VERSION ""

NS_ :

BS_:

BU_: PowertrainControlModule AtmosphericSensor SafetyRestraintSystem2 Aftertreatment_2_GasOutlet Aftertreatment_2_GasIntake DieselParticulateFilterControl Turbocharger SafetyRestraintSystem1 CabDisplay2 Aftertreatment_1_GasOutlet Aftertreatment_1_GasIntake OnBoardDataLogger OffBoardDiagnosticTool2 OffBoardDiagnosticTool1 FileServer ParkingBrakeController SeatController2 FanDriveController SteeringColumnUnit CommunicationUnitRadio CommunicationUnitSatellite CommunicationUnitCellular PropulsionBatteryCharger ChassisController2 ChassisController1 EngineValveControl AuxiliaryHeater2 AuxiliaryHeater1 ClutchUnit RampControl InformationSystem1 SuspensionSystemController2 OilSensor VehicleDynamicStability ExhaustEmissionController TransmissionDisplay2 TransmissionDisplay1 ClimateControl2 WaterPumpController RearAxleSteeringController LightingOperatorControl SeatController1 IgnitionController2 IgnitionController1 TirePressureController CabController2 CabController1 PneumaticSystemController SuspensionSystemController1 HydraulicPumpController EnduranceBrakingSystem RetarderExhaustEngine2 OnBoardDiagnosticUnit HeadwayController RetarderExhaustEngine1 CabDisplay1 ManagementComputer VirtualTerminal OffVehicleGateway PowerTakeOffFront HitchControl AuxiliaryValveControl BodyController TractorTrailerBridge1 StarterSystem ElectricalSystem VehicleSecurity VehicleNavigation AerodynamicControl ElectricalChargingSystem ClimateControl1 TripRecorder InstrumentCluster SuspensionDriveAxle2 SuspensionDriveAxle1 SuspensionSteerAxle SteeringController FuelSystem CruiseControl RetarderDriveline RetarderEngine BrakesDriveAxle2 BrakesDriveAxle1 BrakesSystemController BrakesSteerAxle AxleDrive2 AxleDrive1 AxleSteering PowerTakeOff ShiftConsoleSecondary ShiftConsolePrimary Transmission2 Transmission1 Engine2 Engine1

BO_ 2566786302 WSMEM: 8 Vector__XXX
 SG_ ReservedBit : 48|1@1+ (1,0) [0|0] "" Vector__XXX
 SG_ VehicleSystem5 m5 : 49|7@1+ (1,0) [0|127] "" Vector__XXX
 SG_ VehicleSystem4 m4 : 49|7@1+ (1,0) [0|127] "" Vector__XXX
 SG_ VehicleSystem3 m3 : 49|7@1+ (1,0) [0|127] "" Vector__XXX
 SG_ VehicleSystem2 m2 : 49|7@1+ (1,0) [0|127] "" Vector__XXX
 SG_ VehicleSystem1 m1 : 49|7@1+ (1,0) [0|127] "" Vector__XXX
 SG_ ArbitraryAddressCapable : 63|1@1+ (1,0) [0|1] "" Vector__XXX
 SG_ IndustryGroup M : 60|3@1+ (1,0) [0|7] "" Vector__XXX
 SG_ VehicleSystemInstance : 56|4@1+ (1,0) [0|15] "" Vector__XXX
 SG_ VehicleSystem m0 : 49|7@1+ (1,0) [0|127] "" Vector__XXX
 SG_ ECUInstance : 32|3@1+ (1,0) [0|7] "" Vector__XXX
 SG_ FunctionInstance : 35|5@1+ (1,0) [0|31] "" Vector__XXX
 SG_ Function : 40|8@1+ (1,0) [0|255] "" Vector__XXX
 SG_ ManufacturerCode : 21|11@1+ (1,0) [0|2047] "" Vector__XXX
 SG_ IdentityNumber : 0|21@1+ (1,0) [0|2097152] "" Vector__XXX

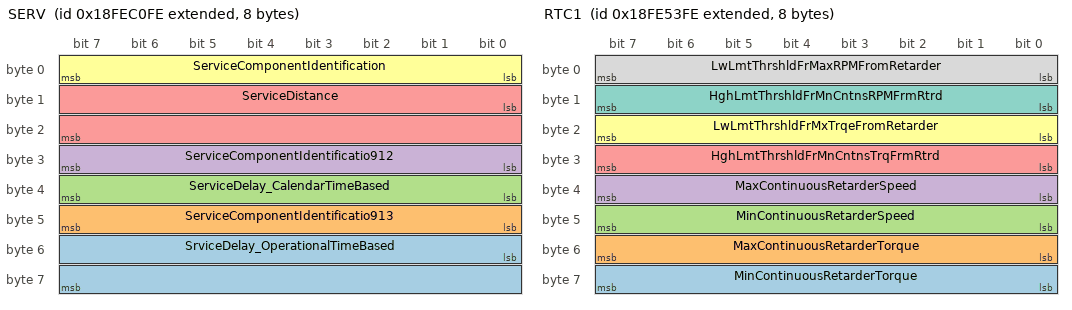
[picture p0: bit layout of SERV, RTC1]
BO_ 2566832382 SERV: 8 Vector__XXX
 SG_ SrviceDelay_OperationalTimeBased : 48|16@1+ (1,-32127) [-32127|32128] "h" Vector__XXX
 SG_ ServiceComponentIdentificatio913 : 40|8@1+ (1,0) [0|250] "ID" Vector__XXX
 SG_ ServiceDelay_CalendarTimeBased : 32|8@1+ (1,-125) [-125|125] "weeks" Vector__XXX
 SG_ ServiceComponentIdentificatio912 : 24|8@1+ (1,0) [0|250] "ID" Vector__XXX
 SG_ ServiceDistance : 8|16@1+ (5,-160635) [-160635|160640] "km" Vector__XXX
 SG_ ServiceComponentIdentification : 0|8@1+ (1,0) [0|250] "" Vector__XXX

BO_ 2633928446 S2: 8 Vector__XXX
 SG_ TimeSinceLastService : 8|16@1+ (1,-32127) [-32127|32128] "h" Vector__XXX
 SG_ ServiceComponentIdentification : 0|8@1+ (1,0) [0|250] "" Vector__XXX

BO_ 2566804478 RTC1: 8 Vector__XXX
 SG_ MinContinuousRetarderTorque : 56|8@1+ (1,-125) [-125|125] "%" Vector__XXX
 SG_ MaxContinuousRetarderTorque : 48|8@1+ (1,-125) [-125|125] "%" Vector__XXX
 SG_ MinContinuousRetarderSpeed : 40|8@1+ (32,0) [0|8000] "rpm" Vector__XXX
 SG_ MaxContinuousRetarderSpeed : 32|8@1+ (32,0) [0|8000] "rpm" Vector__XXX
 SG_ HghLmtThrshldFrMnCntnsTrqFrmRtrd : 24|8@1+ (1,-125) [-125|125] "%" Vector__XXX
 SG_ LwLmtThrshldFrMxTrqeFromRetarder : 16|8@1+ (1,-125) [-125|125] "%" Vector__XXX
 SG_ HghLmtThrshldFrMnCntnsRPMFrmRtrd : 8|8@1+ (32,0) [0|8000] "rpm" Vector__XXX
 SG_ LwLmtThrshldFrMaxRPMFromRetarder : 0|8@1+ (32,0) [0|8000] "rpm" Vector__XXX

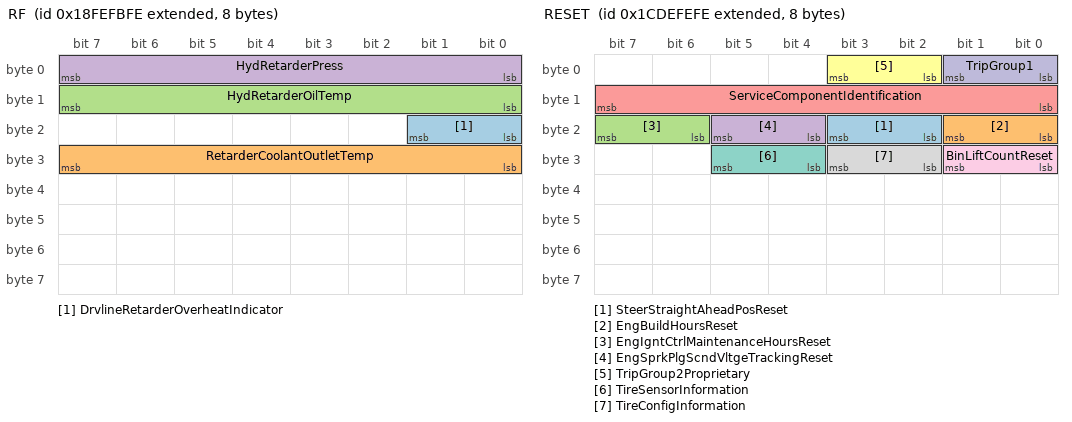
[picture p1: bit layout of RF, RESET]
BO_ 2566847486 RF: 8 Vector__XXX
 SG_ DrvlineRetarderOverheatIndicator : 16|2@1+ (1,0) [0|3] "" Vector__XXX
 SG_ RetarderCoolantOutletTemp : 24|8@1+ (1,-40) [-40|210] "캜" Vector__XXX
 SG_ HydRetarderOilTemp : 8|8@1+ (1,-40) [-40|210] "캜" Vector__XXX
 SG_ HydRetarderPress : 0|8@1+ (16,0) [0|4000] "kPa" Vector__XXX

BO_ 2631859966 RESET: 8 Vector__XXX
 SG_ SteerStraightAheadPosReset : 18|2@1+ (1,0) [0|3] "" Vector__XXX
 SG_ EngBuildHoursReset : 16|2@1+ (1,0) [0|3] "" Vector__XXX
 SG_ EngIgntCtrlMaintenanceHoursReset : 22|2@1+ (1,0) [0|3] "" Vector__XXX
 SG_ EngSprkPlgScndVltgeTrackingReset : 20|2@1+ (1,0) [0|3] "" Vector__XXX
 SG_ ServiceComponentIdentification : 8|8@1+ (1,0) [0|250] "" Vector__XXX
 SG_ TripGroup2Proprietary : 2|2@1+ (1,0) [0|3] "" Vector__XXX
 SG_ TireSensorInformation : 28|2@1+ (1,0) [0|3] "" Vector__XXX
 SG_ TireConfigInformation : 26|2@1+ (1,0) [0|3] "" Vector__XXX
 SG_ BinLiftCountReset : 24|2@1+ (1,0) [0|3] "" Vector__XXX
 SG_ TripGroup1 : 0|2@1+ (1,0) [0|3] "" Vector__XXX

BO_ 2566840830 RC: 19 Vector__XXX
 SG_ PercentTorqueAtPeakTorquePoint5 : 144|8@1+ (1,-125) [-125|0] "%" Vector__XXX
 SG_ ReferenceRetarderTorque : 128|16@1+ (1,0) [0|64255] "Nm" Vector__XXX
 SG_ RetarderSpeedAtPeakTorquePoint5 : 112|16@1+ (0.125,0) [0|8031.875] "rpm" Vector__XXX
 SG_ PercentTorqueAtPoint4 : 104|8@1+ (1,-125) [-125|0] "%" Vector__XXX
 SG_ RetarderSpeedAtPoint4 : 88|16@1+ (0.125,0) [0|8031.875] "rpm" Vector__XXX
 SG_ PercentTorqueAtPoint3 : 80|8@1+ (1,-125) [-125|0] "%" Vector__XXX
 SG_ RetarderSpeedAtPoint3 : 64|16@1+ (0.125,0) [0|8031.875] "rpm" Vector__XXX
 SG_ PercentTorqueAtMaxSpeedPoint2 : 56|8@1+ (1,-125) [-125|0] "%" Vector__XXX
 SG_ MaxRetarderSpeedPoint2 : 40|16@1+ (0.125,0) [0|8031.875] "rpm" Vector__XXX
 SG_ PercentTorqueAtIdlePoint1 : 32|8@1+ (1,-125) [-125|0] "%" Vector__XXX
 SG_ RetarderSpeedAtIdlePoint1 : 16|16@1+ (0.125,0) [0|8031.875] "rpm" Vector__XXX
 SG_ RetarderCtrlMethod : 8|8@1+ (1,0) [0|250] "steps" Vector__XXX
 SG_ RetarderLocation : 4|4@1+ (1,0) [0|15] "" Vector__XXX
 SG_ RetarderType : 0|4@1+ (1,0) [0|15] "" Vector__XXX

BO_ 2633930238 RBI: 8 Vector__XXX
 SG_ EngOperationTimeSinceRebuild : 0|32@1+ (1,0) [0|4211081215] "s" Vector__XXX

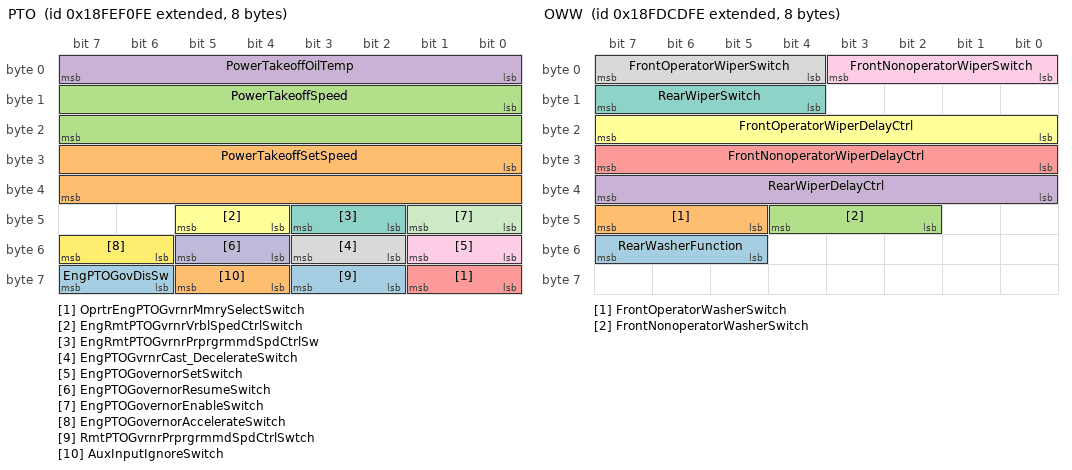
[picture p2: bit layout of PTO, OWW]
BO_ 2566844670 PTO: 8 Vector__XXX
 SG_ EngPTOGovDisSw : 62|2@1+ (1,0) [0|3] "" Vector__XXX
 SG_ PowerTakeoffSetSpeed : 24|16@1+ (0.125,0) [0|8031.875] "rpm" Vector__XXX
 SG_ PowerTakeoffSpeed : 8|16@1+ (0.125,0) [0|8031.875] "rpm" Vector__XXX
 SG_ PowerTakeoffOilTemp : 0|8@1+ (1,-40) [-40|210] "캜" Vector__XXX
 SG_ OprtrEngPTOGvrnrMmrySelectSwitch : 56|2@1+ (1,0) [0|3] "" Vector__XXX
 SG_ EngRmtPTOGvrnrVrblSpedCtrlSwitch : 44|2@1+ (1,0) [0|3] "" Vector__XXX
 SG_ EngRmtPTOGvrnrPrprgrmmdSpdCtrlSw : 42|2@1+ (1,0) [0|3] "" Vector__XXX
 SG_ EngPTOGvrnrCast_DecelerateSwitch : 50|2@1+ (1,0) [0|3] "" Vector__XXX
 SG_ EngPTOGovernorSetSwitch : 48|2@1+ (1,0) [0|3] "" Vector__XXX
 SG_ EngPTOGovernorResumeSwitch : 52|2@1+ (1,0) [0|3] "" Vector__XXX
 SG_ EngPTOGovernorEnableSwitch : 40|2@1+ (1,0) [0|3] "" Vector__XXX
 SG_ EngPTOGovernorAccelerateSwitch : 54|2@1+ (1,0) [0|3] "" Vector__XXX
 SG_ RmtPTOGvrnrPrprgrmmdSpdCtrlSwtch : 58|2@1+ (1,0) [0|3] "" Vector__XXX
 SG_ AuxInputIgnoreSwitch : 60|2@1+ (1,0) [0|3] "" Vector__XXX

BO_ 2566770174 OWW: 8 Vector__XXX
 SG_ RearWasherFunction : 53|3@1+ (1,0) [0|7] "" Vector__XXX
 SG_ FrontOperatorWasherSwitch : 45|3@1+ (1,0) [0|7] "" Vector__XXX
 SG_ FrontNonoperatorWasherSwitch : 42|3@1+ (1,0) [0|7] "" Vector__XXX
 SG_ RearWiperDelayCtrl : 32|8@1+ (0.4,0) [0|100] "%" Vector__XXX
 SG_ FrontNonoperatorWiperDelayCtrl : 24|8@1+ (0.4,0) [0|100] "%" Vector__XXX
 SG_ FrontOperatorWiperDelayCtrl : 16|8@1+ (0.4,0) [0|100] "%" Vector__XXX
 SG_ RearWiperSwitch : 12|4@1+ (1,0) [0|15] "" Vector__XXX
 SG_ FrontOperatorWiperSwitch : 4|4@1+ (1,0) [0|15] "" Vector__XXX
 SG_ FrontNonoperatorWiperSwitch : 0|4@1+ (1,0) [0|15] "" Vector__XXX

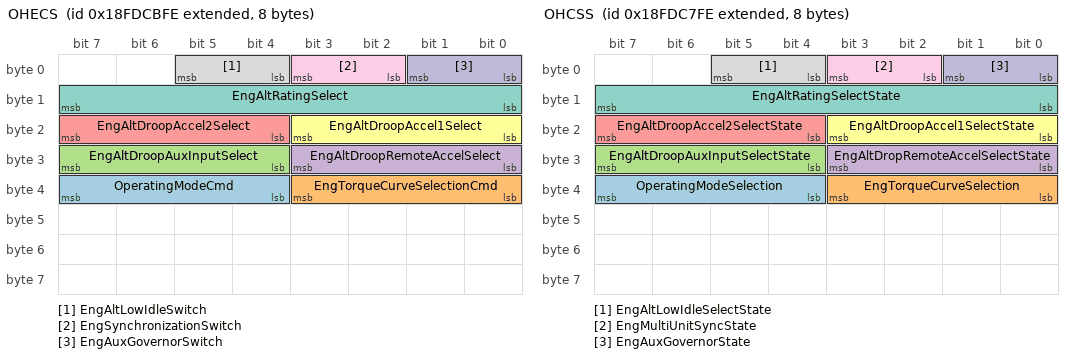
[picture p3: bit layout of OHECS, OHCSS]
BO_ 2566769662 OHECS: 8 Vector__XXX
 SG_ OperatingModeCmd : 36|4@1+ (1,0) [0|15] "" Vector__XXX
 SG_ EngTorqueCurveSelectionCmd : 32|4@1+ (1,0) [0|15] "" Vector__XXX
 SG_ EngAltDroopAuxInputSelect : 28|4@1+ (1,0) [0|15] "" Vector__XXX
 SG_ EngAltDroopRemoteAccelSelect : 24|4@1+ (1,0) [0|15] "" Vector__XXX
 SG_ EngAltDroopAccel2Select : 20|4@1+ (1,0) [0|15] "" Vector__XXX
 SG_ EngAltDroopAccel1Select : 16|4@1+ (1,0) [0|15] "" Vector__XXX
 SG_ EngAltRatingSelect : 8|8@1+ (1,0) [0|255] "" Vector__XXX
 SG_ EngAltLowIdleSwitch : 4|2@1+ (1,0) [0|3] "" Vector__XXX
 SG_ EngSynchronizationSwitch : 2|2@1+ (1,0) [0|3] "" Vector__XXX
 SG_ EngAuxGovernorSwitch : 0|2@1+ (1,0) [0|3] "" Vector__XXX

BO_ 2566768638 OHCSS: 8 Vector__XXX
 SG_ OperatingModeSelection : 36|4@1+ (1,0) [0|15] "" Vector__XXX
 SG_ EngTorqueCurveSelection : 32|4@1+ (1,0) [0|15] "" Vector__XXX
 SG_ EngAltDroopAuxInputSelectState : 28|4@1+ (1,0) [0|15] "" Vector__XXX
 SG_ EngAltDropRemoteAccelSelectState : 24|4@1+ (1,0) [0|15] "" Vector__XXX
 SG_ EngAltDroopAccel2SelectState : 20|4@1+ (1,0) [0|15] "" Vector__XXX
 SG_ EngAltDroopAccel1SelectState : 16|4@1+ (1,0) [0|15] "" Vector__XXX
 SG_ EngAltRatingSelectState : 8|8@1+ (1,0) [0|255] "" Vector__XXX
 SG_ EngAltLowIdleSelectState : 4|2@1+ (1,0) [0|3] "" Vector__XXX
 SG_ EngMultiUnitSyncState : 2|2@1+ (1,0) [0|3] "" Vector__XXX
 SG_ EngAuxGovernorState : 0|2@1+ (1,0) [0|3] "" Vector__XXX

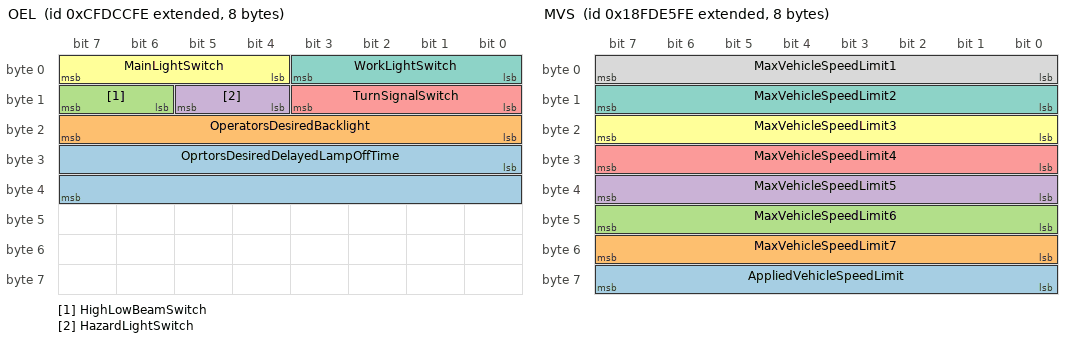
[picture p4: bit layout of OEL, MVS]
BO_ 2365443326 OEL: 8 Vector__XXX
 SG_ OprtorsDesiredDelayedLampOffTime : 24|16@1+ (1,0) [0|64255] "s" Vector__XXX
 SG_ OperatorsDesiredBacklight : 16|8@1+ (0.4,0) [0|100] "%" Vector__XXX
 SG_ HighLowBeamSwitch : 14|2@1+ (1,0) [0|3] "" Vector__XXX
 SG_ HazardLightSwitch : 12|2@1+ (1,0) [0|3] "" Vector__XXX
 SG_ TurnSignalSwitch : 8|4@1+ (1,0) [0|15] "" Vector__XXX
 SG_ MainLightSwitch : 4|4@1+ (1,0) [0|15] "" Vector__XXX
 SG_ WorkLightSwitch : 0|4@1+ (1,0) [0|15] "" Vector__XXX

BO_ 2566776318 MVS: 8 Vector__XXX
 SG_ AppliedVehicleSpeedLimit : 56|8@1+ (1,0) [0|250] "km/h" Vector__XXX
 SG_ MaxVehicleSpeedLimit7 : 48|8@1+ (1,0) [0|250] "km/h" Vector__XXX
 SG_ MaxVehicleSpeedLimit6 : 40|8@1+ (1,0) [0|250] "km/h" Vector__XXX
 SG_ MaxVehicleSpeedLimit5 : 32|8@1+ (1,0) [0|250] "km/h" Vector__XXX
 SG_ MaxVehicleSpeedLimit4 : 24|8@1+ (1,0) [0|250] "km/h" Vector__XXX
 SG_ MaxVehicleSpeedLimit3 : 16|8@1+ (1,0) [0|250] "km/h" Vector__XXX
 SG_ MaxVehicleSpeedLimit2 : 8|8@1+ (1,0) [0|250] "km/h" Vector__XXX
 SG_ MaxVehicleSpeedLimit1 : 0|8@1+ (1,0) [0|250] "km/h" Vector__XXX

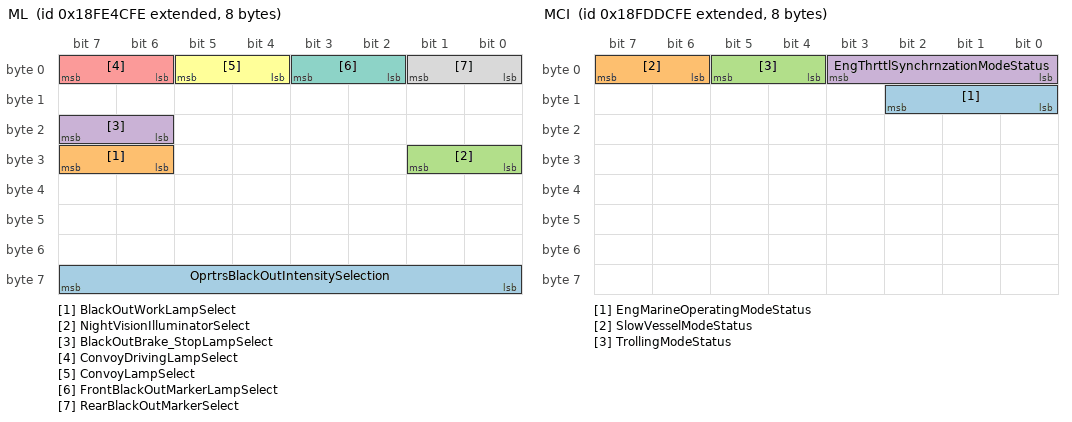
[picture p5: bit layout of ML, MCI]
BO_ 2566802686 ML: 8 Vector__XXX
 SG_ OprtrsBlackOutIntensitySelection : 56|8@1+ (0.4,0) [0|100] "%" Vector__XXX
 SG_ BlackOutWorkLampSelect : 30|2@1+ (1,0) [0|3] "" Vector__XXX
 SG_ NightVisionIlluminatorSelect : 24|2@1+ (1,0) [0|3] "" Vector__XXX
 SG_ BlackOutBrake_StopLampSelect : 22|2@1+ (1,0) [0|3] "" Vector__XXX
 SG_ ConvoyDrivingLampSelect : 6|2@1+ (1,0) [0|3] "" Vector__XXX
 SG_ ConvoyLampSelect : 4|2@1+ (1,0) [0|3] "" Vector__XXX
 SG_ FrontBlackOutMarkerLampSelect : 2|2@1+ (1,0) [0|3] "" Vector__XXX
 SG_ RearBlackOutMarkerSelect : 0|2@1+ (1,0) [0|3] "" Vector__XXX

BO_ 2566774014 MCI: 8 Vector__XXX
 SG_ EngMarineOperatingModeStatus : 8|3@1+ (1,0) [0|7] "" Vector__XXX
 SG_ SlowVesselModeStatus : 6|2@1+ (1,0) [0|3] "" Vector__XXX
 SG_ TrollingModeStatus : 4|2@1+ (1,0) [0|3] "" Vector__XXX
 SG_ EngThrttlSynchrnzationModeStatus : 0|4@1+ (1,0) [0|15] "" Vector__XXX

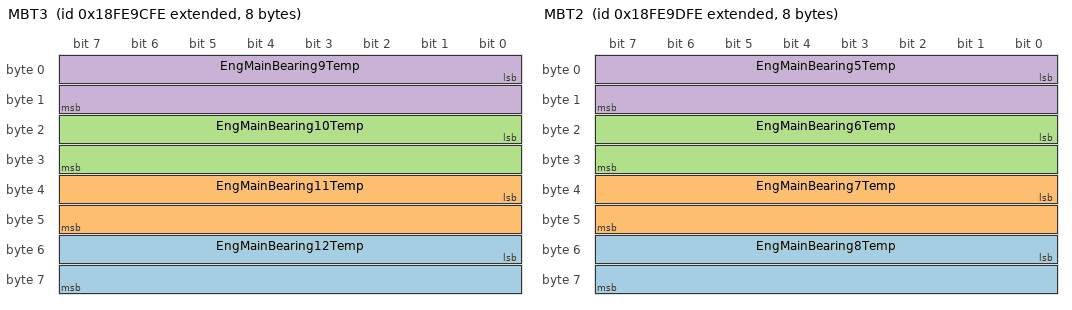
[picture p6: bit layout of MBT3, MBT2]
BO_ 2566823166 MBT3: 8 Vector__XXX
 SG_ EngMainBearing12Temp : 48|16@1+ (0.03125,-273) [-273|1734.96875] "캜" Vector__XXX
 SG_ EngMainBearing11Temp : 32|16@1+ (0.03125,-273) [-273|1734.96875] "캜" Vector__XXX
 SG_ EngMainBearing10Temp : 16|16@1+ (0.03125,-273) [-273|1734.96875] "캜" Vector__XXX
 SG_ EngMainBearing9Temp : 0|16@1+ (0.03125,-273) [-273|1734.96875] "캜" Vector__XXX

BO_ 2566823422 MBT2: 8 Vector__XXX
 SG_ EngMainBearing8Temp : 48|16@1+ (0.03125,-273) [-273|1734.96875] "캜" Vector__XXX
 SG_ EngMainBearing7Temp : 32|16@1+ (0.03125,-273) [-273|1734.96875] "캜" Vector__XXX
 SG_ EngMainBearing6Temp : 16|16@1+ (0.03125,-273) [-273|1734.96875] "캜" Vector__XXX
 SG_ EngMainBearing5Temp : 0|16@1+ (0.03125,-273) [-273|1734.96875] "캜" Vector__XXX

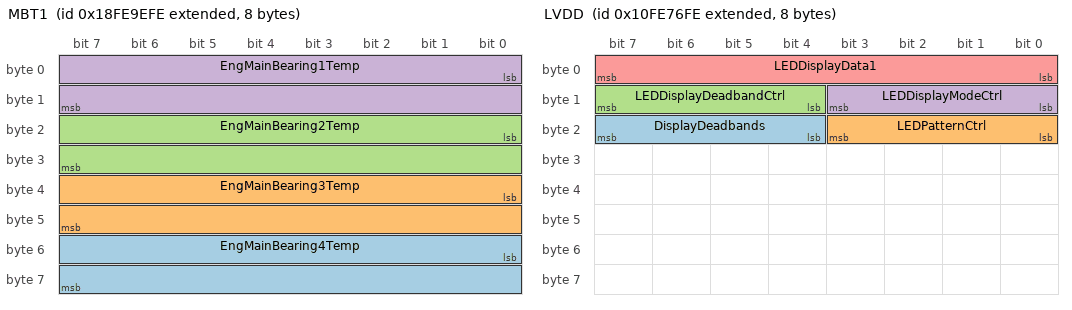
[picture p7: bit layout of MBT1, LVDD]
BO_ 2566823678 MBT1: 8 Vector__XXX
 SG_ EngMainBearing4Temp : 48|16@1+ (0.03125,-273) [-273|1734.96875] "캜" Vector__XXX
 SG_ EngMainBearing3Temp : 32|16@1+ (0.03125,-273) [-273|1734.96875] "캜" Vector__XXX
 SG_ EngMainBearing2Temp : 16|16@1+ (0.03125,-273) [-273|1734.96875] "캜" Vector__XXX
 SG_ EngMainBearing1Temp : 0|16@1+ (0.03125,-273) [-273|1734.96875] "캜" Vector__XXX

BO_ 2432595710 LVDD: 8 Vector__XXX
 SG_ DisplayDeadbands : 20|4@1+ (1,0) [0|15] "" Vector__XXX
 SG_ LEDPatternCtrl : 16|4@1+ (1,0) [0|15] "" Vector__XXX
 SG_ LEDDisplayDeadbandCtrl : 12|4@1+ (1,0) [0|15] "" Vector__XXX
 SG_ LEDDisplayModeCtrl : 8|4@1+ (1,0) [0|15] "" Vector__XXX
 SG_ LEDDisplayData1 : 0|8@1+ (1,0) [0|255] "" Vector__XXX

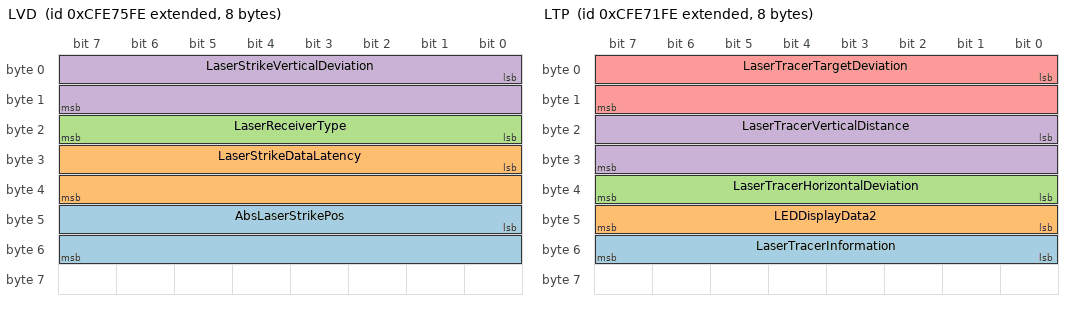
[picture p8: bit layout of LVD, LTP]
BO_ 2365486590 LVD: 8 Vector__XXX
 SG_ AbsLaserStrikePos : 40|16@1+ (0.1,0) [0|6425.5] "mm" Vector__XXX
 SG_ LaserStrikeDataLatency : 24|16@1+ (5.12E-005,0) [0|3.289856] "s" Vector__XXX
 SG_ LaserReceiverType : 16|8@1+ (1,0) [0|250] "" Vector__XXX
 SG_ LaserStrikeVerticalDeviation : 0|16@1+ (0.1,-3200) [-3200|3225.5] "mm" Vector__XXX

BO_ 2365485566 LTP: 8 Vector__XXX
 SG_ LaserTracerInformation : 48|8@1+ (1,0) [0|255] "" Vector__XXX
 SG_ LEDDisplayData2 : 40|8@1+ (1,0) [0|255] "" Vector__XXX
 SG_ LaserTracerHorizontalDeviation : 32|8@1+ (1,0) [0|200] "%" Vector__XXX
 SG_ LaserTracerVerticalDistance : 16|16@1+ (0.1,0) [0|6400] "mm" Vector__XXX
 SG_ LaserTracerTargetDeviation : 0|16@1+ (0.1,-3200) [-3200|3225.5] "mm" Vector__XXX

BO_ 2633939454 LTFI: 22 Vector__XXX
 SG_ TripDriveFuelEconomy : 160|16@1+ (0.001953125,0) [0|125.498046875] "km/L" Vector__XXX
 SG_ TripCruiseFuelUsed : 128|32@1+ (0.5,0) [0|2105540607.5] "l" Vector__XXX
 SG_ TripVehicleIdleFuelUsed : 96|32@1+ (0.5,0) [0|2105540607.5] "l" Vector__XXX
 SG_ TripPTOGovernorNonmovingFuelUsed : 64|32@1+ (0.5,0) [0|2105540607.5] "l" Vector__XXX
 SG_ TripPTOGovernorMovingFuelUsed : 32|32@1+ (0.5,0) [0|2105540607.5] "l" Vector__XXX
 SG_ TripDriveFuelUsed : 0|32@1+ (0.5,0) [0|2105540607.5] "l" Vector__XXX

BO_ 2365486334 LSP: 8 Vector__XXX
 SG_ BldeHeightSetPointHighResolution : 16|32@1+ (1E-007,-209.7152) [-209.7152|209.7152] "m" Vector__XXX
 SG_ ModifyLevelingSystemSetPoint : 0|16@1+ (0.1,-3200) [-3200|3225.5] "mm" Vector__XXX

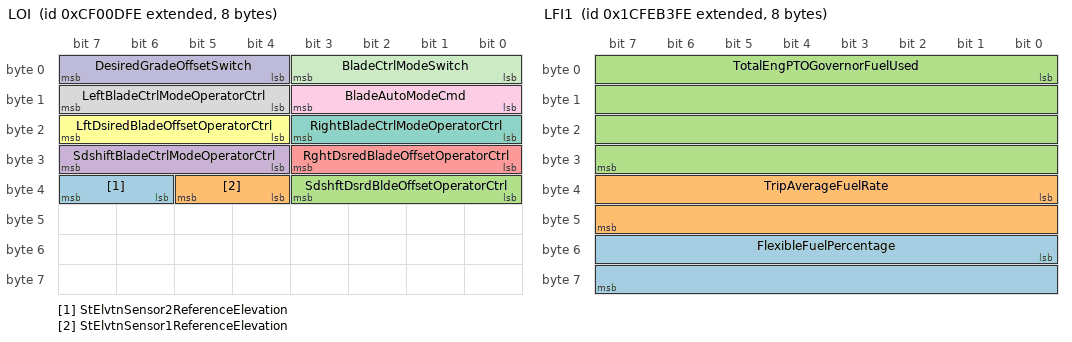
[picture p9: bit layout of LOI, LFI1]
BO_ 2364542462 LOI: 8 Vector__XXX
 SG_ StElvtnSensor2ReferenceElevation : 38|2@1+ (1,0) [0|3] "" Vector__XXX
 SG_ StElvtnSensor1ReferenceElevation : 36|2@1+ (1,0) [0|3] "" Vector__XXX
 SG_ SdshftDsrdBldeOffsetOperatorCtrl : 32|4@1+ (1,0) [0|15] "" Vector__XXX
 SG_ SdshiftBladeCtrlModeOperatorCtrl : 28|4@1+ (1,0) [0|15] "" Vector__XXX
 SG_ RghtDsredBladeOffsetOperatorCtrl : 24|4@1+ (1,0) [0|15] "" Vector__XXX
 SG_ LftDsiredBladeOffsetOperatorCtrl : 20|4@1+ (1,0) [0|15] "" Vector__XXX
 SG_ RightBladeCtrlModeOperatorCtrl : 16|4@1+ (1,0) [0|15] "" Vector__XXX
 SG_ LeftBladeCtrlModeOperatorCtrl : 12|4@1+ (1,0) [0|15] "" Vector__XXX
 SG_ BladeAutoModeCmd : 8|4@1+ (1,0) [0|15] "" Vector__XXX
 SG_ DesiredGradeOffsetSwitch : 4|4@1+ (1,0) [0|15] "" Vector__XXX
 SG_ BladeCtrlModeSwitch : 0|4@1+ (1,0) [0|15] "" Vector__XXX

BO_ 2365486078 LMP: 8 Vector__XXX
 SG_ MastPos : 0|16@1+ (0.1,-3200) [-3200|3225.5] "mm" Vector__XXX

BO_ 2633937918 LFI1: 8 Vector__XXX
 SG_ FlexibleFuelPercentage : 48|16@1+ (0.0025,0) [0|100] "%" Vector__XXX
 SG_ TripAverageFuelRate : 32|16@1+ (0.05,0) [0|3212.75] "l/h" Vector__XXX
 SG_ TotalEngPTOGovernorFuelUsed : 0|32@1+ (0.5,0) [0|2105540607.5] "l" Vector__XXX

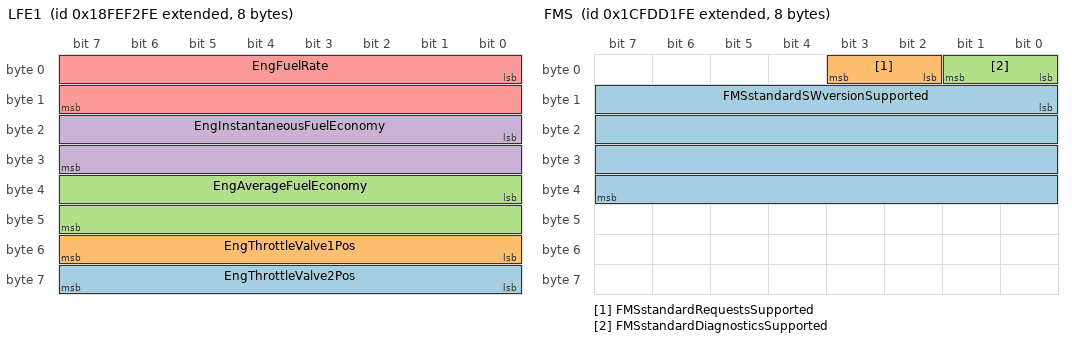
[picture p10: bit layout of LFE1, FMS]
BO_ 2566845182 LFE1: 8 Vector__XXX
 SG_ EngThrottleValve2Pos : 56|8@1+ (0.4,0) [0|100] "%" Vector__XXX
 SG_ EngThrottleValve1Pos : 48|8@1+ (0.4,0) [0|100] "%" Vector__XXX
 SG_ EngAverageFuelEconomy : 32|16@1+ (0.001953125,0) [0|125.498046875] "km/L" Vector__XXX
 SG_ EngInstantaneousFuelEconomy : 16|16@1+ (0.001953125,0) [0|125.498046875] "km/L" Vector__XXX
 SG_ EngFuelRate : 0|16@1+ (0.05,0) [0|3212.75] "l/h" Vector__XXX

BO_ 2566842878 LFC1: 8 Vector__XXX
 SG_ EngTotalFuelUsed : 32|32@1+ (0.5,0) [0|2105540607.5] "l" Vector__XXX
 SG_ EngTripFuel : 0|32@1+ (0.5,0) [0|2105540607.5] "l" Vector__XXX

BO_ 2633883646 FWD: 8 Vector__XXX
 SG_ FrontWheelDriveActuatorStatus : 0|2@1+ (1,0) [0|3] "" Vector__XXX

BO_ 2633880062 FMS: 8 Vector__XXX
 SG_ FMSstandardSWversionSupported : 8|32@1+ (1,0) [0|255] "" Vector__XXX
 SG_ FMSstandardRequestsSupported : 2|2@1+ (1,0) [0|3] "" Vector__XXX
 SG_ FMSstandardDiagnosticsSupported : 0|2@1+ (1,0) [0|3] "" Vector__XXX

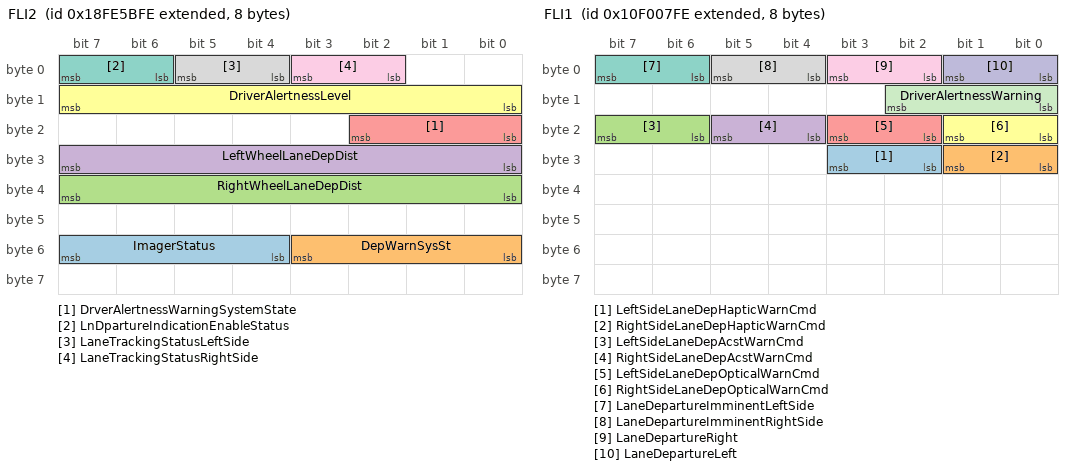
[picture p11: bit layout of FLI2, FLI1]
BO_ 2566806526 FLI2: 8 Vector__XXX
 SG_ ImagerStatus : 52|4@1+ (1,0) [0|15] "" Vector__XXX
 SG_ DepWarnSysSt : 48|4@1+ (1,0) [0|15] "" Vector__XXX
 SG_ RightWheelLaneDepDist : 32|8@1+ (1,-125) [-125|125] "cm" Vector__XXX
 SG_ LeftWheelLaneDepDist : 24|8@1+ (1,-125) [-125|125] "cm" Vector__XXX
 SG_ DrverAlertnessWarningSystemState : 16|3@1+ (1,0) [0|7] "" Vector__XXX
 SG_ DriverAlertnessLevel : 8|8@1+ (0.4,0) [0|100] "%" Vector__XXX
 SG_ LnDpartureIndicationEnableStatus : 6|2@1+ (1,0) [0|3] "" Vector__XXX
 SG_ LaneTrackingStatusLeftSide : 4|2@1+ (1,0) [0|3] "" Vector__XXX
 SG_ LaneTrackingStatusRightSide : 2|2@1+ (1,0) [0|3] "" Vector__XXX

BO_ 2431649790 FLI1: 8 Vector__XXX
 SG_ LeftSideLaneDepHapticWarnCmd : 26|2@1+ (1,0) [0|3] "" Vector__XXX
 SG_ RightSideLaneDepHapticWarnCmd : 24|2@1+ (1,0) [0|3] "" Vector__XXX
 SG_ LeftSideLaneDepAcstWarnCmd : 22|2@1+ (1,0) [0|3] "" Vector__XXX
 SG_ RightSideLaneDepAcstWarnCmd : 20|2@1+ (1,0) [0|3] "" Vector__XXX
 SG_ LeftSideLaneDepOpticalWarnCmd : 18|2@1+ (1,0) [0|3] "" Vector__XXX
 SG_ RightSideLaneDepOpticalWarnCmd : 16|2@1+ (1,0) [0|3] "" Vector__XXX
 SG_ LaneDepartureImminentLeftSide : 6|2@1+ (1,0) [0|3] "" Vector__XXX
 SG_ LaneDepartureImminentRightSide : 4|2@1+ (1,0) [0|3] "" Vector__XXX
 SG_ LaneDepartureRight : 2|2@1+ (1,0) [0|3] "" Vector__XXX
 SG_ LaneDepartureLeft : 0|2@1+ (1,0) [0|3] "" Vector__XXX
 SG_ DriverAlertnessWarning : 8|3@1+ (1,0) [0|7] "" Vector__XXX

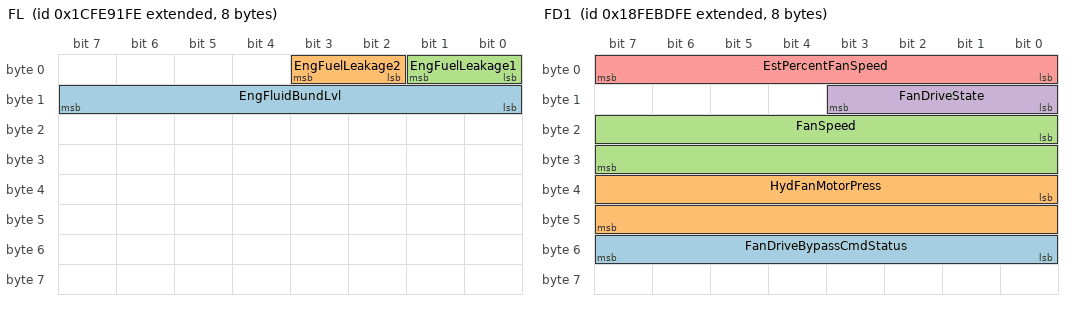
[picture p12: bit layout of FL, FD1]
BO_ 2633929214 FL: 8 Vector__XXX
 SG_ EngFluidBundLvl : 8|8@1+ (0.4,0) [0|100] "%" Vector__XXX
 SG_ EngFuelLeakage2 : 2|2@1+ (1,0) [0|3] "" Vector__XXX
 SG_ EngFuelLeakage1 : 0|2@1+ (1,0) [0|3] "" Vector__XXX

BO_ 2566831614 FD1: 8 Vector__XXX
 SG_ FanDriveBypassCmdStatus : 48|8@1+ (0.4,0) [0|100] "%" Vector__XXX
 SG_ HydFanMotorPress : 32|16@1+ (0.5,0) [0|32127.5] "kPa" Vector__XXX
 SG_ FanSpeed : 16|16@1+ (0.125,0) [0|8031.875] "rpm" Vector__XXX
 SG_ FanDriveState : 8|4@1+ (1,0) [0|15] "" Vector__XXX
 SG_ EstPercentFanSpeed : 0|8@1+ (0.4,0) [0|100] "%" Vector__XXX

BO_ 2566820094 ETH: 8 Vector__XXX
 SG_ EngTorqueLimit6AxleInput : 248|16@1+ (2,0) [0|128510] "Nm" Vector__XXX
 SG_ EngTorqueLimit5Switch : 232|16@1+ (1,0) [0|64255] "Nm" Vector__XXX
 SG_ EngTorqueLimit4Trans : 216|16@1+ (1,0) [0|64255] "Nm" Vector__XXX
 SG_ EngTorqueLimit3Trans : 200|16@1+ (1,0) [0|64255] "Nm" Vector__XXX
 SG_ TransGearRatio3 : 184|16@1+ (0.01,0) [0|642.55] "" Vector__XXX
 SG_ EngTorqueLimit2Trans : 168|16@1+ (1,0) [0|64255] "Nm" Vector__XXX
 SG_ TransGearRatio2 : 152|16@1+ (0.01,0) [0|642.55] "" Vector__XXX
 SG_ EngTorqueLimit1Trans : 136|16@1+ (1,0) [0|64255] "Nm" Vector__XXX
 SG_ TransGearRatio1 : 120|16@1+ (0.01,0) [0|642.55] "" Vector__XXX
 SG_ EngTorqueLimitFeature : 114|3@1+ (1,0) [0|7] "" Vector__XXX
 SG_ TorqueLimitingFeatureStatus : 112|2@1+ (1,0) [0|3] "" Vector__XXX
 SG_ CalibRecordDurationTime : 80|32@1+ (0.05,0) [0|210554060.75] "h" Vector__XXX
 SG_ CalibRecordStartYear : 72|8@1+ (1,1985) [1985|2235] "years" Vector__XXX
 SG_ CalibRecordStartDay : 64|8@1+ (0.25,0) [0.25|31.75] "days" Vector__XXX
 SG_ CalibRecordStartMonth : 56|8@1+ (1,0) [1|12] "months" Vector__XXX
 SG_ EngPeakTorque2 : 40|16@1+ (1,0) [0|64255] "Nm" Vector__XXX
 SG_ EngPeakTorque1 : 24|16@1+ (1,0) [0|64255] "Nm" Vector__XXX
 SG_ EngPower : 8|16@1+ (0.5,0) [0|32127.5] "kW" Vector__XXX
 SG_ NumberOfEngTorqueHistoryRecords : 0|8@1+ (1,0) [0|250] "records" Vector__XXX

BO_ 2364542206 ETC8: 8 Vector__XXX
 SG_ TransClutch_ConverterInputSpeed : 16|16@1+ (0.125,0) [0|8031.875] "rpm" Vector__XXX
 SG_ TransTorqueConverterRatio : 0|16@1+ (0.001,0) [0|64.255] "" Vector__XXX

BO_ 2566802174 ETC7: 8 Vector__XXX
 SG_ ManualModeInd : 54|2@1+ (1,0) [0|3] "" Vector__XXX
 SG_ TransAutoNeutralSt : 51|3@1+ (1,0) [0|7] "" Vector__XXX
 SG_ TransWarningIndicator : 42|2@1+ (1,0) [0|3] "" Vector__XXX
 SG_ TrnsRverseGearShiftInhibitStatus : 40|2@1+ (1,0) [0|3] "" Vector__XXX
 SG_ TransMode8Indicator : 38|2@1+ (1,0) [0|3] "" Vector__XXX
 SG_ TransMode7Indicator : 36|2@1+ (1,0) [0|3] "" Vector__XXX
 SG_ TransMode6Indicator : 34|2@1+ (1,0) [0|3] "" Vector__XXX
 SG_ TransMode5Indicator : 32|2@1+ (1,0) [0|3] "" Vector__XXX
 SG_ TransRequestedGearFeedback : 24|8@1+ (1,-125) [-125|125] "" Vector__XXX
 SG_ TransMode1Indicator : 22|2@1+ (1,0) [0|3] "" Vector__XXX
 SG_ TransMode2Indicator : 20|2@1+ (1,0) [0|3] "" Vector__XXX
 SG_ TransMode3Indicator : 18|2@1+ (1,0) [0|3] "" Vector__XXX
 SG_ TransMode4Indicator : 16|2@1+ (1,0) [0|3] "" Vector__XXX
 SG_ TransShiftInhibitIndicator : 14|2@1+ (1,0) [0|3] "" Vector__XXX
 SG_ TransEngCrankEnable : 12|2@1+ (1,0) [0|3] "" Vector__XXX
 SG_ ActiveShiftConsoleIndicator : 10|2@1+ (1,0) [0|3] "" Vector__XXX
 SG_ TransReadyForBrakeRelease : 8|2@1+ (1,0) [0|3] "" Vector__XXX
 SG_ TrnsRqstedRangeDisplayFlashState : 6|2@1+ (1,0) [0|3] "" Vector__XXX
 SG_ TrnsRqstedRangeDisplayBlankState : 4|2@1+ (1,0) [0|3] "" Vector__XXX
 SG_ TransServiceIndicator : 2|2@1+ (1,0) [0|3] "" Vector__XXX
 SG_ TransAirSupplyPressIndicator : 48|3@1+ (1,0) [0|7] "" Vector__XXX
 SG_ TransMode10Indicator : 46|2@1+ (1,0) [0|3] "" Vector__XXX
 SG_ TransMode9Indicator : 44|2@1+ (1,0) [0|3] "" Vector__XXX
 SG_ TrnsCrrentRangeDisplayBlankState : 0|2@1+ (1,0) [0|3] "" Vector__XXX

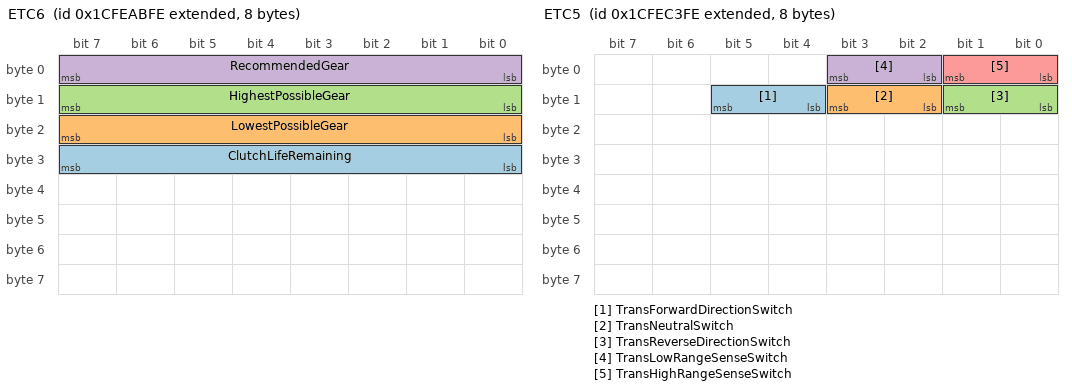
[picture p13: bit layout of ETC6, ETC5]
BO_ 2633935870 ETC6: 8 Vector__XXX
 SG_ ClutchLifeRemaining : 24|8@1+ (0.4,0) [0|100] "%" Vector__XXX
 SG_ LowestPossibleGear : 16|8@1+ (1,-125) [-125|125] "" Vector__XXX
 SG_ HighestPossibleGear : 8|8@1+ (1,-125) [-125|125] "" Vector__XXX
 SG_ RecommendedGear : 0|8@1+ (1,-125) [-125|125] "" Vector__XXX

BO_ 2633942014 ETC5: 8 Vector__XXX
 SG_ TransForwardDirectionSwitch : 12|2@1+ (1,0) [0|3] "" Vector__XXX
 SG_ TransNeutralSwitch : 10|2@1+ (1,0) [0|3] "" Vector__XXX
 SG_ TransReverseDirectionSwitch : 8|2@1+ (1,0) [0|3] "" Vector__XXX
 SG_ TransLowRangeSenseSwitch : 2|2@1+ (1,0) [0|3] "" Vector__XXX
 SG_ TransHighRangeSenseSwitch : 0|2@1+ (1,0) [0|3] "" Vector__XXX

BO_ 2633942526 ETC4: 8 Vector__XXX
 SG_ TransSynchronizerBrakeValue : 8|8@1+ (0.4,0) [0|100] "%" Vector__XXX
 SG_ TransSynchronizerClutchValue : 0|8@1+ (0.4,0) [0|100] "%" Vector__XXX

BO_ 2633943038 ETC3: 8 Vector__XXX
 SG_ TransInertiaBrakeActuator : 46|2@1+ (1,0) [0|3] "" Vector__XXX
 SG_ TransDefuelActuator : 44|2@1+ (1,0) [0|3] "" Vector__XXX
 SG_ TransLockupClutchActuator : 42|2@1+ (1,0) [0|3] "" Vector__XXX
 SG_ TransClutchActuator : 40|2@1+ (1,0) [0|3] "" Vector__XXX
 SG_ TransSplitterIndirectActuator : 38|2@1+ (1,0) [0|3] "" Vector__XXX
 SG_ TransSplitterDirectActuator : 36|2@1+ (1,0) [0|3] "" Vector__XXX
 SG_ TransRangeLowActuator : 34|2@1+ (1,0) [0|3] "" Vector__XXX
 SG_ TransRangeHighActuator : 32|2@1+ (1,0) [0|3] "" Vector__XXX
 SG_ TransShiftFingerGearActuator2 : 30|2@1+ (1,0) [0|3] "" Vector__XXX
 SG_ TransShiftFingerRailActuator2 : 28|2@1+ (1,0) [0|3] "" Vector__XXX
 SG_ TransShiftFingerGearActuator1 : 26|2@1+ (1,0) [0|3] "" Vector__XXX
 SG_ TransShiftFingerRailActuator1 : 24|2@1+ (1,0) [0|3] "" Vector__XXX
 SG_ TrnsShftFngerCenterRailIndicator : 20|2@1+ (1,0) [0|3] "" Vector__XXX
 SG_ TrnsShftFngerEngagementIndicator : 18|2@1+ (1,0) [0|3] "" Vector__XXX
 SG_ TransShiftFingerNeutralIndicator : 16|2@1+ (1,0) [0|3] "" Vector__XXX
 SG_ TransShiftFingerRailPos : 8|8@1+ (0.4,0) [0|100] "%" Vector__XXX
 SG_ TransShiftFingerGearPos : 0|8@1+ (0.4,0) [0|100] "%" Vector__XXX

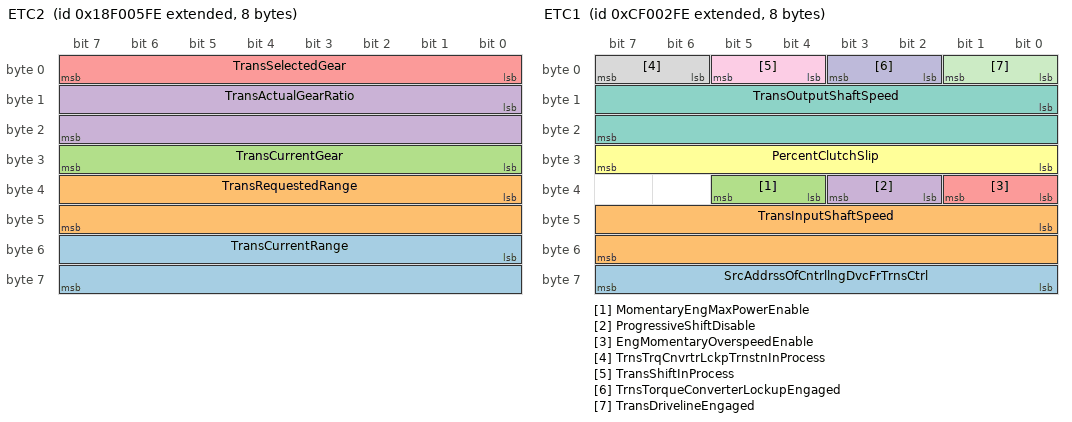
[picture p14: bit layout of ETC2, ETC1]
BO_ 2565867006 ETC2: 8 Vector__XXX
 SG_ TransCurrentRange : 48|16@1+ (1,0) [0|255] "" Vector__XXX
 SG_ TransRequestedRange : 32|16@1+ (1,0) [0|255] "" Vector__XXX
 SG_ TransCurrentGear : 24|8@1+ (1,-125) [-125|125] "" Vector__XXX
 SG_ TransActualGearRatio : 8|16@1+ (0.001,0) [0|64.255] "" Vector__XXX
 SG_ TransSelectedGear : 0|8@1+ (1,-125) [-125|125] "" Vector__XXX

BO_ 2364539646 ETC1: 8 Vector__XXX
 SG_ SrcAddrssOfCntrllngDvcFrTrnsCtrl : 56|8@1+ (1,0) [0|253] "" Vector__XXX
 SG_ TransInputShaftSpeed : 40|16@1+ (0.125,0) [0|8031.875] "rpm" Vector__XXX
 SG_ MomentaryEngMaxPowerEnable : 36|2@1+ (1,0) [0|3] "" Vector__XXX
 SG_ ProgressiveShiftDisable : 34|2@1+ (1,0) [0|3] "" Vector__XXX
 SG_ EngMomentaryOverspeedEnable : 32|2@1+ (1,0) [0|3] "" Vector__XXX
 SG_ PercentClutchSlip : 24|8@1+ (0.4,0) [0|100] "%" Vector__XXX
 SG_ TransOutputShaftSpeed : 8|16@1+ (0.125,0) [0|8031.875] "rpm" Vector__XXX
 SG_ TrnsTrqCnvrtrLckpTrnstnInProcess : 6|2@1+ (1,0) [0|3] "" Vector__XXX
 SG_ TransShiftInProcess : 4|2@1+ (1,0) [0|3] "" Vector__XXX
 SG_ TrnsTorqueConverterLockupEngaged : 2|2@1+ (1,0) [0|3] "" Vector__XXX
 SG_ TransDrivelineEngaged : 0|2@1+ (1,0) [0|3] "" Vector__XXX

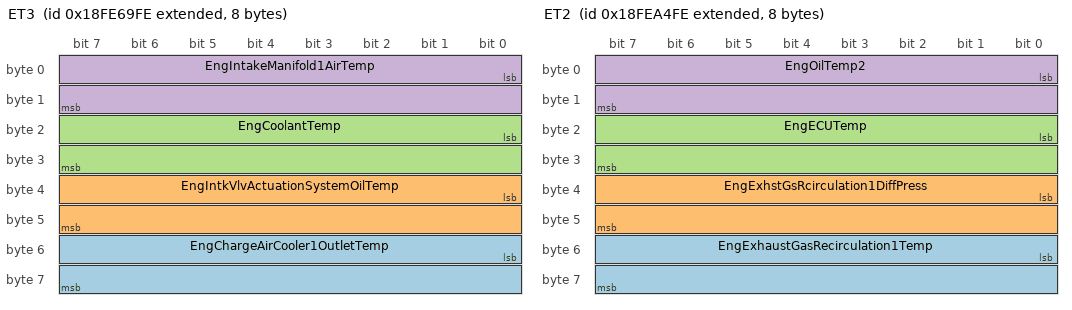
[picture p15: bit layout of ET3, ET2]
BO_ 2566810110 ET3: 8 Vector__XXX
 SG_ EngChargeAirCooler1OutletTemp : 48|16@1+ (0.03125,-273) [-273|1734.96875] "캜" Vector__XXX
 SG_ EngIntkVlvActuationSystemOilTemp : 32|16@1+ (0.03125,-273) [-273|1734.96875] "캜" Vector__XXX
 SG_ EngCoolantTemp : 16|16@1+ (0.03125,-273) [-273|1734.96875] "캜" Vector__XXX
 SG_ EngIntakeManifold1AirTemp : 0|16@1+ (0.03125,-273) [-273|1734.96875] "캜" Vector__XXX

BO_ 2566825214 ET2: 8 Vector__XXX
 SG_ EngExhaustGasRecirculation1Temp : 48|16@1+ (0.03125,-273) [-273|1734.96875] "캜" Vector__XXX
 SG_ EngExhstGsRcirculation1DiffPress : 32|16@1+ (0.0078125,-250) [-250|251.99] "kPa" Vector__XXX
 SG_ EngECUTemp : 16|16@1+ (0.03125,-273) [-273|1734.96875] "캜" Vector__XXX
 SG_ EngOilTemp2 : 0|16@1+ (0.03125,-273) [-273|1734.96875] "캜" Vector__XXX

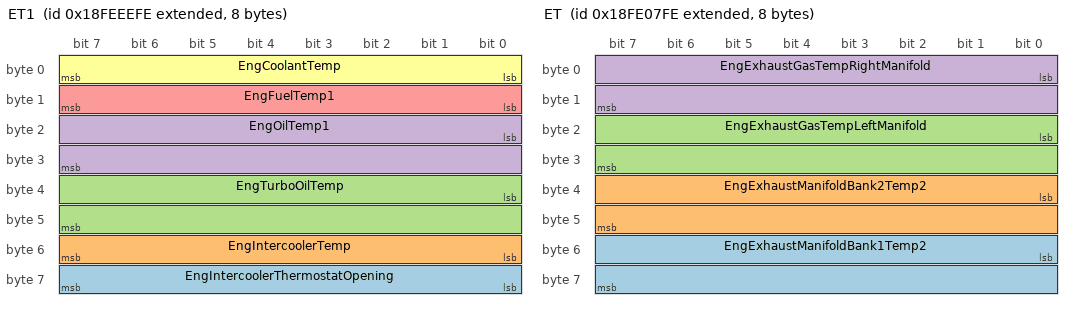
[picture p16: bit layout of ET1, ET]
BO_ 2566844158 ET1: 8 Vector__XXX
 SG_ EngIntercoolerThermostatOpening : 56|8@1+ (0.4,0) [0|100] "%" Vector__XXX
 SG_ EngIntercoolerTemp : 48|8@1+ (1,-40) [-40|210] "캜" Vector__XXX
 SG_ EngTurboOilTemp : 32|16@1+ (0.03125,-273) [-273|1734.96875] "캜" Vector__XXX
 SG_ EngOilTemp1 : 16|16@1+ (0.03125,-273) [-273|1734.96875] "캜" Vector__XXX
 SG_ EngFuelTemp1 : 8|8@1+ (1,-40) [-40|210] "캜" Vector__XXX
 SG_ EngCoolantTemp : 0|8@1+ (1,-40) [-40|210] "캜" Vector__XXX

BO_ 2566785022 ET: 8 Vector__XXX
 SG_ EngExhaustManifoldBank1Temp2 : 48|16@1+ (0.03125,-273) [-273|1734.96875] "캜" Vector__XXX
 SG_ EngExhaustManifoldBank2Temp2 : 32|16@1+ (0.03125,-273) [-273|1734.96875] "캜" Vector__XXX
 SG_ EngExhaustGasTempLeftManifold : 16|16@1+ (0.03125,-273) [-273|1734.96875] "캜" Vector__XXX
 SG_ EngExhaustGasTempRightManifold : 0|16@1+ (0.03125,-273) [-273|1734.96875] "캜" Vector__XXX

CM_ BO_ 2566786302 "Working Set Member
This message is sent by the Master of a Working Set to identify an individual member of a specific Working Set (Master뭩 Source Address identifies the particular Working Set).";
CM_ SG_ 2566786302 IndustryGroup "0 = Global; 
   1  = On-Highway; 
   2  = Agricultural and Forestry; 
   3  = Construction; 
   4  = Marine;
   5  = Industrial - Process
          Control - Stationary (Gen-Sets)
   6  = Reserve for SAE
   7  = Reserve for SAE";
CM_ SG_ 2566786302 ManufacturerCode "Assigned by NMEA 2000 Committee";
CM_ BO_ 2566832382 "Service Information
Transmitted with the service component identification that has the shortest distance or nearest time until the next service inspection.
NOTE - There are two acceptable formats for the Service PGN.  Format 1 has only 8 bytes of ...";
CM_ SG_ 2566832382 SrviceDelay_OperationalTimeBased "The time in vehicle operational time until the next vehicle service inspection is required.  A negative value is transmitted if the service inspection has been passed.  The component that requires service is identified by the service component ...";
CM_ SG_ 2566832382 ServiceComponentIdentificatio913 "Identification of component needing service.  See Table SPN911_A.";
CM_ SG_ 2566832382 ServiceDelay_CalendarTimeBased "The time in weeks until the next vehicle service inspection is required.  A negative value is transmitted if the service inspection has been passed.  The component that requires service is identified by the service component identification (see SPN ...";
CM_ SG_ 2566832382 ServiceComponentIdentificatio912 "Identification of component needing service.  See Table SPN911_A.";
CM_ SG_ 2566832382 ServiceDistance "The distance which can be traveled by the vehicle before the next service inspection is required.  A negative distance is transmitted if the service inspection has been passed.  The component that requires service is identified by the service ...";
CM_ SG_ 2566832382 ServiceComponentIdentification "Identification of component needing service.  See Table SPN911_A.";
CM_ BO_ 2633928446 "Service 2
NOTE - There are two acceptable formats for the Service PGN.  Format 1 has only 8 bytes of data and reports the component most in need of service for each of the three categories.  Format 2, however, uses the transport protocol as ...";
CM_ SG_ 2633928446 TimeSinceLastService "The vehicle operation time since the last service was performed.  The type of service information is identified by the service component identification number.";
CM_ SG_ 2633928446 ServiceComponentIdentification "Identification of component needing service.  See Table SPN911_A.";
CM_ BO_ 2566804478 "Retarder Continuous Torque & Speed Limit";
CM_ SG_ 2566804478 MinContinuousRetarderTorque "Applied limit for minimum continuous retarder torque";
CM_ SG_ 2566804478 MaxContinuousRetarderTorque "Applied limit for maximum continuous retarder torque.";
CM_ SG_ 2566804478 MinContinuousRetarderSpeed "Applied limit for minimum continuous retarder RPM";
CM_ SG_ 2566804478 MaxContinuousRetarderSpeed "Applied limit for maximum continuous retarder RPM";
CM_ SG_ 2566804478 HghLmtThrshldFrMnCntnsTrqFrmRtrd "Maximum allowable value for minimum continuous retarder torque.";
CM_ SG_ 2566804478 LwLmtThrshldFrMxTrqeFromRetarder "Minimum allowable value for maximum continuous retarder torque.";
CM_ SG_ 2566804478 HghLmtThrshldFrMnCntnsRPMFrmRtrd "Maximum allowable value for minimum continuous retarder speed";
CM_ SG_ 2566804478 LwLmtThrshldFrMaxRPMFromRetarder "Minimum allowable value for maximum continuous retarder speed";
CM_ BO_ 2566847486 "Retarder fluids";
CM_ SG_ 2566847486 DrvlineRetarderOverheatIndicator "Signal from the driveline retarder indicating that its fluid temperature is above normal acceptable limits, and as a result, retarder operation may be altered or restricted.  The indicator is typically a lamp.  Distinctions in meaning between the ...";
CM_ SG_ 2566847486 RetarderCoolantOutletTemp "Temperature of liquid found in retarder cooling system.";
CM_ SG_ 2566847486 HydRetarderOilTemp "Temperature of oil found in a hydraulic retarder.";
CM_ SG_ 2566847486 HydRetarderPress "Gage pressure of oil in hydraulic retarder system.";
CM_ BO_ 2631859966 "Reset
NOTE뾗his message requires an Acknowledgement response (See J1939-21, PGN 59392) from the receiving node.  The use of individual proprietary protocols can still be used instead of the \"trip reset\" PGN to maintain security.";
CM_ SG_ 2631859966 SteerStraightAheadPosReset "Used to reset the straight ahead position for a steering sensor in the steering column or a steering controller's straight ahead position on any steerable axle.
00 Take no action - Do not Reset
01 Reset
10 Reserved, take no action
11 Not ...";
CM_ SG_ 2631859966 EngBuildHoursReset "Command signal used to reset the engine rebuild hours.

00 Do not reset
01 Reset
10 Reserved
11 Take no action";
CM_ SG_ 2631859966 EngIgntCtrlMaintenanceHoursReset "Used to reset the maintenance hour counter for an engine ignition control module.  The hours remaining until required maintenance is performed are reported in PGN 64688.

00 Do not reset
01 Reset
10 Reserved
11 Take no action";
CM_ SG_ 2631859966 EngSprkPlgScndVltgeTrackingReset "Command signal used to reset the ignition controller average, maximum, and minimum level tracking of the spark plug secondary voltages and to reset the learned misfire rate.  Average secondary voltage tracking is reported in PGNs 64882 - 64887 ...";
CM_ SG_ 2631859966 ServiceComponentIdentification "Identification of component needing service.  See Table SPN911_A.";
CM_ SG_ 2631859966 TripGroup2Proprietary "Command signal used to reset proprietary parameters associated with a trip but not defined within this document.

00 Take no action
01 Reset
10 Reserved
11 Not applicable";
CM_ SG_ 2631859966 TireSensorInformation "Command signal used to initiate change in the tire sensor identification information.

00 Take no action
01 Reset
10 Reserved
11 Not applicable";
CM_ SG_ 2631859966 TireConfigInformation "Command signal used to initiate change in the tire configuration of the vehicle system. On receipt of this reset, necessary changes will be made in the tire configuration command information.
00 - Take No Action
01 - Reset
10 - Reserved
11 - Not ...";
CM_ SG_ 2631859966 BinLiftCountReset "Used to reset the bin lift count as reported in PGN 64594.

00 Do not reset
01 Reset
10 Reserved
11 Take no action";
CM_ SG_ 2631859966 TripGroup1 "Command signal used to reset the PGNs and parameters as defined in Table SPN988_A.

00 Take no action
01 Reset
10 Reserved
11 Not applicable";
CM_ BO_ 2566840830 "Retarder Configuration
This map describes the stationary behavior of the retarder.
Note:  Grandfathered definition for systems that implemented this message prior to July, 2010: On change of torque/speed points of more than 10% since last ...";
CM_ SG_ 2566840830 PercentTorqueAtPeakTorquePoint5 "The torque limit that indicates the available retarder torque which can be provided by the retarder at point 5 of the retarder torque map.  Please reference PGN 65249.  The data is transmitted in indicated torque as a percent of the reference ...";
CM_ SG_ 2566840830 ReferenceRetarderTorque "This parameter is the 100% reference value for all defined indicated retarder torque parameters.  It is only defined once and doesn't change if a different retarder torque map becomes valid.";
CM_ SG_ 2566840830 RetarderSpeedAtPeakTorquePoint5 "Please reference PGN 65249";
CM_ SG_ 2566840830 PercentTorqueAtPoint4 "The torque limit that indicates the available retarder torque which can be provided by the retarder at points 3 and 4 of the retarder torque map.  Please reference PGN 65249.  The data is transmitted in indicated torque as a percent of the reference ...";
CM_ SG_ 2566840830 RetarderSpeedAtPoint4 "Retarder speed of point 4 of the engine retarder torque map.  Please reference PGN 65249.";
CM_ SG_ 2566840830 PercentTorqueAtPoint3 "The torque limit that indicates the available retarder torque which can be provided by the retarder at points 3 and 4 of the retarder torque map.  Please reference PGN 65249.  The data is transmitted in indicated torque as a percent of the reference ...";
CM_ SG_ 2566840830 RetarderSpeedAtPoint3 "Retarder speed of point 3 of the engine retarder torque map.  Please reference PGN 65249.";
CM_ SG_ 2566840830 PercentTorqueAtMaxSpeedPoint2 "The torque limit that indicates the available retarder torque which can be provided by the retarder at its maximum speed.  Please reference PGN 65249.  The data is transmitted in indicated torque as a percent of the reference retarder torque.";
CM_ SG_ 2566840830 MaxRetarderSpeedPoint2 "Maximum speed of retarder (Please reference PGN 65249).";
CM_ SG_ 2566840830 PercentTorqueAtIdlePoint1 "The torque limit that indicates the available retarder torque which can be provided by the retarder at idle speed.  The data is transmitted in indicated torque as a percent of the reference retarder torque.";
CM_ SG_ 2566840830 RetarderSpeedAtIdlePoint1 "Please reference PGN 65249";
CM_ SG_ 2566840830 RetarderCtrlMethod "This parameter identifies the number of steps used by the retarder.";
CM_ SG_ 2566840830 RetarderLocation "This parameter defines whether the 뱓orque/speed curve� defined by the retarder configuration message (PGN 65249) is dependent on engine rpm, output shaft rpm, or other parameter.  The data type of this parameter is measured.
0000  (Primary) ...";
CM_ SG_ 2566840830 RetarderType "A vehicle retarder is a supplementary device to the wheel brakes for the driver to better control the vehicle.  The wheel brakes used in the vehicle are not designed for continuous retarding operation.  In a prolonged period of braking, the brakes ...";
CM_ BO_ 2633930238 "Rebuild Information";
CM_ SG_ 2633930238 EngOperationTimeSinceRebuild "The time in engine operation since the last engine rebuild.";
CM_ BO_ 2566844670 "Power Takeoff Information";
CM_ SG_ 2566844670 EngPTOGovDisSw "Customer or body builder installed switch to prevent operation of engine in PTO mode.

00 - Off (PTO mode allowed)
01 - On (PTO mode is not allowed)
10 - Error
11 - Not Available";
CM_ SG_ 2566844670 PowerTakeoffSetSpeed "Rotational velocity selected by operator for device used to transmit engine power to auxiliary equipment.";
CM_ SG_ 2566844670 PowerTakeoffSpeed "Rotational velocity of device used to transmit engine power to auxiliary equipment.";
CM_ SG_ 2566844670 PowerTakeoffOilTemp "Temperature of lubricant in device used to transmit engine power to auxiliary equipment.";
CM_ SG_ 2566844670 OprtrEngPTOGvrnrMmrySelectSwitch "Measured state of the operator뭩 engine PTO governor memory select switch. This switch selects which of the two available memory locations is to be used to store the dynamically assigned value. This speed will be set using the PTO governor set ...";
CM_ SG_ 2566844670 EngRmtPTOGvrnrVrblSpedCtrlSwitch "Switch signal which indicates that the remote PTO governor toggle switch is in the enabled (ON) position.  If the toggle switch is enabled and other conditions are satisfied then the remote PTO governor feature is activated and the PTO governor will ...";
CM_ SG_ 2566844670 EngRmtPTOGvrnrPrprgrmmdSpdCtrlSw "Switch signal which indicates that the remote PTO governor  toggle switch is in the enabled (ON) position.  If the toggle switch is enabled and other conditions are satisfied then the remote PTO governor feature is activated and the PTO governor ...";
CM_ SG_ 2566844670 EngPTOGvrnrCast_DecelerateSwitch "Switch signal of the PTO control activator which indicates that the activator is in the position to \"coast/decelerate\" the PTO governor set speed.

00 - Off
01 - On
10 - Error
11 - Not available";
CM_ SG_ 2566844670 EngPTOGovernorSetSwitch "Switch signal of the PTO control activator which indicates that the activator is in the position to \"set\" the engine PTO governor set speed.

00 - Off
01 - On
10 - Error
11 - Not available";
CM_ SG_ 2566844670 EngPTOGovernorResumeSwitch "Switch signal of the PTO control activator which indicates that the activator is in the position to \"resume\" a previously established PTO governor set speed.

00 - Off
01 - On
10 - Error
11 - Not available";
CM_ SG_ 2566844670 EngPTOGovernorEnableSwitch "Switch signal which indicates that the PTO governor toggle switch is in the enabled (ON) position and therefore it is possible to manage the PTO control function.

00 - Off
01 - On
10 - Error
11 - Not available";
CM_ SG_ 2566844670 EngPTOGovernorAccelerateSwitch "Switch signal of the PTO control activator which indicates that the activator is in the position to \"accelerate\" the PTO governor set speed.

00 - Off
01 - On
10 - Error
11 - Not available";
CM_ SG_ 2566844670 RmtPTOGvrnrPrprgrmmdSpdCtrlSwtch "Switch signal which indicates that the remote PTO governor toggle switch #2 is in the enabled (ON) position. If the toggle switch is enabled and other conditions are satisfied then the remote PTO governor control feature is activated and the PTO ...";
CM_ SG_ 2566844670 AuxInputIgnoreSwitch "Switch signal which overrides other switch input's ability to disable an engine's operating condition.
00 - Off
01 - On
10 - Error
11 - Not Available
This switch input can be used to prevent the PTO from disengaging if another switch input's ...";
CM_ BO_ 2566770174 "Operator Wiper and Washer Controls Message
Message for items related to the operators controls for the window wipers and washers on the front and rear cab windows";
CM_ SG_ 2566770174 RearWasherFunction "State of operation selected by operator switch for the rear washer.   The parameter, 'Front Operator Washer Switch� should be used for the control information if this parameter is 'Not Available' and the associated washer still needs to be ...";
CM_ SG_ 2566770174 FrontOperatorWasherSwitch "State of operation selected by operator switch for the washer in front of the operator position. This parameter, 'Front Operator Washer Switch� should be used for the control information if either of the other washer switch parameters  is 'Not ...";
CM_ SG_ 2566770174 FrontNonoperatorWasherSwitch "State of operation selected by operator switch for the front washer not in front of the operator position.  The parameter, 'Front Operator Washer Switch� should be used for the control information if this parameter  is 'Not Available' and the ...";
CM_ SG_ 2566770174 RearWiperDelayCtrl "Time between cycles of the rear wiper (i.e. from end of cycle 'n' to start of cycle 'n+1') as selected by the operator control (switch, etc.) in percentage of position with maximum position corresponding to maximum delay selectable.  The parameter, ...";
CM_ SG_ 2566770174 FrontNonoperatorWiperDelayCtrl "Time between cycles of the front non-operator side wiper (i.e. from end of cycle 'n' to start of cycle 'n+1') as selected by the operator control (switch, etc.) in percentage of position with maximum position corresponding to maximum delay ...";
CM_ SG_ 2566770174 FrontOperatorWiperDelayCtrl "Time between cycles of the front operator side wiper (i.e. from end of cycle 'n' to start of cycle 'n+1') as selected by the operator control (switch, etc.) in percentage of position with maximum position corresponding to maximum delay selectable ...";
CM_ SG_ 2566770174 RearWiperSwitch "State of operation selected by operator switch for the rear wiper.  The parameter, 'Front Operator Washer Switch' should be used for the control information if this parameter is 'Not Available' and the associated washer still needs to be controlled.
 ...";
CM_ SG_ 2566770174 FrontOperatorWiperSwitch "State of operation selected by operator switch for the Wiper in front of the operator position. This parameter, 'Front Operator Wiper Switch' should be used for the control information if either of the other wiper switch parameters is 'Not ...";
CM_ SG_ 2566770174 FrontNonoperatorWiperSwitch "State of operation selected by operator switch for the front wiper not in front of the operator position.  The parameter, 'Front Operator Washer Switch' should be used for the control information if this parameter is 'Not Available' and the ...";
CM_ BO_ 2566769662 "Off-Highway Engine Control Selection
Allows for the selection of off-highway engine control modes, as they apply to different modes of engine operation which may be used to aid particular working environments. By offering characteristics suitable ...";
CM_ SG_ 2566769662 OperatingModeCmd "Command signal identifying the desired preconfigured engine operating mode. In some off-highway applications it may be desirable to have multiple preconfigured operating modes available for selection by the operator. Examples would be an economy ...";
CM_ SG_ 2566769662 EngTorqueCurveSelectionCmd "This parameter will allow selection of a torque curve that is higher than the base curve.
0 - Indicates that this parameter is not presently requesting a different torque curve be used
1 - Indicates that Torque Curve 1 is selected
2 - Indicates ...";
CM_ SG_ 2566769662 EngAltDroopAuxInputSelect "In some off-highway applications it may be desirable to have multiple droop settings available across the range of engine operation.  For example, in an agricultural tractor application, this functionality allows a higher engine speed during low ...";
CM_ SG_ 2566769662 EngAltDroopRemoteAccelSelect "In some off-highway applications it may be desirable to have multiple droop settings available across the range of engine operation.  For example, in an agricultural tractor application, this functionality allows a higher engine speed during low ...";
CM_ SG_ 2566769662 EngAltDroopAccel2Select "In some off-highway applications it may be desirable to have multiple droop settings available across the range of engine operation.  For example, in an agricultural tractor application, this functionality allows a higher engine speed during low ...";
CM_ SG_ 2566769662 EngAltDroopAccel1Select "In some off-highway applications it may be desirable to have multiple droop settings available across the range of engine operation.  For example, in an agricultural tractor application, this functionality allows a higher engine speed during low ...";
CM_ SG_ 2566769662 EngAltRatingSelect "In some off-highway applications it may be desirable to have multiple engine ratings available for selection by the operator. There is the default engine rating, which provides the maximum available power across the range of operation. There are ...";
CM_ SG_ 2566769662 EngAltLowIdleSwitch "Operator switch which selects between two low idle speeds, default and alternate.
The normal programmed low idle is the default low idle, and when the Alternate Low Idle switch is activated, a alternate preprogrammed low idle speed is selected. The ...";
CM_ SG_ 2566769662 EngSynchronizationSwitch "This is the On/Off operation of the Multiple Unit Synchronization functionality. When it is enabled (i.e. On) the master engine will synchronize one or more slave engines to operate at the same speed. This switch position indicates whether this ...";
CM_ SG_ 2566769662 EngAuxGovernorSwitch "This is the On/Off operation of the Auxiliary Governor feature switch. This feature is used to allow engine speed to be controlled by an auxiliary input such as pressure or tailshaft speed. This switch position indicates whether this feature is ...";
CM_ BO_ 2566768638 "Off-Highway Engine Control Selection States
Reports the states of off-highway engine control modes, as they apply to different modes of engine operation which may be used to aid particular working environments. These states provide the controls ...";
CM_ SG_ 2566768638 OperatingModeSelection "Identifies the current engine operating mode. In some off-highway applications it may be desirable to have multiple preconfigured operating modes available for selection by the operator. Examples would be an economy mode, a plowing mode or a PTO ...";
CM_ SG_ 2566768638 EngTorqueCurveSelection "This parameter will report the selected torque curve, as indicated by SPN 6796.
0 - Indicates that the engine is using a torque that is not presently selected by SPN 6796
1 - Indicates that Torque Curve 1 is selected
2 - Indicates that Torque ...";
CM_ SG_ 2566768638 EngAltDroopAuxInputSelectState "In some off-highway applications it may be desirable to have multiple droop settings available across the range of engine operation.  For example, in an agricultural tractor application, this functionality allows a higher engine speed during low ...";
CM_ SG_ 2566768638 EngAltDropRemoteAccelSelectState "In some off-highway applications it may be desirable to have multiple droop settings available across the range of engine operation.  For example, in an agricultural tractor application, this functionality allows a higher engine speed during low ...";
CM_ SG_ 2566768638 EngAltDroopAccel2SelectState "In some off-highway applications it may be desirable to have multiple droop settings available across the range of engine operation.  For example, in an agricultural tractor application, this functionality allows a higher engine speed during low ...";
CM_ SG_ 2566768638 EngAltDroopAccel1SelectState "In some off-highway applications it may be desirable to have multiple droop settings available across the range of engine operation.  For example, in an agricultural tractor application, this functionality allows a higher engine speed during low ...";
CM_ SG_ 2566768638 EngAltRatingSelectState "This parameter reflects the control state that has been achieved based on the input from the SPN 2882.  In some off-highway applications it may be desirable to have multiple engine ratings available for selection by the operator.  There is the ...";
CM_ SG_ 2566768638 EngAltLowIdleSelectState "In many applications, it is desirable that an alternate low idle speed setting be made available via switch input. The normal programmed low idle is the default low idle, and when the Alternate Low Idle feature is activated, an alternate ...";
CM_ SG_ 2566768638 EngMultiUnitSyncState "This feature is widely used in Industry to operate multiple engines from a single command source. A master engine will 뱒ynchronize� one or more slave engines to operate at the same speed. This feature is requested by an operator switch, this ...";
CM_ SG_ 2566768638 EngAuxGovernorState "This is the Engine Auxiliary Governor feature. This feature is used to allow engine speed to be controlled by an auxiliary input such as pressure or tailshaft speed. This feature is requested by an operator switch, this parameter indicates the state ...";
CM_ BO_ 2365443326 "Operators External Light Controls Message
The message containing the information about the position of the operator's external light control switch(s).  Including switches for the Headlights, turn signals, hazard light, clearance lights, marker ...";
CM_ SG_ 2365443326 OprtorsDesiredDelayedLampOffTime "A 16 bit parameter to be associated with Delayed Off position (1000 binary) of the Main Light Switch.  This parameter indicates the time the operator wishes to have elapse following the Main Light switch being placed in Delayed Off position before ...";
CM_ SG_ 2365443326 OperatorsDesiredBacklight "A 8 bit parameter to indicate the level of back lighting the operator has selected for displays.  This is to be differentiated from the Illumination Brightness Percent (SPN:1487 PGN:53248 Cab Illumination Message) which is sent to the displays to ...";
CM_ SG_ 2365443326 HighLowBeamSwitch "A 2 bit parameter to indicate the selected position of the operator's high/low beam select switch.

00  Low Beam Selected
01  High Beam Selected
10  Error
11  Not available (do not change)";
CM_ SG_ 2365443326 HazardLightSwitch "A 2 bit parameter to indicate the selected position of the operator's hazard light switch.

00   Hazard Lamps to be Off
01   Hazard Lamps to be Flashing
10   Error
11   Not available (do not change)";
CM_ SG_ 2365443326 TurnSignalSwitch "A 4 bit parameter to indicate the selected position of the operator's turn signal switch.
0000   No Turn being signaled
0001   Left Turn to be Flashing
0010   Right turn to be Flashing
0011 - 1101   Reserved
1110   Error (to include both left ...";
CM_ SG_ 2365443326 MainLightSwitch "A 4 bit parameter to indicate the selected position of the operator's main light switch.
0000  Off - The position by which the operator selects that none of the lamps are to be on.
0001  Park On - The position by which the operator selects that ...";
CM_ SG_ 2365443326 WorkLightSwitch "A 4 bit parameter to indicate the selected position of the operator's work light switch. In Ag applications the work lights are often refereed to as field lights.  In on-highway applications the work lights are often referred to as clearance lights ...";
CM_ BO_ 2566776318 "Maximum Vehicle Speed Limit Status
Reports the possible maximum vehicle speed limits, one through seven, and the applied maximum vehicle speed limit.";
CM_ SG_ 2566776318 AppliedVehicleSpeedLimit "The vehicle speed limit in effect.

251 (0xFB) is used to indicate that a maximum vehicle speed limit is not selected.

See SPN 7420 for alternate resolution.";
CM_ SG_ 2566776318 MaxVehicleSpeedLimit7 "The highest of the seven lowest vehicle speed limits";
CM_ SG_ 2566776318 MaxVehicleSpeedLimit6 "The highest of the six lowest vehicle speed limits";
CM_ SG_ 2566776318 MaxVehicleSpeedLimit5 "The highest of the five lowest vehicle speed limits";
CM_ SG_ 2566776318 MaxVehicleSpeedLimit4 "The highest of the four lowest vehicle speed limits";
CM_ SG_ 2566776318 MaxVehicleSpeedLimit3 "The highest of the three lowest vehicle speed limits";
CM_ SG_ 2566776318 MaxVehicleSpeedLimit2 "The highest of the two lowest vehicle speed limits";
CM_ SG_ 2566776318 MaxVehicleSpeedLimit1 "The lowest Maximum Vehicle Speed Limit. This value is the similar to SPN 74. However, SPN 74 was not specifically defined to convey  the applied vehicle speed limit or what was possible to be applied. This new SPN is the lowest vehicle speed limit ...";
CM_ BO_ 2566802686 "Military Lighting Command
The message contains parameters that control military specific lights.";
CM_ SG_ 2566802686 OprtrsBlackOutIntensitySelection "Operators Selection of lamp intensity in black out mode.  This parameter provides the operators selected illumination intensity as a percentage of available full scale.  This parameter would be typically used as a dash or instrument cluster ...";
CM_ SG_ 2566802686 BlackOutWorkLampSelect "Black Out Work Lamp Selection

00 Off
01 On
10 Reserved
11 Not Supported";
CM_ SG_ 2566802686 NightVisionIlluminatorSelect "Night Vision Illuminator Selection

00 Off
01 On
10 Reserved
11 Not Supported";
CM_ SG_ 2566802686 BlackOutBrake_StopLampSelect "Black Out Brake/Stop Lamp Selection

00 Off
01 On
10 Reserved
11 Not Supported";
CM_ SG_ 2566802686 ConvoyDrivingLampSelect "Black Out Convoy Driving Lamp Selection

00 Off
01 On
10 Reserved
11 Not Supported";
CM_ SG_ 2566802686 ConvoyLampSelect "Black Out Convoy Lamp Selection

00 Off
01 On
10 Reserved
11 Not Supported";
CM_ SG_ 2566802686 FrontBlackOutMarkerLampSelect "Front Black Out Marker Lamp Selection

00 Off
01 On
10 Reserved
11 Not Supported";
CM_ SG_ 2566802686 RearBlackOutMarkerSelect "Rear Black Out Marker Selection

00 Off
01 On
10 Reserved
11 Not Supported";
CM_ BO_ 2566774014 "Marine Control Information
This messages contains marine vessel control information for the engine";
CM_ SG_ 2566774014 EngMarineOperatingModeStatus "The operating mode of the engine for marine functions.
000 - Maintenance Mode
001 - Electrical Power Generation (EPG) mode
010 - Propulsion Constant Speed Mode
011 - Propulsion Variable Speed Mode
100 to 101 - Reserved
110 - Error
111 - Not ...";
CM_ SG_ 2566774014 SlowVesselModeStatus "The status of the Slow Vessel Mode.  Slow Vessel Mode puts the engine in a lower-than-normal low idle speed during docking or other slow vessel operations.
00 Slow vessel mode is OFF.
01 Slow vessel mode is ACTIVE.
10 Reserved
11 Take no action
 ...";
CM_ SG_ 2566774014 TrollingModeStatus "The status of the Trolling Mode.  Trolling mode limits the top speed.  Full range travel of the throttle level spans from low idle engine speed to maximum trolling speed.
See Trolling Mode (Extended Range) - SPN 9657 for alternate range and ...";
CM_ SG_ 2566774014 EngThrttlSynchrnzationModeStatus "The status of the Throttle Synchronization Mode. Throttle Synchronization Mode is used to indicate which throttle, if any, is currently being used for the synchronized throttle.
0000 Not Synchronized
0001 Synchronized Center
0010 Synchronized ...";
CM_ BO_ 2566823166 "Main Bearing Temperature 3";
CM_ SG_ 2566823166 EngMainBearing12Temp "Temperature of the main bearing which supports the crankshaft of the engine.";
CM_ SG_ 2566823166 EngMainBearing11Temp "Temperature of the main bearing which supports the crankshaft of the engine.";
CM_ SG_ 2566823166 EngMainBearing10Temp "Temperature of the main bearing which supports the crankshaft of the engine.";
CM_ SG_ 2566823166 EngMainBearing9Temp "Temperature of the main bearing which supports the crankshaft of the engine.";
CM_ BO_ 2566823422 "Main Bearing Temperature 2";
CM_ SG_ 2566823422 EngMainBearing8Temp "Temperature of the main bearing which supports the crankshaft of the engine.";
CM_ SG_ 2566823422 EngMainBearing7Temp "Temperature of the main bearing which supports the crankshaft of the engine.";
CM_ SG_ 2566823422 EngMainBearing6Temp "Temperature of the main bearing which supports the crankshaft of the engine.";
CM_ SG_ 2566823422 EngMainBearing5Temp "Temperature of the main bearing which supports the crankshaft of the engine.";
CM_ BO_ 2566823678 "Main Bearing Temperature 1";
CM_ SG_ 2566823678 EngMainBearing4Temp "Temperature of the main bearing which supports the crankshaft of the engine.";
CM_ SG_ 2566823678 EngMainBearing3Temp "Temperature of the main bearing which supports the crankshaft of the engine.";
CM_ SG_ 2566823678 EngMainBearing2Temp "Temperature of the main bearing which supports the crankshaft of the engine.";
CM_ SG_ 2566823678 EngMainBearing1Temp "Temperature of the main bearing which supports the crankshaft of the engine.";
CM_ BO_ 2432595710 "Laser Leveling System Vertical Position Display Data";
CM_ SG_ 2432595710 DisplayDeadbands "Sets Display Deadbands mode.

0000 - Narrow = +/- 4.5mm
0001 - Standard = +/- 12mm
0010 - Wide = +/- 24mm
0011 - 1110 Reserved
1111 Not Available";
CM_ SG_ 2432595710 LEDPatternCtrl "Sets LED Pattern control mode on laser leveling systems.

0000 - 5 Channel
0001 - Offset
0010 - 7 Channel
0011 - 1110 Reserved
1111 Not Available";
CM_ SG_ 2432595710 LEDDisplayDeadbandCtrl "This parameter informs the system what the selected Display deadband will be.
0000    +/- 4.5 mm  (0.015 feet, 0.18 inches)
0001    +/- 12 mm   (0.040 feet, 0.45 inches)
0010    +/- 24 mm   (0.080 feet, 0.96 inches)
0011    +/- 5  mm    (0.017 ...";
CM_ SG_ 2432595710 LEDDisplayModeCtrl "This parameter informs the system what the selected Display mode will be.
0000 - Center On-Grade Display Mode 1 ( 5 CHANNEL )
0001 - Offset On-Grade Display Mode
0010 - Center On-Grade Display Mode 2 ( 7 CHANNEL )
0011 - 1110 Reserved
1111 - ...";
CM_ SG_ 2432595710 LEDDisplayData1 "Informs display devices how to display the current vertical position.
Values which are less than 128 decimal are bit-mapped values and any combination of these values is considered a valid value.  For example communicating the \"High Fine LED on\" ...";
CM_ BO_ 2365486590 "Laser Leveling System Vertical Deviation";
CM_ SG_ 2365486590 AbsLaserStrikePos "Laser Strike location on the survey type  laser receiver.";
CM_ SG_ 2365486590 LaserStrikeDataLatency "Time from laser strike to CAN message transmission.  This parameter will be reported by survey receiver type devices only. Byte 3 (SPN 2576) of  PGN 65141 identifies the type of Laser Receiver.";
CM_ SG_ 2365486590 LaserReceiverType "Identifies which type of Laser Receiver transmitted the message.

0 = Reserved 
1 = Linear Laser Receiver
2 = 1 Meter Survey Receiver
3 = 2 Meter Survey Receiver
4 = 2.5 Meter Survey Receiver
5-250 = Reserved";
CM_ SG_ 2365486590 LaserStrikeVerticalDeviation "The calculated distance from the laser strike position to the current land leveling system reference point.";
CM_ BO_ 2365485566 "Laser Tracer Position";
CM_ SG_ 2365485566 LaserTracerInformation "Provides the status of the laser tracer to the operator.
00000001 Laser power is on
00000010 Laser is ready
00000100 Valid target (1 = yes)
00001000 Previous pass (1 = yes)
00010000 Stringline (1 = yes)
00100000 Curb (1 = yes)
All other ...";
CM_ SG_ 2365485566 LEDDisplayData2 "Informs display devices how to display the current position of the laser tracer.
Values which are less than 128 decimal are bit-mapped values and any combination of these values is considered a valid value.  For example communicating the \"Up LED ...";
CM_ SG_ 2365485566 LaserTracerHorizontalDeviation "The calculated percent deviation between the target distance and the center of the laser tracer.";
CM_ SG_ 2365485566 LaserTracerVerticalDistance "The elevation of the laser tracer sensor in a laser leveling system.";
CM_ SG_ 2365485566 LaserTracerTargetDeviation "The calculated distance for the laser target to the current laser tracer reference point.

Parameter specific parameter: 0xFE03 indicates that the sensor can not sense the laser";
CM_ BO_ 2633939454 "Trip Fuel Information (Liquid)";
CM_ SG_ 2633939454 TripDriveFuelEconomy "Trip drive fuel economy is equal to the distance traveled by vehicle in the drive state (engine speed greater than zero, vehicle speed greater than or equal to 2 km/h, and neither the PTO or remote PTO governors are controlling engine power output) ...";
CM_ SG_ 2633939454 TripCruiseFuelUsed "Total fuel consumed while the engine is in the cruise hold state since the last trip reset.  If both cruise control and VSL (vehicle speed limiter) are commanding the same amount of fuel, the cruise control is deemed the active torque mode and fuel ...";
CM_ SG_ 2633939454 TripVehicleIdleFuelUsed "Total fuel consumed while neither the PTO or remote PTO governor is in the hold state, the engine speed is greater than zero, and vehicle speed is less than 2 km/h, since the last trip reset.
In marine applications, this parameter is defined as the ...";
CM_ SG_ 2633939454 TripPTOGovernorNonmovingFuelUsed "Total fuel consumed while either the PTO or remote PTO governors are in the hold state, the engine speed is greater than zero, and vehicle speed is less than 2 km/h, since the last trip reset.
NOTE뾗his parameter is intended for liquid fueled ...";
CM_ SG_ 2633939454 TripPTOGovernorMovingFuelUsed "Total fuel consumed while either the PTO or remote PTO governors are in the hold state, the engine speed is greater than zero, and vehicle speed is greater than or equal to 2 km/h, since the last trip reset.
NOTE뾗his parameter is intended for ...";
CM_ SG_ 2633939454 TripDriveFuelUsed "Total fuel consumed while the engine speed is greater than zero, vehicle speed is greater than or equal to 2 km/h, and neither the PTO or the remote PTO is controlling the engine power output, since the last trip reset.
NOTE뾗his parameter is ...";
CM_ BO_ 2365486334 "Modify Leveling System Control Set Point";
CM_ SG_ 2365486334 BldeHeightSetPointHighResolution "High resolution for the laser guided blade set point.  The high resolution required for more accurate control and 'accurate' unit conversions.

Negative values are below grade, positive values are above grade, zero is on grade.";
CM_ SG_ 2365486334 ModifyLevelingSystemSetPoint "Used to control and coordinate the set point for the leveling system.
Operating Range: -3200 to +3200 mm, negative values are below current position, positive values are above current position, zero is no change.
Parameter specific parameter:
 ...";
CM_ BO_ 2364542462 "Land Leveling System Operational Information
Group of operational parameters associated with the Land Leveling System, such as switch states.    This is provided to the device controlling the blade, and is usually directed at the primary land ...";
CM_ SG_ 2364542462 StElvtnSensor2ReferenceElevation "Command from a display or other external device (i.e. remote switch) to the land leveling system controller instructing the controller to set the reference elvation based on data received from the corresponding land leveling sensor.
00 = Do not Set ...";
CM_ SG_ 2364542462 StElvtnSensor1ReferenceElevation "Command from a display or other external device (i.e. remote switch) to the land leveling system controller instructing the controller to set the reference elvation based on data received from the corresponding land leveling sensor.
00 = Do not Set ...";
CM_ SG_ 2364542462 SdshftDsrdBldeOffsetOperatorCtrl "This parameter indicates the side-shift blade control mode operator control state the user has set for the land leveling system.  When an implement moves in a side-shift direction, it moves from side to side, usually along its longitudinal axis.
 ...";
CM_ SG_ 2364542462 SdshiftBladeCtrlModeOperatorCtrl "This parameter indicates the side-shift offset operator control state the user has set for the land leveling system. When an implement moves in a side-shift direction, it moves from side to side, usually along its longitudinal axis. The desired ...";
CM_ SG_ 2364542462 RghtDsredBladeOffsetOperatorCtrl "This parameter indicates the right blade offset operator control state the user has set for the land leveling system.  The right desired blade offset value is the offset measured from a given reference point to the bottom right edge of the blade ...";
CM_ SG_ 2364542462 LftDsiredBladeOffsetOperatorCtrl "This parameter indicates the left blade offset operator control state the user has set for the land leveling system.  The left desired blade offset value is the offset measured from a given reference point to the bottom left edge of the blade. This ...";
CM_ SG_ 2364542462 RightBladeCtrlModeOperatorCtrl "This parameter indicates the right blade control mode operator control state the user has set for the land leveling system.  The operator control value directly relates to the current operator control state correlating to the left edge of the blade ...";
CM_ SG_ 2364542462 LeftBladeCtrlModeOperatorCtrl "This parameter indicates the left blade control mode operator control state the user has set for the land leveling system.  The operator control value directly relates to the current operator control state correlating to the left edge of the blade ...";
CM_ SG_ 2364542462 BladeAutoModeCmd "Allows other controllers to command to the primary control system what they think is the appropriate auto control mode to be engaged in, based on the information they have available to them.  When in automatic mode, the blade automatically adjusts ...";
CM_ SG_ 2364542462 DesiredGradeOffsetSwitch "Indicates the grade offset switch state the user has set for the land leveling system.  The desired grade offset value is the vertical offset measured from a given elevation reference point to the bottom edge of the blade.  This parameter is ...";
CM_ SG_ 2364542462 BladeCtrlModeSwitch "Indicates the blade control mode switch state the user has set for the land leveling system.  The switch value directly correlates to the current switch state, regardless of the switch being used.  This parameter is intended for use in systems using ...";
CM_ BO_ 2365486078 "Laser Receiver Mast Position";
CM_ SG_ 2365486078 MastPos "Used to monitor the position of the sensor attached to the land leveling mast.";
CM_ BO_ 2633937918 "Fuel Information 1 (Liquid)";
CM_ SG_ 2633937918 FlexibleFuelPercentage "Measured signal that indicates the percentage of alcohol in the fuel currently being used.  0% means no alcohol in fuel, 100% means alcohol as fuel and nothing else.
EXAMPLE: If a Bi-fuel vehicle has less than 10% ethanol in the gasoline/petrol, ...";
CM_ SG_ 2633937918 TripAverageFuelRate "Average fuel rate, equal to trip fuel divided by trip time while the engine speed is above zero, since the last trip reset.  This includes idle, engine PTO governor (both moving and non-moving) and drive operation but excludes ignition-on time while ...";
CM_ SG_ 2633937918 TotalEngPTOGovernorFuelUsed "Total fuel used while the PTO or remote PTO governors are in the hold state and engine speed is above zero, over the life of the engine.

NOTE뾗his parameter is intended for liquid fueled engines.  See SPN 1030 for alternate resolution.";
CM_ BO_ 2566845182 "Fuel Economy (Liquid)";
CM_ SG_ 2566845182 EngThrottleValve2Pos "The sensed position feedback of the valve, coming from a second electrical actuator for a second throttle plate, used to regulate the supply of a fluid, usually air or fuel//air mixture.  0% represents no supply and 100% is full supply. SPN 51 is ...";
CM_ SG_ 2566845182 EngThrottleValve1Pos "The position of the valve used to regulate the supply of a fluid, usually air or fuel/air mixture, to an engine.  0% represents no supply and 100% is full supply.";
CM_ SG_ 2566845182 EngAverageFuelEconomy "Average of instantaneous fuel economy for that segment of vehicle operation of interest.";
CM_ SG_ 2566845182 EngInstantaneousFuelEconomy "Current fuel economy at current vehicle velocity.

0xFB00 = Infinite (for example, during engine motoring)";
CM_ SG_ 2566845182 EngFuelRate "Amount of fuel consumed by engine per unit of time.

NOTE - See SPN 1600 for alternate resolution.";
CM_ BO_ 2566842878 "Fuel Consumption (Liquid) 1
Engine fuel consumption accumulators.  See PGN 64777 for alternate resolution.";
CM_ SG_ 2566842878 EngTotalFuelUsed "Accumulated amount of fuel used during vehicle operation.  See SPN 5054 for alternate resolution.";
CM_ SG_ 2566842878 EngTripFuel "Fuel consumed during all or part of a journey.  See SPN 5053 for alternate resolution.";
CM_ BO_ 2633883646 "Front Wheel Drive Status
Front wheel drive ECU information";
CM_ SG_ 2633883646 FrontWheelDriveActuatorStatus "Feedback on the front wheel drive actuator.

00 Front Wheel Drive Actuator not engaged
01 Front Wheel Drive Actuator engaged
10 Error
11 Not Available";
CM_ BO_ 2633880062 "FMS-standard Interface Identity/Capabilities
Information which specifies the capabilities of the Fleet Management System (FMS) - standard interface device. This PGN typically is sourced from the network interconnect FMS - standard interface device.";
CM_ SG_ 2633880062 FMSstandardSWversionSupported "Information that identifies which issue level of the FMS-standard document the software included in the FMS gateway supports. Four bytes, representing xx.yy type revision level identification.
Information to be ASCII equivalent of the numeric ...";
CM_ SG_ 2633880062 FMSstandardRequestsSupported "Status signal which indicates if the FMS Vehicle Interface (FMS Gateway) will respond to requests from the FMS device for the PGNs listed in the FMS Interface Specification.
This mode is to support FMS  gateway devices that only operate in a ...";
CM_ SG_ 2633880062 FMSstandardDiagnosticsSupported "Status signal which indicates if the FMS Vehicle Interface (FMS Gateway) supports the handling of diagnostic messages from the vehicle network onto the FMS network.
The FMS gateway does NOT support the re-broadcast of diagnostics messages present ...";
CM_ BO_ 2566806526 "Forward Lane Image 2";
CM_ SG_ 2566806526 ImagerStatus "Indicates the status of the Forward Looking Imager.
0000b -  Imager fully operational
0001b -  Imager warming up / initializing
0010b -  Imager partially blocked / partially blind
0011b -  Imager fully blocked / fully blind
0100b -  Imager ...";
CM_ SG_ 2566806526 DepWarnSysSt "Indicates the status of Lane Departure Warning system.
0000 - System is not ready (initialization not finished)
0001 - System is temporarily not available (not all activation conditions fulfulled)
0010 - System is deactivated by driver
0011 - ...";
CM_ SG_ 2566806526 RightWheelLaneDepDist "The measured distance of departure of the right wheel on the right side of the lane, as measured from the right edge of the right tire to the left edge of the current lane's right marker.
A distance of 0 indicates the right edge of the right tire ...";
CM_ SG_ 2566806526 LeftWheelLaneDepDist "The measured distance of departure of the left wheel on the left side of the lane, as measured from the left edge of the left tire to the right edge of the current lane's left marker.
A distance of 0 indicates the left edge of the left tire is ...";
CM_ SG_ 2566806526 DrverAlertnessWarningSystemState "Indicates the various system state in the driver alertness warning system. This signal can be used independent of the technology and ECU used to estimate the driver alertness condition.
000 = System installed but disabled
001 = Initializing
010 = ...";
CM_ SG_ 2566806526 DriverAlertnessLevel "Indicates the alertness level of the driver measured by the driver alertness warning system. 100 % means driver is fully attentive. This signal can be used independent of the technology and ECU used to estimate the driver alertness condition.";
CM_ SG_ 2566806526 LnDpartureIndicationEnableStatus "Indicates whether lane departure indication is active.

00 Lane Departure indication disabled
01 Lane Departure Indication enabled 
10 Reserved
11 Not Used";
CM_ SG_ 2566806526 LaneTrackingStatusLeftSide "Indicates whether the left side is tracking lane.

00 Not Tracking Left side
01 Tracking Left side
10 Reserved
11 Don't care/Take no action";
CM_ SG_ 2566806526 LaneTrackingStatusRightSide "Indicates whether right side is tracking lane.

00 Not Tracking Right side
01 Tracking Right side
10 Reserved
11 Don't Care/take no action";
CM_ BO_ 2431649790 "Forward Lane Image 1";
CM_ SG_ 2431649790 LeftSideLaneDepHapticWarnCmd "Indicates that the forward lane imaging system is commanding an haptic warning for the lane departure on the left side of the vehicle.
Used for driving haptic alert devices with minimal internal logic (ie. Those that do not support SPNs 1700 and ...";
CM_ SG_ 2431649790 RightSideLaneDepHapticWarnCmd "Indicates that the forward lane imaging system is commanding an haptic warning for the lane departure on the right side of the vehicle.
Used for driving haptic alert devices with minimal internal logic (ie. Those that do not support SPNs 1700 and ...";
CM_ SG_ 2431649790 LeftSideLaneDepAcstWarnCmd "Indicates that the forward lane imaging system is commanding an acoustical warning for the lane departure on the left side of the vehicle.
Used for driving acoustical alert devices with minimal internal logic (ie. Those that do not support SPNs ...";
CM_ SG_ 2431649790 RightSideLaneDepAcstWarnCmd "Indicates that the forward lane imaging system is commanding an acoustical warning for the lane departure on the right side of the vehicle.
Used for driving acoustical alert devices with minimal internal logic (ie. Those that do not support SPNs ...";
CM_ SG_ 2431649790 LeftSideLaneDepOpticalWarnCmd "Indicates that the forward lane imaging system is commanding an optical warning for the lane departure on the left side of the vehicle.
Used for driving optical alert devices with minimal internal logic (ie. Those that do not support SPNs 1700 and ...";
CM_ SG_ 2431649790 RightSideLaneDepOpticalWarnCmd "Indicates that the forward lane imaging system is commanding an optical warning for the lane departure on the right side of the vehicle.
Used for driving optical alert devices with minimal internal logic (ie. Those that do not support SPNs 1700 and ...";
CM_ SG_ 2431649790 LaneDepartureImminentLeftSide "Indicates departure imminent on left side of lane.

00 Not imminent
01 Imminent
10 Reserved
11 Not used";
CM_ SG_ 2431649790 LaneDepartureImminentRightSide "Indicates departure imminent on right side of lane.

00 Not imminent
01 Imminent
10 Reserved
11 Not Used";
CM_ SG_ 2431649790 LaneDepartureRight "Indicates that the middle of vehicle departs the lane on the right side. The parameter indicates that the vehicle is changing the lane to the right.
00   Middle of the vehicle does not depart the lane to the right side
01   Middle of the vehicle ...";
CM_ SG_ 2431649790 LaneDepartureLeft "Indicates that the middle of vehicle departs the lane on the left side. The parameter indicates that the vehicle is changing the lane to the left.
00   Middle of the vehicle does not depart the lane to the left side
01   Middle of the vehicle ...";
CM_ SG_ 2431649790 DriverAlertnessWarning "Indicates when a distracted driving condition is detected. This signal can be used independent of the technology and ECU used to estimate the distracted driver condition.
000 = No distracted driving condition detected
001 = Level 1 - Mild ...";
CM_ BO_ 2633929214 "Fuel Leakage";
CM_ SG_ 2633929214 EngFluidBundLvl "Ratio of the volume of engine fluid within the bund containment frame to the maximum capacity of the bund containment frame. The bund containment frame is used to contain engine fluid leaks including, but not limited to, engine fuel tank leaks.";
CM_ SG_ 2633929214 EngFuelLeakage2 "Status signal which indicates fuel leakage in the fuel rail of the engine. Location can be either before or after the fuel pump.  

00 - no leakage detected
01 - leakage detected
10 - Error
11 - Not available";
CM_ SG_ 2633929214 EngFuelLeakage1 "Status signal which indicates fuel leakage in the fuel rail of the engine. Location can be either before or after the fuel pump.  

00 - no leakage detected
01 - leakage detected
10 - Error
11 - Not available";
CM_ BO_ 2566831614 "Fan Drive #1
This parameter group transfers status and measured information for an engine coolant fan.  This PGN is used for the primary fan if there are more than one fan in the syste.  PGN 64817 may be used for a second fan.";
CM_ SG_ 2566831614 FanDriveBypassCmdStatus "Status of the Fan Drive Bypass Command as being commanded by the ECU.  The fan drive bypass diverts pump pressure away from the hydraulic motor to maintain the fan drive pressure.  0% is defined as no bypass (i.e. diverting no fan drive pressure) ...";
CM_ SG_ 2566831614 HydFanMotorPress "The hydraulic pressure used to drive the fan system, sensed before the hydraulic fan motor.";
CM_ SG_ 2566831614 FanSpeed "The speed of the fan associated with engine coolant system.";
CM_ SG_ 2566831614 FanDriveState "This parameter is used to indicate the current state or mode of operation by the fan drive.
0000 Fan off
0001 Engine system-General
0010 Excessive engine air temperature
0011 Excessive engine oil temperature
0100 Excessive engine coolant ...";
CM_ SG_ 2566831614 EstPercentFanSpeed "Estimated fan speed as a ratio of the fan drive (current speed) to the fully engaged fan drive (maximum fan speed).  A two state fan (off/on) will use 0% and 100% respectively.  A three state fan (off/intermediate/on) will use 0%, 50% and 100% ...";
CM_ BO_ 2566820094 "Engine Torque History
NOTE - The torque history PGN is variable in length and may contain up to 125 torque history records.  Each torque history record MUST BE 38 bytes in length.  Any unused bytes must be 0xFF.
The last six bytes of each record ...";
CM_ SG_ 2566820094 EngTorqueLimit6AxleInput "Limit applied to the engine output torque based on the maximum allowable axle input torque.  Axle input torque is calculated as the current engine torque output multiplied by the transmission gear ratio.";
CM_ SG_ 2566820094 EngTorqueLimit5Switch "Limit applied to the engine output torque based on activation of an ECU switch input.";
CM_ SG_ 2566820094 EngTorqueLimit4Trans "Limit applied to the engine output torque during vehicle operation in transmission gear ratios numerically less than or equal to transmission gear ratio 3 (see SPN 1259).";
CM_ SG_ 2566820094 EngTorqueLimit3Trans "Limit applied to the engine output torque during vehicle operation in transmission gear ratios numerically less than or equal to transmission gear ratio 2 (see SPN 1257) and numerically greater than transmission gear ratio 3 (see.SPN 1259).  For ...";
CM_ SG_ 2566820094 TransGearRatio3 "Gear ratio value stored in the ECU that is used to define a range of transmission gears for which a limit is applied to the engine output torque.  Transmission gear ratio 3 should be the numerically highest transmission gear ratio breakpoint less ...";
CM_ SG_ 2566820094 EngTorqueLimit2Trans "Limit applied to the engine output torque during vehicle operation in transmission gear ratios numerically less than or equal to transmission gear ratio 1 (see SPN 1255) and numerically greater than transmission gear ratio 2 (see.SPN 1257).  For ...";
CM_ SG_ 2566820094 TransGearRatio2 "Gear ratio value stored in the ECU that is used to define a range of transmission gears for which a limit is applied to the engine output torque.  Transmission gear ratio 2 should be the numerically highest transmission gear ratio breakpoint less ...";
CM_ SG_ 2566820094 EngTorqueLimit1Trans "Limit applied to the engine output torque during vehicle operation in transmission gear ratios numerically greater than transmission gear ratio 1 (see SPN 1255).";
CM_ SG_ 2566820094 TransGearRatio1 "Gear ratio value stored in the ECU that is used to define a range of transmission gears for which a limit is applied to the engine output torque.  Transmission gear ratio 1 should be the numerically highest transmission gear ratio breakpoint that ...";
CM_ SG_ 2566820094 EngTorqueLimitFeature "Torque limit rating described in the current record.
000 Reserved
001 Highest torque rating
010 First torque rating
011 Previous torque rating (rating prior to the current rating)
100 Current torque rating
101-110 Reserved
111 Not available
 ...";
CM_ SG_ 2566820094 TorqueLimitingFeatureStatus "Status of an ECU feature which limits the torque output of the engine. 

00 - Disabled
01 - Enabled
10 - Error
11 - Not available";
CM_ SG_ 2566820094 CalibRecordDurationTime "Duration in hours for which the engine operated in the conditions captured in the current record.";
CM_ SG_ 2566820094 CalibRecordStartYear "Calendar year timestamp when an ECU record was established.

NOTE - A value of 0 for the year identifies the year 1985; a value of 1 identifies 1986; etc.";
CM_ SG_ 2566820094 CalibRecordStartDay "Calendar day timestamp when an ECU record was established.

NOTE - A value of 0 for the date is null.  The values 1, 2, 3, and 4 are used to identify the first day of the month; 5, 6, 7, and 8 identify the second day of the month; etc.";
CM_ SG_ 2566820094 CalibRecordStartMonth "Calendar month timestamp when an ECU record was established.

NOTE - A value of 0 for the month is null.  The value 1 identifies January; 2 identifies February; etc.";
CM_ SG_ 2566820094 EngPeakTorque2 "Maximum torque output of the current ECU calibration when the engine operates on torque curve 2.  For calibrations that support two torque curves, this parameter shall be assigned the value of the higher curve.  For calibrations that support only ...";
CM_ SG_ 2566820094 EngPeakTorque1 "Maximum torque output of the current ECU calibration when the engine operates on torque curve 1.  For calibrations that support two torque curves, this parameter shall be assigned the value of the lower curve.  For calibrations that support only one ...";
CM_ SG_ 2566820094 EngPower "Advertised engine power capability.  Advertised power is what a customer will find on a sales sheet for an engine with a certain calibration.";
CM_ SG_ 2566820094 NumberOfEngTorqueHistoryRecords "Number of torque history records contained in the engine torque history PGN.  A value of 0 is broadcast if no torque history records are stored in the ECU.";
CM_ BO_ 2364542206 "Electronic Transmission Controller #8
Electronic Transmission Controller #8";
CM_ SG_ 2364542206 TransClutch_ConverterInputSpeed "Rotational velocity of the input to a transmission's master clutch or torque converter. In most cases the rotational velocity will be the same as engine flywheel speed unless there is an intermediate device, such as a power divider, between the ...";
CM_ SG_ 2364542206 TransTorqueConverterRatio "Ratio of the transmissions torque converter output torque to torque converter input torque at current speed.
The ratio of 1.000 ( 03 E8 hex ) indicates torque converter lockup.
If the ratio is less than 1 and the ratio can not be properly ...";
CM_ BO_ 2566802174 "Electronic Transmission Controller 7
Transmission status information from the transmission controller to network.";
CM_ SG_ 2566802174 ManualModeInd "This parameter indicates if the operator has selected a Manual Mode of the transmission. When a Manual Mode is active, the operator has directly and intentionally restricted the available transmission ranges for the given vehicle direction. A Manual ...";
CM_ SG_ 2566802174 TransAutoNeutralSt "Indicates the transmission response to a Neutral request from SPN 7695 [Transmission Auto-Neutral (Manual Return) Request] or other vehicle input configured for Auto-Neutral (Manual Return) functionality. The applicability of the states and state ...";
CM_ SG_ 2566802174 TransWarningIndicator "Signal from transmission indicating that some aspect of its operation is not functioning correctly, and as a result, transmission operation may be altered or restricted.  The indicator is typically a lamp.  Distinctions in meaning between the ...";
CM_ SG_ 2566802174 TrnsRverseGearShiftInhibitStatus "Reflects the status of transmission reverse inhibit activity in response to requests via SPN 4242 - Transmission Reverse Gear Shift Inhibit Request.  Typically broadcast by the transmission controller.
00 = Reverse gear shifts are currently allowed
 ...";
CM_ SG_ 2566802174 TransMode8Indicator "This state signal is the transmission뭩 indication that it is operating under transmission mode 8 (SPN 4249) as commanded via the TC1 message (PGN 256).  The definition of the transmission mode is left to the discretion of the transmission ...";
CM_ SG_ 2566802174 TransMode7Indicator "This state signal is the transmission뭩 indication that it is operating under transmission mode 7 (SPN 4248) as commanded via the TC1 message (PGN 256).  The definition of the transmission mode is left to the discretion of the transmission ...";
CM_ SG_ 2566802174 TransMode6Indicator "This state signal is the transmission뭩 indication that it is operating under transmission mode 6 (SPN 4247) as commanded via the TC1 message (PGN 256).  The definition of the transmission mode is left to the discretion of the transmission ...";
CM_ SG_ 2566802174 TransMode5Indicator "This state signal is the transmission뭩 indication that it is operating under transmission mode 5 (SPN 4246) as commanded via the TC1 message (PGN 256).  The definition of the transmission mode is left to the discretion of the transmission ...";
CM_ SG_ 2566802174 TransRequestedGearFeedback "Feedback of the SPN 525 Transmission Requested Gear input as received from the shift selector, ABS or engine via PGN 256, Transmission Control 1 (TC1) or other transmission selector input.  Scaling, values and parameter specific indicators are ...";
CM_ SG_ 2566802174 TransMode1Indicator "This state signal is the transmission뭩 indication that it is operating under transmission mode 1 (SPN 1852) as commanded via the TC1 message (PGN 256).  The definition of the transmission mode is left to the discretion of the transmission ...";
CM_ SG_ 2566802174 TransMode2Indicator "This state signal is the transmission뭩 indication that it is operating under transmission mode 2 (SPN 1853) as commanded via the TC1 message (PGN 256).  The definition of the transmission mode is left to the discretion of the transmission ...";
CM_ SG_ 2566802174 TransMode3Indicator "This state signal is the transmission뭩 indication that it is operating under transmission mode 3 (SPN 1854) as commanded via the TC1 message (PGN 256).  The definition of the transmission mode is left to the discretion of the transmission ...";
CM_ SG_ 2566802174 TransMode4Indicator "This state signal is the transmission뭩 indication that it is operating under transmission mode 4 (SPN 1855) as commanded via the TC1 message (PGN 256).  The definition of the transmission mode is left to the discretion of the transmission ...";
CM_ SG_ 2566802174 TransShiftInhibitIndicator "State signal indicating a transmission request for the Shift Inhibit Indicator to be active or inactive. The shift inhibit indicator can be of lamp or text form, located on (but not limited to) the shift console, instrument cluster, or cab display ...";
CM_ SG_ 2566802174 TransEngCrankEnable "State signal from the transmission indicating if the transmission뭩 status is such that engine cranking is allowed (i.e.  at a minimum, transmission is in neutral and the driveline is disengaged).  As sender of this information, the transmission is ...";
CM_ SG_ 2566802174 ActiveShiftConsoleIndicator "Signal from transmission control unit indicating which shift console (primary or secondary) it currently considers as the active shift selector input.
00        Primary shift console is active
01        Secondary shift console is active
10 ...";
CM_ SG_ 2566802174 TransReadyForBrakeRelease "This parameter indicates that enough torque / motive force is available at the transmission output shaft to release all the brakes without a risk of unintentional movement in the opposite direction.
00 - Transmission Not Ready for Brake Release
01 ...";
CM_ SG_ 2566802174 TrnsRqstedRangeDisplayFlashState "State signal indicating a transmission request for the display of the Transmission Requested Range parameter (SPN 162) to flash or not to flash. The 멦ransmission Requested Range Display Flash State� indicator can be utilized by (but not limited to) ...";
CM_ SG_ 2566802174 TrnsRqstedRangeDisplayBlankState "State signal indicating a transmission request for the display of the Transmission Requested Range parameter (SPN162) to be blanked or not blanked.  The 멦ransmission Requested Range Display Blank State� indicator can be utilized by (but not limited ...";
CM_ SG_ 2566802174 TransServiceIndicator "Signal from transmission indicating that some aspect of the gearbox requires servicing, such as the oil, filter, clutch(es) or other component.
00  Transmission Service Indicator is off
01  Transmission Service Indicator is on continuously
10 ...";
CM_ SG_ 2566802174 TransAirSupplyPressIndicator "Indicates whether transmission air supply is sufficient
000   Normal Pressure Range - The transmission supply air pressure is within the normal operational range.
001   Low pressure - The transmission supply air pressure is within a range that may ...";
CM_ SG_ 2566802174 TransMode10Indicator "Indicates that the transmission is operating under transmission mode 10 (SPN 6570) as commanded via the TC2 message (PGN 3328). The definition of the transmission mode is left to the discretion of the transmission manufacturer.
00 Transmission Mode ...";
CM_ SG_ 2566802174 TransMode9Indicator "Indicates that the transmission is operating under transmission mode 9 (SPN 6569) as commanded via the TC2 message (PGN 3328). The definition of the transmission mode is left to the discretion of the transmission manufacturer.
00 Transmission Mode ...";
CM_ SG_ 2566802174 TrnsCrrentRangeDisplayBlankState "State signal indicating a transmission request for the display of the Transmission Current Range parameter (SPN 163) to be blanked or not blanked.  The 'Transmission Current Range Display Blank State' indicator can be utilized by (but not limited ...";
CM_ BO_ 2633935870 "Electronic Transmission Controller 6";
CM_ SG_ 2633935870 ClutchLifeRemaining "Signal which indicates the actual clutch life remaining in percent. One hundred percent means the clutch is brand new and zero percent means the clutch is at the end of its life.";
CM_ SG_ 2633935870 LowestPossibleGear "The transmission calculates this gear continuously.  Together with the highest possible gear (see SPN 1115), it enables a management computer to know the exact range of available gears.";
CM_ SG_ 2633935870 HighestPossibleGear "The transmission calculates this gear continuously.  Together with the lowest possible gear (see  SPN 1114), it enables a management computer to know the exact range of available gears.";
CM_ SG_ 2633935870 RecommendedGear "The transmission calculates this gear continuously.  In dangerous situations this gear may be selected to gain back vehicle control.";
CM_ BO_ 2633942014 "Electronic Transmission Controller 5";
CM_ SG_ 2633942014 TransForwardDirectionSwitch "Identifies the status of the switch that indicates forward direction.

00 - Off
01 - On
10 - Error
11 - Not available";
CM_ SG_ 2633942014 TransNeutralSwitch "Identifies the status of the switch that indicates neutral.

00 - Off
01 - On
10 - Error
11 - Not available";
CM_ SG_ 2633942014 TransReverseDirectionSwitch "Identifies the status of the switch that indicates reverse direction.

00 - Off
01 - On
10 - Error
11 - Not available";
CM_ SG_ 2633942014 TransLowRangeSenseSwitch "Identifies the status of the switch that represents low range.

00 - Off
01 - On
10 - Error
11 - Not available";
CM_ SG_ 2633942014 TransHighRangeSenseSwitch "Identifies the status of the switch that represents high range.

00 - Off
01 - On
10 - Error
11 - Not available";
CM_ BO_ 2633942526 "Electronic Transmission Controller 4";
CM_ SG_ 2633942526 TransSynchronizerBrakeValue "The current modulated value for the air supply to the synchronizer brake.";
CM_ SG_ 2633942526 TransSynchronizerClutchValue "The current modulated value for the air supply to the synchronizer clutch.";
CM_ BO_ 2633943038 "Electronic Transmission Controller 3";
CM_ SG_ 2633943038 TransInertiaBrakeActuator "Identifies the status of the actuator that controls the inertia brake.

00 - Off
01 - On
10 - Error
11 - Not available";
CM_ SG_ 2633943038 TransDefuelActuator "Identifies the status of the actuator that controls the engine defuel mechanism.

00 - Off
01 - On
10 - Error
11 - Not available";
CM_ SG_ 2633943038 TransLockupClutchActuator "Identifies the status of the actuator that controls the torque converter lockup clutch.

00 - Off
01 - On
10 - Error
11 - Not available";
CM_ SG_ 2633943038 TransClutchActuator "Identifies the status of the actuator that controls the clutch.

00 - Off
01 - On
10 - Error
11 - Not available";
CM_ SG_ 2633943038 TransSplitterIndirectActuator "Identifies the status of the splitter indirect actuator in the auxiliary unit.

00 - Off
01 - On
10 - Error
11 - Not available";
CM_ SG_ 2633943038 TransSplitterDirectActuator "Identifies the status of the splitter direct actuator in the auxiliary unit.

00 - Off
01 - On
10 - Error
11 - Not available";
CM_ SG_ 2633943038 TransRangeLowActuator "Identifies the status of the range low actuator in the auxiliary unit.

00 - Off
01 - On
10 - Error
11 - Not available";
CM_ SG_ 2633943038 TransRangeHighActuator "Identifies the status of the range high actuator in the auxiliary unit.

00 -Off
01 -On
10 - Error
11 - Not available";
CM_ SG_ 2633943038 TransShiftFingerGearActuator2 "Identifies the status of the actuator that moves the shift finger identified as gear actuator #2.

00 - Off
01 - On
10 - Error
11 - Not available";
CM_ SG_ 2633943038 TransShiftFingerRailActuator2 "Identifies the status of the actuator that moves the shift finger identified as rail actuator #2.

00 - Off
01 - On
10 - Error
11 - Not available";
CM_ SG_ 2633943038 TransShiftFingerGearActuator1 "Identifies the status of the actuator that moves the shift finger identified as gear actuator #1.

00 - Off
01 - On
10 - Error
11 - Not available";
CM_ SG_ 2633943038 TransShiftFingerRailActuator1 "Identifies the status of the actuator that moves the shift finger identified as rail actuator #1.

00 - Off
01 - On
10 - Error
11 - Not available";
CM_ SG_ 2633943038 TrnsShftFngerCenterRailIndicator "Identifies the status of the shift finger in the center rail position.

00 - Off
01 - On
10 - Error
11 - Not available";
CM_ SG_ 2633943038 TrnsShftFngerEngagementIndicator "Identifies the status of the shift finger in the engagement position.

00 - Off
01 - On
10 - Error
11 - Not available";
CM_ SG_ 2633943038 TransShiftFingerNeutralIndicator "Indicates the status of the shift finger in the neutral position.

00 - Off
01 - On
10 - Error
11 - Not available";
CM_ SG_ 2633943038 TransShiftFingerRailPos "The current position of the shift finger in the rail direction.";
CM_ SG_ 2633943038 TransShiftFingerGearPos "The current position of the shift finger in the gear direction.";
CM_ BO_ 2565867006 "Electronic Transmission Controller 2";
CM_ SG_ 2565867006 TransCurrentRange "Range currently being commanded by the transmission control system. Characters may include P, Rx, Rx-1...R2, R1, R, Nx, Nx-1...N2, N1, N, D, D1, D2..., Dx, L, L1, L2..., Lx-1, 1, 2, 3,... If only one displayed character is required, the second ...";
CM_ SG_ 2565867006 TransRequestedRange "Range selected by the operator.  Characters may include P, Rx, Rx-1...R2, R1, R, Nx, Nx-1...N2, N1, N, D, D1, D2..., Dx, L, L1, L2..., Lx-1, 1, 2, 3,...  If only one displayed character is required, the second character shall be used and the first ...";
CM_ SG_ 2565867006 TransCurrentGear "The gear currently engaged in the transmission or the last gear engaged while the transmission is in the process of shifting to the new or selected gear.  Transitions toward a destination gear will not be indicated.  Once the selected gear has been ...";
CM_ SG_ 2565867006 TransActualGearRatio "Actual ratio of input shaft speed to output shaft speed.";
CM_ SG_ 2565867006 TransSelectedGear "The gear that the transmission will attempt to achieve during the current shift if a shift is in progress, or the next shift if one is pending (i.e., waiting for torque reduction to initiate the shift).";
CM_ BO_ 2364539646 "Electronic Transmission Controller 1
Electronic Transmission Controller #1
Note:
Single input shaft transmissions should use SPN 161 (Transmission Input Shaft Speed).
Multiple input shaft transmissions should use SPN 5960 and 5961 (DCT Input ...";
CM_ SG_ 2364539646 SrcAddrssOfCntrllngDvcFrTrnsCtrl "The source address of the SAE J1939 device currently controlling the transmission. Its value may be the source address of the ECU transmitting the message (which means that no external SAE J1939 message is providing the active command) or the source ...";
CM_ SG_ 2364539646 TransInputShaftSpeed "Rotational velocity of the primary shaft transferring power into the first transmission.  When a torque converter is present, it is the output of the torque converter.
Note:
Single input shaft transmissions should use SPN 161 (Transmission Input ...";
CM_ SG_ 2364539646 MomentaryEngMaxPowerEnable "Momentarily Requesting highest torque map from the engine control

00 not requesting maximum power available
01 momentarily requesting maximum power available
10 fault
11 not available";
CM_ SG_ 2364539646 ProgressiveShiftDisable "Command signal used to indicate that progressive shifting by the engine should be disallowed.

00 Progressive shift is not disabled
01 Progressive shift is disabled
10 Reserved
11 Take no action";
CM_ SG_ 2364539646 EngMomentaryOverspeedEnable "Command signal used to indicate that the engine speed may be boosted up to the maximum engine overspeed value to accommodate transmission downshifts.  The maximum time for overspeed is limited by the time defined in the engine configuration message ...";
CM_ SG_ 2364539646 PercentClutchSlip "Parameter which represents the ratio of input shaft speed to current engine speed (in percent).

Percent Clutch Slip = ((Engine rpm - Input shaft rpm)/(Engine rpm)) x 100";
CM_ SG_ 2364539646 TransOutputShaftSpeed "Calculated speed of the transmission 1 output shaft.";
CM_ SG_ 2364539646 TrnsTrqCnvrtrLckpTrnstnInProcess "State signal indicating whether or not the transmission torque converter lock up clutch is transitioning between being applied and being released.  The broadcast value should be set to 01 as soon as an apply or release of the lockup clutch is ...";
CM_ SG_ 2364539646 TransShiftInProcess "Indicates that the transmission is in process of shifting from the current gear to the selected gear. This state is generally ACTIVE during the entire time that the transmission controls the vehicle during a shift. This includes any transmission ...";
CM_ SG_ 2364539646 TrnsTorqueConverterLockupEngaged "State signal which indicates whether the torque converter lockup is engaged.

00 Torque converter lockup disengaged
01 Torque converter lockup engaged
10 Error
11 Not available";
CM_ SG_ 2364539646 TransDrivelineEngaged "Driveline engaged indicates the transmission controlled portion of the driveline is engaged sufficiently to allow a transfer of torque through the transmission.  Driveline engaged is ACTIVE whenever the transmission is in gear and the clutch (if ...";
CM_ BO_ 2566810110 "Engine Temperature 3
This parameter group is used to transmit high resolution engine temperatures for control purposes.";
CM_ SG_ 2566810110 EngChargeAirCooler1OutletTemp "Temperature of combustion air after it exits from the Charge Air Cooler 1 but before any mixing of recirculated exhaust gas.";
CM_ SG_ 2566810110 EngIntkVlvActuationSystemOilTemp "The temperature of the oil in the hydraulic system that powers the intake valve actuation system.";
CM_ SG_ 2566810110 EngCoolantTemp "Temperature of liquid found in engine cooling system. The higher resolution is required for control purposes.";
CM_ SG_ 2566810110 EngIntakeManifold1AirTemp "Temperature of pre-combustion air found in intake manifold of engine air supply system. The higher resolution is required for control purposes.";
CM_ BO_ 2566825214 "Engine Temperature 2";
CM_ SG_ 2566825214 EngExhaustGasRecirculation1Temp "Temperature of Recirculated Exhaust Gas.  This should not be used for Exhaust Gas Recirculation Mixer Intake Temperature.  See SPN 5020.";
CM_ SG_ 2566825214 EngExhstGsRcirculation1DiffPress "Differential pressure across the Exhaust Gas Recirculation (EGR) system";
CM_ SG_ 2566825214 EngECUTemp "Temperature of the engine electronic control unit.";
CM_ SG_ 2566825214 EngOilTemp2 "Temperature of the engine lubricant.

Note:  If there is only one engine oil temperature measurement, SPN 175 should be used. 

See also SPNs 175 and 5925 for additional engine oil temperature measurements.";
CM_ BO_ 2566844158 "Engine Temperature 1";
CM_ SG_ 2566844158 EngIntercoolerThermostatOpening "The current position of the thermostat used to regulate the temperature of the engine charge air cooler.  A value of 0% represents the thermostat being completely closed and 100% represents the thermostat being completely open.";
CM_ SG_ 2566844158 EngIntercoolerTemp "Temperature of liquid found in the intercooler located after the turbocharger.";
CM_ SG_ 2566844158 EngTurboOilTemp "Temperature of the turbocharger lubricant.";
CM_ SG_ 2566844158 EngOilTemp1 "Temperature of the engine lubricant.
Note:  If there is only one engine oil temperature measurement, this SPN should be used.  This is the SPN that is typically displayed on an on-highway truck instrument cluster.
See also SPNs 1135 and 5925 for ...";
CM_ SG_ 2566844158 EngFuelTemp1 "Temperature of fuel (or gas) of the first fuel type. See SPN 3468 for a second temperature measurement of the first fuel type.";
CM_ SG_ 2566844158 EngCoolantTemp "Temperature of liquid found in engine cooling system.";
CM_ BO_ 2566785022 "Exhaust Temperature";
CM_ SG_ 2566785022 EngExhaustManifoldBank1Temp2 "Temperature of combustion byproducts measured by a second sensor in engine bank 1 (left bank) exhaust manifold. This should be used for the sensor toward the rear of the engine on the bank 1 manifold.";
CM_ SG_ 2566785022 EngExhaustManifoldBank2Temp2 "Temperature of combustion byproducts measured by a second sensor in engine bank 2 (right bank) exhaust manifold. This should be used for the sensor toward the rear of the engine on the bank 2 manifold.";
CM_ SG_ 2566785022 EngExhaustGasTempLeftManifold "Temperature of combustion byproducts measured in engine bank 1 (left bank) exhaust manifold.  Single manifold engines should use exhaust temperature (SPN 173).";
CM_ SG_ 2566785022 EngExhaustGasTempRightManifold "Temperature of combustion byproducts measured in engine bank 2 (right bank) exhaust manifold.  Single manifold engines should use exhaust temperature (SPN 173).";
BA_DEF_ SG_  "SigType" ENUM  "Default","Range","RangeSigned","ASCII","Discrete","Control","ReferencePGN","DTC","StringDelimiter","StringLength","StringLengthControl","MessageCounter","MessageChecksum";
BA_DEF_ SG_  "GenSigStartValue" INT 0 2147483647;
BA_DEF_ SG_  "GenSigSendType" ENUM  "Cyclic","OnWrite","OnWriteWithRepetition","OnChange","OnChangeWithRepetition","IfActive","IfActiveWithRepetition","NoSigSendType";
BA_DEF_ SG_  "GenSigILSupport" ENUM  "No","Yes";
BA_DEF_ SG_  "GenSigEVName" STRING ;
BA_DEF_ SG_  "SPN" INT 0 524287;
BA_DEF_ BO_  "TpJ1939VarDlc" ENUM  "No","Yes";
BA_DEF_ BO_  "GenMsgStartDelayTime" INT 0 100000;
BA_DEF_ BO_  "GenMsgILSupport" ENUM  "No","Yes";
BA_DEF_ BO_  "GenMsgDelayTime" INT 0 1000;
BA_DEF_ BO_  "GenMsgRequestable" INT 0 1;
BA_DEF_ BO_  "GenMsgSendType" ENUM  "cyclic","NotUsed","NotUsed","NotUsed","NotUsed","NotUsed","NotUsed","IfActive","noMsgSendType";
BA_DEF_ BO_  "VFrameFormat" ENUM  "StandardCAN","ExtendedCAN","reserved","J1939PG";
BA_DEF_ BO_  "GenMsgCycleTime" INT 0 3600000;
BA_DEF_ SG_  "SystemSignalLongSymbol" STRING ;
BA_DEF_DEF_  "SigType" "Default";
BA_DEF_DEF_  "GenSigStartValue" 0;
BA_DEF_DEF_  "GenSigSendType" "NoSigSendType";
BA_DEF_DEF_  "GenSigILSupport" "Yes";
BA_DEF_DEF_  "GenSigEVName" "Env@Nodename_@Signame";
BA_DEF_DEF_  "SPN" 0;
BA_DEF_DEF_  "TpJ1939VarDlc" "No";
BA_DEF_DEF_  "GenMsgStartDelayTime" 0;
BA_DEF_DEF_  "GenMsgILSupport" "Yes";
BA_DEF_DEF_  "GenMsgDelayTime" 0;
BA_DEF_DEF_  "GenMsgRequestable" 1;
BA_DEF_DEF_  "GenMsgSendType" "noMsgSendType";
BA_DEF_DEF_  "VFrameFormat" "J1939PG";
BA_DEF_DEF_  "GenMsgCycleTime" 0;
BA_DEF_DEF_  "SystemSignalLongSymbol" "";
BA_ "GenMsgCycleTime" BO_ 2566804478 5000;
BA_ "GenMsgSendType" BO_ 2566804478 0;
BA_ "GenMsgCycleTime" BO_ 2566847486 1000;
BA_ "GenMsgSendType" BO_ 2566847486 0;
BA_ "GenMsgCycleTime" BO_ 2566840830 5000;
BA_ "GenMsgSendType" BO_ 2566840830 0;
BA_ "GenMsgDelayTime" BO_ 2566840830 500;
BA_ "GenMsgCycleTime" BO_ 2566844670 100;
BA_ "GenMsgSendType" BO_ 2566844670 0;
BA_ "GenMsgCycleTime" BO_ 2566770174 200;
BA_ "GenMsgSendType" BO_ 2566770174 0;
BA_ "GenMsgCycleTime" BO_ 2566769662 500;
BA_ "GenMsgSendType" BO_ 2566769662 0;
BA_ "GenMsgCycleTime" BO_ 2566768638 5000;
BA_ "GenMsgSendType" BO_ 2566768638 0;
BA_ "GenMsgCycleTime" BO_ 2365443326 1000;
BA_ "GenMsgSendType" BO_ 2365443326 0;
BA_ "GenMsgDelayTime" BO_ 2365443326 100;
BA_ "GenMsgCycleTime" BO_ 2566776318 1000;
BA_ "GenMsgSendType" BO_ 2566776318 0;
BA_ "GenMsgCycleTime" BO_ 2566802686 500;
BA_ "GenMsgSendType" BO_ 2566802686 0;
BA_ "GenMsgDelayTime" BO_ 2566802686 100;
BA_ "GenMsgCycleTime" BO_ 2566774014 1000;
BA_ "GenMsgSendType" BO_ 2566774014 0;
BA_ "GenMsgCycleTime" BO_ 2566823166 1000;
BA_ "GenMsgSendType" BO_ 2566823166 0;
BA_ "GenMsgCycleTime" BO_ 2566823422 1000;
BA_ "GenMsgSendType" BO_ 2566823422 0;
BA_ "GenMsgCycleTime" BO_ 2566823678 1000;
BA_ "GenMsgSendType" BO_ 2566823678 0;
BA_ "GenMsgCycleTime" BO_ 2432595710 100;
BA_ "GenMsgSendType" BO_ 2432595710 0;
BA_ "GenMsgCycleTime" BO_ 2365486590 50;
BA_ "GenMsgSendType" BO_ 2365486590 0;
BA_ "GenMsgCycleTime" BO_ 2365485566 50;
BA_ "GenMsgSendType" BO_ 2365485566 0;
BA_ "GenMsgCycleTime" BO_ 2365486334 50;
BA_ "GenMsgSendType" BO_ 2365486334 0;
BA_ "GenMsgCycleTime" BO_ 2364542462 100;
BA_ "GenMsgSendType" BO_ 2364542462 0;
BA_ "GenMsgCycleTime" BO_ 2365486078 50;
BA_ "GenMsgSendType" BO_ 2365486078 0;
BA_ "GenMsgCycleTime" BO_ 2566845182 100;
BA_ "GenMsgSendType" BO_ 2566845182 0;
BA_ "GenMsgCycleTime" BO_ 2633883646 5000;
BA_ "GenMsgSendType" BO_ 2633883646 0;
BA_ "GenMsgCycleTime" BO_ 2633880062 10000;
BA_ "GenMsgSendType" BO_ 2633880062 0;
BA_ "GenMsgCycleTime" BO_ 2566806526 100;
BA_ "GenMsgSendType" BO_ 2566806526 0;
BA_ "GenMsgCycleTime" BO_ 2431649790 50;
BA_ "GenMsgCycleTime" BO_ 2633929214 1000;
BA_ "GenMsgSendType" BO_ 2633929214 0;
BA_ "GenMsgCycleTime" BO_ 2566831614 1000;
BA_ "GenMsgSendType" BO_ 2566831614 0;
BA_ "GenMsgCycleTime" BO_ 2364542206 20;
BA_ "GenMsgSendType" BO_ 2364542206 0;
BA_ "GenMsgCycleTime" BO_ 2566802174 100;
BA_ "GenMsgSendType" BO_ 2566802174 0;
BA_ "GenMsgCycleTime" BO_ 2565867006 100;
BA_ "GenMsgSendType" BO_ 2565867006 0;
BA_ "GenMsgCycleTime" BO_ 2364539646 10;
BA_ "GenMsgSendType" BO_ 2364539646 0;
BA_ "GenMsgCycleTime" BO_ 2566810110 1000;
BA_ "GenMsgSendType" BO_ 2566810110 0;
BA_ "GenMsgCycleTime" BO_ 2566825214 1000;
BA_ "GenMsgSendType" BO_ 2566825214 0;
BA_ "GenMsgCycleTime" BO_ 2566844158 1000;
BA_ "GenMsgSendType" BO_ 2566844158 0;
BA_ "GenMsgCycleTime" BO_ 2566785022 5000;
BA_ "GenMsgSendType" BO_ 2566785022 0;
BA_ "SPN" SG_ 2566786302 ArbitraryAddressCapable 2844;
BA_ "SPN" SG_ 2566786302 IndustryGroup 2846;
BA_ "SPN" SG_ 2566786302 VehicleSystemInstance 2843;
BA_ "SPN" SG_ 2566786302 ECUInstance 2840;
BA_ "SPN" SG_ 2566786302 FunctionInstance 2839;
BA_ "SPN" SG_ 2566786302 Function 2841;
BA_ "SPN" SG_ 2566786302 ManufacturerCode 2838;
BA_ "SigType" SG_ 2566786302 ManufacturerCode 1;
BA_ "SPN" SG_ 2566786302 IdentityNumber 2837;
BA_ "SPN" SG_ 2566832382 SrviceDelay_OperationalTimeBased 916;
BA_ "SigType" SG_ 2566832382 SrviceDelay_OperationalTimeBased 1;
BA_ "SPN" SG_ 2566832382 ServiceComponentIdentificatio913 913;
BA_ "SigType" SG_ 2566832382 ServiceComponentIdentificatio913 1;
BA_ "SPN" SG_ 2566832382 ServiceDelay_CalendarTimeBased 915;
BA_ "SigType" SG_ 2566832382 ServiceDelay_CalendarTimeBased 1;
BA_ "SPN" SG_ 2566832382 ServiceComponentIdentificatio912 912;
BA_ "SigType" SG_ 2566832382 ServiceComponentIdentificatio912 1;
BA_ "SPN" SG_ 2566832382 ServiceDistance 914;
BA_ "SigType" SG_ 2566832382 ServiceDistance 1;
BA_ "SPN" SG_ 2566832382 ServiceComponentIdentification 911;
BA_ "SigType" SG_ 2566832382 ServiceComponentIdentification 1;
BA_ "SPN" SG_ 2633928446 TimeSinceLastService 1350;
BA_ "SigType" SG_ 2633928446 TimeSinceLastService 1;
BA_ "SPN" SG_ 2633928446 ServiceComponentIdentification 1379;
BA_ "SigType" SG_ 2633928446 ServiceComponentIdentification 1;
BA_ "SPN" SG_ 2566804478 MinContinuousRetarderTorque 1783;
BA_ "SigType" SG_ 2566804478 MinContinuousRetarderTorque 1;
BA_ "SPN" SG_ 2566804478 MaxContinuousRetarderTorque 1782;
BA_ "SigType" SG_ 2566804478 MaxContinuousRetarderTorque 1;
BA_ "SPN" SG_ 2566804478 MinContinuousRetarderSpeed 1781;
BA_ "SigType" SG_ 2566804478 MinContinuousRetarderSpeed 1;
BA_ "SPN" SG_ 2566804478 MaxContinuousRetarderSpeed 1780;
BA_ "SigType" SG_ 2566804478 MaxContinuousRetarderSpeed 1;
BA_ "SPN" SG_ 2566804478 HghLmtThrshldFrMnCntnsTrqFrmRtrd 1779;
BA_ "SigType" SG_ 2566804478 HghLmtThrshldFrMnCntnsTrqFrmRtrd 1;
BA_ "SPN" SG_ 2566804478 LwLmtThrshldFrMxTrqeFromRetarder 1778;
BA_ "SigType" SG_ 2566804478 LwLmtThrshldFrMxTrqeFromRetarder 1;
BA_ "SPN" SG_ 2566804478 HghLmtThrshldFrMnCntnsRPMFrmRtrd 1777;
BA_ "SigType" SG_ 2566804478 HghLmtThrshldFrMnCntnsRPMFrmRtrd 1;
BA_ "SPN" SG_ 2566804478 LwLmtThrshldFrMaxRPMFromRetarder 1776;
BA_ "SigType" SG_ 2566804478 LwLmtThrshldFrMaxRPMFromRetarder 1;
BA_ "SPN" SG_ 2566847486 DrvlineRetarderOverheatIndicator 5346;
BA_ "SigType" SG_ 2566847486 DrvlineRetarderOverheatIndicator 5;
BA_ "SPN" SG_ 2566847486 RetarderCoolantOutletTemp 5656;
BA_ "SigType" SG_ 2566847486 RetarderCoolantOutletTemp 1;
BA_ "SPN" SG_ 2566847486 HydRetarderOilTemp 120;
BA_ "SigType" SG_ 2566847486 HydRetarderOilTemp 1;
BA_ "SPN" SG_ 2566847486 HydRetarderPress 119;
BA_ "SigType" SG_ 2566847486 HydRetarderPress 1;
BA_ "SPN" SG_ 2631859966 SteerStraightAheadPosReset 3600;
BA_ "SigType" SG_ 2631859966 SteerStraightAheadPosReset 5;
BA_ "SPN" SG_ 2631859966 EngBuildHoursReset 1211;
BA_ "SigType" SG_ 2631859966 EngBuildHoursReset 5;
BA_ "SPN" SG_ 2631859966 EngIgntCtrlMaintenanceHoursReset 6219;
BA_ "SigType" SG_ 2631859966 EngIgntCtrlMaintenanceHoursReset 4;
BA_ "SPN" SG_ 2631859966 EngSprkPlgScndVltgeTrackingReset 6218;
BA_ "SigType" SG_ 2631859966 EngSprkPlgScndVltgeTrackingReset 5;
BA_ "SPN" SG_ 2631859966 ServiceComponentIdentification 1584;
BA_ "SigType" SG_ 2631859966 ServiceComponentIdentification 1;
BA_ "SPN" SG_ 2631859966 TripGroup2Proprietary 989;
BA_ "SigType" SG_ 2631859966 TripGroup2Proprietary 5;
BA_ "SPN" SG_ 2631859966 TireSensorInformation 6986;
BA_ "SigType" SG_ 2631859966 TireSensorInformation 4;
BA_ "SPN" SG_ 2631859966 TireConfigInformation 6985;
BA_ "SigType" SG_ 2631859966 TireConfigInformation 4;
BA_ "SPN" SG_ 2631859966 BinLiftCountReset 6898;
BA_ "SigType" SG_ 2631859966 BinLiftCountReset 4;
BA_ "SPN" SG_ 2631859966 TripGroup1 988;
BA_ "SigType" SG_ 2631859966 TripGroup1 5;
BA_ "SPN" SG_ 2566840830 PercentTorqueAtPeakTorquePoint5 555;
BA_ "SigType" SG_ 2566840830 PercentTorqueAtPeakTorquePoint5 1;
BA_ "SPN" SG_ 2566840830 ReferenceRetarderTorque 556;
BA_ "SigType" SG_ 2566840830 ReferenceRetarderTorque 1;
BA_ "SPN" SG_ 2566840830 RetarderSpeedAtPeakTorquePoint5 547;
BA_ "SigType" SG_ 2566840830 RetarderSpeedAtPeakTorquePoint5 1;
BA_ "SPN" SG_ 2566840830 PercentTorqueAtPoint4 554;
BA_ "SigType" SG_ 2566840830 PercentTorqueAtPoint4 1;
BA_ "SPN" SG_ 2566840830 RetarderSpeedAtPoint4 550;
BA_ "SigType" SG_ 2566840830 RetarderSpeedAtPoint4 1;
BA_ "SPN" SG_ 2566840830 PercentTorqueAtPoint3 553;
BA_ "SigType" SG_ 2566840830 PercentTorqueAtPoint3 1;
BA_ "SPN" SG_ 2566840830 RetarderSpeedAtPoint3 549;
BA_ "SigType" SG_ 2566840830 RetarderSpeedAtPoint3 1;
BA_ "SPN" SG_ 2566840830 PercentTorqueAtMaxSpeedPoint2 552;
BA_ "SigType" SG_ 2566840830 PercentTorqueAtMaxSpeedPoint2 1;
BA_ "SPN" SG_ 2566840830 MaxRetarderSpeedPoint2 548;
BA_ "SigType" SG_ 2566840830 MaxRetarderSpeedPoint2 1;
BA_ "SPN" SG_ 2566840830 PercentTorqueAtIdlePoint1 551;
BA_ "SigType" SG_ 2566840830 PercentTorqueAtIdlePoint1 1;
BA_ "SPN" SG_ 2566840830 RetarderSpeedAtIdlePoint1 546;
BA_ "SigType" SG_ 2566840830 RetarderSpeedAtIdlePoint1 1;
BA_ "SPN" SG_ 2566840830 RetarderCtrlMethod 557;
BA_ "SigType" SG_ 2566840830 RetarderCtrlMethod 1;
BA_ "SPN" SG_ 2566840830 RetarderLocation 902;
BA_ "SPN" SG_ 2566840830 RetarderType 901;
BA_ "SPN" SG_ 2633930238 EngOperationTimeSinceRebuild 1193;
BA_ "SigType" SG_ 2633930238 EngOperationTimeSinceRebuild 1;
BA_ "SPN" SG_ 2566844670 EngPTOGovDisSw 8639;
BA_ "SigType" SG_ 2566844670 EngPTOGovDisSw 4;
BA_ "SPN" SG_ 2566844670 PowerTakeoffSetSpeed 187;
BA_ "SigType" SG_ 2566844670 PowerTakeoffSetSpeed 1;
BA_ "SPN" SG_ 2566844670 PowerTakeoffSpeed 186;
BA_ "SigType" SG_ 2566844670 PowerTakeoffSpeed 1;
BA_ "SPN" SG_ 2566844670 PowerTakeoffOilTemp 90;
BA_ "SigType" SG_ 2566844670 PowerTakeoffOilTemp 1;
BA_ "SPN" SG_ 2566844670 OprtrEngPTOGvrnrMmrySelectSwitch 2897;
BA_ "SigType" SG_ 2566844670 OprtrEngPTOGvrnrMmrySelectSwitch 4;
BA_ "SPN" SG_ 2566844670 EngRmtPTOGvrnrVrblSpedCtrlSwitch 978;
BA_ "SigType" SG_ 2566844670 EngRmtPTOGvrnrVrblSpedCtrlSwitch 4;
BA_ "SPN" SG_ 2566844670 EngRmtPTOGvrnrPrprgrmmdSpdCtrlSw 979;
BA_ "SigType" SG_ 2566844670 EngRmtPTOGvrnrPrprgrmmdSpdCtrlSw 4;
BA_ "SPN" SG_ 2566844670 EngPTOGvrnrCast_DecelerateSwitch 983;
BA_ "SigType" SG_ 2566844670 EngPTOGvrnrCast_DecelerateSwitch 4;
BA_ "SPN" SG_ 2566844670 EngPTOGovernorSetSwitch 984;
BA_ "SigType" SG_ 2566844670 EngPTOGovernorSetSwitch 4;
BA_ "SPN" SG_ 2566844670 EngPTOGovernorResumeSwitch 982;
BA_ "SigType" SG_ 2566844670 EngPTOGovernorResumeSwitch 4;
BA_ "SPN" SG_ 2566844670 EngPTOGovernorEnableSwitch 980;
BA_ "SigType" SG_ 2566844670 EngPTOGovernorEnableSwitch 4;
BA_ "SPN" SG_ 2566844670 EngPTOGovernorAccelerateSwitch 981;
BA_ "SigType" SG_ 2566844670 EngPTOGovernorAccelerateSwitch 4;
BA_ "SPN" SG_ 2566844670 RmtPTOGvrnrPrprgrmmdSpdCtrlSwtch 3447;
BA_ "SigType" SG_ 2566844670 RmtPTOGvrnrPrprgrmmdSpdCtrlSwtch 4;
BA_ "SPN" SG_ 2566844670 AuxInputIgnoreSwitch 3448;
BA_ "SigType" SG_ 2566844670 AuxInputIgnoreSwitch 4;
BA_ "SPN" SG_ 2566770174 RearWasherFunction 2868;
BA_ "SPN" SG_ 2566770174 FrontOperatorWasherSwitch 2866;
BA_ "SPN" SG_ 2566770174 FrontNonoperatorWasherSwitch 2867;
BA_ "SPN" SG_ 2566770174 RearWiperDelayCtrl 2871;
BA_ "SigType" SG_ 2566770174 RearWiperDelayCtrl 1;
BA_ "SPN" SG_ 2566770174 FrontNonoperatorWiperDelayCtrl 2870;
BA_ "SigType" SG_ 2566770174 FrontNonoperatorWiperDelayCtrl 1;
BA_ "SPN" SG_ 2566770174 FrontOperatorWiperDelayCtrl 2869;
BA_ "SigType" SG_ 2566770174 FrontOperatorWiperDelayCtrl 1;
BA_ "SPN" SG_ 2566770174 RearWiperSwitch 2865;
BA_ "SPN" SG_ 2566770174 FrontOperatorWiperSwitch 2863;
BA_ "SPN" SG_ 2566770174 FrontNonoperatorWiperSwitch 2864;
BA_ "SPN" SG_ 2566769662 OperatingModeCmd 8608;
BA_ "SPN" SG_ 2566769662 EngTorqueCurveSelectionCmd 6796;
BA_ "SPN" SG_ 2566769662 EngAltDroopAuxInputSelect 2885;
BA_ "SPN" SG_ 2566769662 EngAltDroopRemoteAccelSelect 2886;
BA_ "SPN" SG_ 2566769662 EngAltDroopAccel2Select 2879;
BA_ "SPN" SG_ 2566769662 EngAltDroopAccel1Select 2881;
BA_ "SPN" SG_ 2566769662 EngAltRatingSelect 2882;
BA_ "SigType" SG_ 2566769662 EngAltRatingSelect 1;
BA_ "SPN" SG_ 2566769662 EngAltLowIdleSwitch 2883;
BA_ "SigType" SG_ 2566769662 EngAltLowIdleSwitch 4;
BA_ "SPN" SG_ 2566769662 EngSynchronizationSwitch 1377;
BA_ "SigType" SG_ 2566769662 EngSynchronizationSwitch 4;
BA_ "SPN" SG_ 2566769662 EngAuxGovernorSwitch 2884;
BA_ "SigType" SG_ 2566769662 EngAuxGovernorSwitch 4;
BA_ "SPN" SG_ 2566768638 OperatingModeSelection 8664;
BA_ "SPN" SG_ 2566768638 EngTorqueCurveSelection 1568;
BA_ "SPN" SG_ 2566768638 EngAltDroopAuxInputSelectState 2895;
BA_ "SPN" SG_ 2566768638 EngAltDropRemoteAccelSelectState 2894;
BA_ "SPN" SG_ 2566768638 EngAltDroopAccel2SelectState 2893;
BA_ "SPN" SG_ 2566768638 EngAltDroopAccel1SelectState 2889;
BA_ "SPN" SG_ 2566768638 EngAltRatingSelectState 2888;
BA_ "SPN" SG_ 2566768638 EngAltLowIdleSelectState 2891;
BA_ "SigType" SG_ 2566768638 EngAltLowIdleSelectState 5;
BA_ "SPN" SG_ 2566768638 EngMultiUnitSyncState 2890;
BA_ "SigType" SG_ 2566768638 EngMultiUnitSyncState 5;
BA_ "SPN" SG_ 2566768638 EngAuxGovernorState 2896;
BA_ "SigType" SG_ 2566768638 EngAuxGovernorState 5;
BA_ "SPN" SG_ 2365443326 OprtorsDesiredDelayedLampOffTime 2877;
BA_ "SigType" SG_ 2365443326 OprtorsDesiredDelayedLampOffTime 1;
BA_ "SPN" SG_ 2365443326 OperatorsDesiredBacklight 2878;
BA_ "SigType" SG_ 2365443326 OperatorsDesiredBacklight 1;
BA_ "SPN" SG_ 2365443326 HighLowBeamSwitch 2874;
BA_ "SigType" SG_ 2365443326 HighLowBeamSwitch 4;
BA_ "SPN" SG_ 2365443326 HazardLightSwitch 2875;
BA_ "SigType" SG_ 2365443326 HazardLightSwitch 4;
BA_ "SPN" SG_ 2365443326 TurnSignalSwitch 2876;
BA_ "SPN" SG_ 2365443326 MainLightSwitch 2872;
BA_ "SPN" SG_ 2365443326 WorkLightSwitch 2873;
BA_ "SPN" SG_ 2566776318 AppliedVehicleSpeedLimit 2595;
BA_ "SigType" SG_ 2566776318 AppliedVehicleSpeedLimit 1;
BA_ "SPN" SG_ 2566776318 MaxVehicleSpeedLimit7 2594;
BA_ "SigType" SG_ 2566776318 MaxVehicleSpeedLimit7 1;
BA_ "SPN" SG_ 2566776318 MaxVehicleSpeedLimit6 2593;
BA_ "SigType" SG_ 2566776318 MaxVehicleSpeedLimit6 1;
BA_ "SPN" SG_ 2566776318 MaxVehicleSpeedLimit5 2592;
BA_ "SigType" SG_ 2566776318 MaxVehicleSpeedLimit5 1;
BA_ "SPN" SG_ 2566776318 MaxVehicleSpeedLimit4 2591;
BA_ "SigType" SG_ 2566776318 MaxVehicleSpeedLimit4 1;
BA_ "SPN" SG_ 2566776318 MaxVehicleSpeedLimit3 2590;
BA_ "SigType" SG_ 2566776318 MaxVehicleSpeedLimit3 1;
BA_ "SPN" SG_ 2566776318 MaxVehicleSpeedLimit2 2589;
BA_ "SigType" SG_ 2566776318 MaxVehicleSpeedLimit2 1;
BA_ "SPN" SG_ 2566776318 MaxVehicleSpeedLimit1 2588;
BA_ "SigType" SG_ 2566776318 MaxVehicleSpeedLimit1 1;
BA_ "SPN" SG_ 2566802686 OprtrsBlackOutIntensitySelection 1844;
BA_ "SigType" SG_ 2566802686 OprtrsBlackOutIntensitySelection 1;
BA_ "SPN" SG_ 2566802686 BlackOutWorkLampSelect 1842;
BA_ "SigType" SG_ 2566802686 BlackOutWorkLampSelect 5;
BA_ "SPN" SG_ 2566802686 NightVisionIlluminatorSelect 1843;
BA_ "SigType" SG_ 2566802686 NightVisionIlluminatorSelect 5;
BA_ "SPN" SG_ 2566802686 BlackOutBrake_StopLampSelect 1841;
BA_ "SigType" SG_ 2566802686 BlackOutBrake_StopLampSelect 5;
BA_ "SPN" SG_ 2566802686 ConvoyDrivingLampSelect 1837;
BA_ "SigType" SG_ 2566802686 ConvoyDrivingLampSelect 5;
BA_ "SPN" SG_ 2566802686 ConvoyLampSelect 1838;
BA_ "SigType" SG_ 2566802686 ConvoyLampSelect 5;
BA_ "SPN" SG_ 2566802686 FrontBlackOutMarkerLampSelect 1839;
BA_ "SigType" SG_ 2566802686 FrontBlackOutMarkerLampSelect 5;
BA_ "SPN" SG_ 2566802686 RearBlackOutMarkerSelect 1840;
BA_ "SigType" SG_ 2566802686 RearBlackOutMarkerSelect 5;
BA_ "SPN" SG_ 2566774014 EngMarineOperatingModeStatus 7845;
BA_ "SPN" SG_ 2566774014 SlowVesselModeStatus 2617;
BA_ "SigType" SG_ 2566774014 SlowVesselModeStatus 5;
BA_ "SPN" SG_ 2566774014 TrollingModeStatus 2616;
BA_ "SigType" SG_ 2566774014 TrollingModeStatus 5;
BA_ "SPN" SG_ 2566774014 EngThrttlSynchrnzationModeStatus 2615;
BA_ "SPN" SG_ 2566823166 EngMainBearing12Temp 6830;
BA_ "SigType" SG_ 2566823166 EngMainBearing12Temp 1;
BA_ "SPN" SG_ 2566823166 EngMainBearing11Temp 1167;
BA_ "SigType" SG_ 2566823166 EngMainBearing11Temp 1;
BA_ "SPN" SG_ 2566823166 EngMainBearing10Temp 1166;
BA_ "SigType" SG_ 2566823166 EngMainBearing10Temp 1;
BA_ "SPN" SG_ 2566823166 EngMainBearing9Temp 1165;
BA_ "SigType" SG_ 2566823166 EngMainBearing9Temp 1;
BA_ "SPN" SG_ 2566823422 EngMainBearing8Temp 1164;
BA_ "SigType" SG_ 2566823422 EngMainBearing8Temp 1;
BA_ "SPN" SG_ 2566823422 EngMainBearing7Temp 1163;
BA_ "SigType" SG_ 2566823422 EngMainBearing7Temp 1;
BA_ "SPN" SG_ 2566823422 EngMainBearing6Temp 1162;
BA_ "SigType" SG_ 2566823422 EngMainBearing6Temp 1;
BA_ "SPN" SG_ 2566823422 EngMainBearing5Temp 1161;
BA_ "SigType" SG_ 2566823422 EngMainBearing5Temp 1;
BA_ "SPN" SG_ 2566823678 EngMainBearing4Temp 1160;
BA_ "SigType" SG_ 2566823678 EngMainBearing4Temp 1;
BA_ "SPN" SG_ 2566823678 EngMainBearing3Temp 1159;
BA_ "SigType" SG_ 2566823678 EngMainBearing3Temp 1;
BA_ "SPN" SG_ 2566823678 EngMainBearing2Temp 1158;
BA_ "SigType" SG_ 2566823678 EngMainBearing2Temp 1;
BA_ "SPN" SG_ 2566823678 EngMainBearing1Temp 1157;
BA_ "SigType" SG_ 2566823678 EngMainBearing1Temp 1;
BA_ "SPN" SG_ 2432595710 DisplayDeadbands 2577;
BA_ "SPN" SG_ 2432595710 LEDPatternCtrl 2578;
BA_ "SPN" SG_ 2432595710 LEDDisplayDeadbandCtrl 1806;
BA_ "SPN" SG_ 2432595710 LEDDisplayModeCtrl 1805;
BA_ "SPN" SG_ 2432595710 LEDDisplayData1 1573;
BA_ "SPN" SG_ 2365486590 AbsLaserStrikePos 2794;
BA_ "SigType" SG_ 2365486590 AbsLaserStrikePos 1;
BA_ "SPN" SG_ 2365486590 LaserStrikeDataLatency 2793;
BA_ "SigType" SG_ 2365486590 LaserStrikeDataLatency 1;
BA_ "SPN" SG_ 2365486590 LaserReceiverType 2576;
BA_ "SigType" SG_ 2365486590 LaserReceiverType 1;
BA_ "SPN" SG_ 2365486590 LaserStrikeVerticalDeviation 1574;
BA_ "SigType" SG_ 2365486590 LaserStrikeVerticalDeviation 1;
BA_ "SPN" SG_ 2365485566 LaserTracerInformation 1583;
BA_ "SPN" SG_ 2365485566 LEDDisplayData2 1582;
BA_ "SPN" SG_ 2365485566 LaserTracerHorizontalDeviation 1581;
BA_ "SigType" SG_ 2365485566 LaserTracerHorizontalDeviation 1;
BA_ "SPN" SG_ 2365485566 LaserTracerVerticalDistance 1580;
BA_ "SigType" SG_ 2365485566 LaserTracerVerticalDistance 1;
BA_ "SPN" SG_ 2365485566 LaserTracerTargetDeviation 1579;
BA_ "SigType" SG_ 2365485566 LaserTracerTargetDeviation 1;
BA_ "SPN" SG_ 2633939454 TripDriveFuelEconomy 1006;
BA_ "SigType" SG_ 2633939454 TripDriveFuelEconomy 1;
BA_ "SPN" SG_ 2633939454 TripCruiseFuelUsed 1005;
BA_ "SigType" SG_ 2633939454 TripCruiseFuelUsed 1;
BA_ "SPN" SG_ 2633939454 TripVehicleIdleFuelUsed 1004;
BA_ "SigType" SG_ 2633939454 TripVehicleIdleFuelUsed 1;
BA_ "SPN" SG_ 2633939454 TripPTOGovernorNonmovingFuelUsed 1003;
BA_ "SigType" SG_ 2633939454 TripPTOGovernorNonmovingFuelUsed 1;
BA_ "SPN" SG_ 2633939454 TripPTOGovernorMovingFuelUsed 1002;
BA_ "SigType" SG_ 2633939454 TripPTOGovernorMovingFuelUsed 1;
BA_ "SPN" SG_ 2633939454 TripDriveFuelUsed 1001;
BA_ "SigType" SG_ 2633939454 TripDriveFuelUsed 1;
BA_ "SPN" SG_ 2365486334 BldeHeightSetPointHighResolution 1759;
BA_ "SigType" SG_ 2365486334 BldeHeightSetPointHighResolution 1;
BA_ "SPN" SG_ 2365486334 ModifyLevelingSystemSetPoint 1575;
BA_ "SigType" SG_ 2365486334 ModifyLevelingSystemSetPoint 1;
BA_ "SPN" SG_ 2364542462 StElvtnSensor2ReferenceElevation 5406;
BA_ "SigType" SG_ 2364542462 StElvtnSensor2ReferenceElevation 5;
BA_ "SPN" SG_ 2364542462 StElvtnSensor1ReferenceElevation 5405;
BA_ "SigType" SG_ 2364542462 StElvtnSensor1ReferenceElevation 5;
BA_ "SPN" SG_ 2364542462 SdshftDsrdBldeOffsetOperatorCtrl 3339;
BA_ "SPN" SG_ 2364542462 SdshiftBladeCtrlModeOperatorCtrl 3338;
BA_ "SPN" SG_ 2364542462 RghtDsredBladeOffsetOperatorCtrl 3337;
BA_ "SPN" SG_ 2364542462 LftDsiredBladeOffsetOperatorCtrl 3336;
BA_ "SPN" SG_ 2364542462 RightBladeCtrlModeOperatorCtrl 3335;
BA_ "SPN" SG_ 2364542462 LeftBladeCtrlModeOperatorCtrl 3334;
BA_ "SPN" SG_ 2364542462 BladeAutoModeCmd 3158;
BA_ "SPN" SG_ 2364542462 DesiredGradeOffsetSwitch 3157;
BA_ "SPN" SG_ 2364542462 BladeCtrlModeSwitch 3156;
BA_ "SPN" SG_ 2365486078 MastPos 1576;
BA_ "SigType" SG_ 2365486078 MastPos 1;
BA_ "SPN" SG_ 2633937918 FlexibleFuelPercentage 5458;
BA_ "SigType" SG_ 2633937918 FlexibleFuelPercentage 1;
BA_ "SPN" SG_ 2633937918 TripAverageFuelRate 1029;
BA_ "SigType" SG_ 2633937918 TripAverageFuelRate 1;
BA_ "SPN" SG_ 2633937918 TotalEngPTOGovernorFuelUsed 1028;
BA_ "SigType" SG_ 2633937918 TotalEngPTOGovernorFuelUsed 1;
BA_ "SPN" SG_ 2566845182 EngThrottleValve2Pos 3673;
BA_ "SigType" SG_ 2566845182 EngThrottleValve2Pos 1;
BA_ "SPN" SG_ 2566845182 EngThrottleValve1Pos 51;
BA_ "SigType" SG_ 2566845182 EngThrottleValve1Pos 1;
BA_ "SPN" SG_ 2566845182 EngAverageFuelEconomy 185;
BA_ "SigType" SG_ 2566845182 EngAverageFuelEconomy 1;
BA_ "SPN" SG_ 2566845182 EngInstantaneousFuelEconomy 184;
BA_ "SigType" SG_ 2566845182 EngInstantaneousFuelEconomy 1;
BA_ "SPN" SG_ 2566845182 EngFuelRate 183;
BA_ "SigType" SG_ 2566845182 EngFuelRate 1;
BA_ "SPN" SG_ 2566842878 EngTotalFuelUsed 250;
BA_ "SigType" SG_ 2566842878 EngTotalFuelUsed 1;
BA_ "SPN" SG_ 2566842878 EngTripFuel 182;
BA_ "SigType" SG_ 2566842878 EngTripFuel 1;
BA_ "SPN" SG_ 2633883646 FrontWheelDriveActuatorStatus 2612;
BA_ "SigType" SG_ 2633883646 FrontWheelDriveActuatorStatus 4;
BA_ "SPN" SG_ 2633880062 FMSstandardSWversionSupported 2806;
BA_ "SigType" SG_ 2633880062 FMSstandardSWversionSupported 1;
BA_ "SPN" SG_ 2633880062 FMSstandardRequestsSupported 2805;
BA_ "SigType" SG_ 2633880062 FMSstandardRequestsSupported 5;
BA_ "SPN" SG_ 2633880062 FMSstandardDiagnosticsSupported 2804;
BA_ "SigType" SG_ 2633880062 FMSstandardDiagnosticsSupported 5;
BA_ "SPN" SG_ 2566806526 ImagerStatus 8142;
BA_ "SPN" SG_ 2566806526 DepWarnSysSt 8141;
BA_ "SPN" SG_ 2566806526 RightWheelLaneDepDist 8140;
BA_ "SigType" SG_ 2566806526 RightWheelLaneDepDist 1;
BA_ "SPN" SG_ 2566806526 LeftWheelLaneDepDist 8139;
BA_ "SigType" SG_ 2566806526 LeftWheelLaneDepDist 1;
BA_ "SPN" SG_ 2566806526 DrverAlertnessWarningSystemState 7475;
BA_ "SPN" SG_ 2566806526 DriverAlertnessLevel 7474;
BA_ "SigType" SG_ 2566806526 DriverAlertnessLevel 1;
BA_ "SPN" SG_ 2566806526 LnDpartureIndicationEnableStatus 1702;
BA_ "SigType" SG_ 2566806526 LnDpartureIndicationEnableStatus 5;
BA_ "SPN" SG_ 2566806526 LaneTrackingStatusLeftSide 1710;
BA_ "SigType" SG_ 2566806526 LaneTrackingStatusLeftSide 5;
BA_ "SPN" SG_ 2566806526 LaneTrackingStatusRightSide 1711;
BA_ "SigType" SG_ 2566806526 LaneTrackingStatusRightSide 5;
BA_ "SPN" SG_ 2431649790 LeftSideLaneDepHapticWarnCmd 9750;
BA_ "SigType" SG_ 2431649790 LeftSideLaneDepHapticWarnCmd 5;
BA_ "SPN" SG_ 2431649790 RightSideLaneDepHapticWarnCmd 9749;
BA_ "SigType" SG_ 2431649790 RightSideLaneDepHapticWarnCmd 5;
BA_ "SPN" SG_ 2431649790 LeftSideLaneDepAcstWarnCmd 8138;
BA_ "SigType" SG_ 2431649790 LeftSideLaneDepAcstWarnCmd 5;
BA_ "SPN" SG_ 2431649790 RightSideLaneDepAcstWarnCmd 8137;
BA_ "SigType" SG_ 2431649790 RightSideLaneDepAcstWarnCmd 5;
BA_ "SPN" SG_ 2431649790 LeftSideLaneDepOpticalWarnCmd 8136;
BA_ "SigType" SG_ 2431649790 LeftSideLaneDepOpticalWarnCmd 5;
BA_ "SPN" SG_ 2431649790 RightSideLaneDepOpticalWarnCmd 8135;
BA_ "SigType" SG_ 2431649790 RightSideLaneDepOpticalWarnCmd 5;
BA_ "SPN" SG_ 2431649790 LaneDepartureImminentLeftSide 1700;
BA_ "SigType" SG_ 2431649790 LaneDepartureImminentLeftSide 5;
BA_ "SPN" SG_ 2431649790 LaneDepartureImminentRightSide 1701;
BA_ "SigType" SG_ 2431649790 LaneDepartureImminentRightSide 5;
BA_ "SPN" SG_ 2431649790 LaneDepartureRight 3566;
BA_ "SigType" SG_ 2431649790 LaneDepartureRight 5;
BA_ "SPN" SG_ 2431649790 LaneDepartureLeft 3565;
BA_ "SigType" SG_ 2431649790 LaneDepartureLeft 5;
BA_ "SPN" SG_ 2431649790 DriverAlertnessWarning 7473;
BA_ "SPN" SG_ 2633929214 EngFluidBundLvl 7785;
BA_ "SigType" SG_ 2633929214 EngFluidBundLvl 1;
BA_ "SPN" SG_ 2633929214 EngFuelLeakage2 1240;
BA_ "SigType" SG_ 2633929214 EngFuelLeakage2 5;
BA_ "SPN" SG_ 2633929214 EngFuelLeakage1 1239;
BA_ "SigType" SG_ 2633929214 EngFuelLeakage1 5;
BA_ "SPN" SG_ 2566831614 FanDriveBypassCmdStatus 4212;
BA_ "SigType" SG_ 2566831614 FanDriveBypassCmdStatus 1;
BA_ "SPN" SG_ 2566831614 HydFanMotorPress 4211;
BA_ "SigType" SG_ 2566831614 HydFanMotorPress 1;
BA_ "SPN" SG_ 2566831614 FanSpeed 1639;
BA_ "SigType" SG_ 2566831614 FanSpeed 1;
BA_ "SPN" SG_ 2566831614 FanDriveState 977;
BA_ "SPN" SG_ 2566831614 EstPercentFanSpeed 975;
BA_ "SigType" SG_ 2566831614 EstPercentFanSpeed 1;
BA_ "SPN" SG_ 2566820094 EngTorqueLimit6AxleInput 1263;
BA_ "SigType" SG_ 2566820094 EngTorqueLimit6AxleInput 1;
BA_ "SPN" SG_ 2566820094 EngTorqueLimit5Switch 1262;
BA_ "SigType" SG_ 2566820094 EngTorqueLimit5Switch 1;
BA_ "SPN" SG_ 2566820094 EngTorqueLimit4Trans 1261;
BA_ "SigType" SG_ 2566820094 EngTorqueLimit4Trans 1;
BA_ "SPN" SG_ 2566820094 EngTorqueLimit3Trans 1260;
BA_ "SigType" SG_ 2566820094 EngTorqueLimit3Trans 1;
BA_ "SPN" SG_ 2566820094 TransGearRatio3 1259;
BA_ "SigType" SG_ 2566820094 TransGearRatio3 1;
BA_ "SPN" SG_ 2566820094 EngTorqueLimit2Trans 1258;
BA_ "SigType" SG_ 2566820094 EngTorqueLimit2Trans 1;
BA_ "SPN" SG_ 2566820094 TransGearRatio2 1257;
BA_ "SigType" SG_ 2566820094 TransGearRatio2 1;
BA_ "SPN" SG_ 2566820094 EngTorqueLimit1Trans 1256;
BA_ "SigType" SG_ 2566820094 EngTorqueLimit1Trans 1;
BA_ "SPN" SG_ 2566820094 TransGearRatio1 1255;
BA_ "SigType" SG_ 2566820094 TransGearRatio1 1;
BA_ "SPN" SG_ 2566820094 EngTorqueLimitFeature 1632;
BA_ "SPN" SG_ 2566820094 TorqueLimitingFeatureStatus 1254;
BA_ "SigType" SG_ 2566820094 TorqueLimitingFeatureStatus 5;
BA_ "SPN" SG_ 2566820094 CalibRecordDurationTime 1253;
BA_ "SigType" SG_ 2566820094 CalibRecordDurationTime 1;
BA_ "SPN" SG_ 2566820094 CalibRecordStartYear 1252;
BA_ "SigType" SG_ 2566820094 CalibRecordStartYear 1;
BA_ "SPN" SG_ 2566820094 CalibRecordStartDay 1251;
BA_ "GenSigStartValue" SG_ 2566820094 CalibRecordStartDay 1;
BA_ "SigType" SG_ 2566820094 CalibRecordStartDay 1;
BA_ "SPN" SG_ 2566820094 CalibRecordStartMonth 1250;
BA_ "GenSigStartValue" SG_ 2566820094 CalibRecordStartMonth 1;
BA_ "SigType" SG_ 2566820094 CalibRecordStartMonth 1;
BA_ "SPN" SG_ 2566820094 EngPeakTorque2 1249;
BA_ "SigType" SG_ 2566820094 EngPeakTorque2 1;
BA_ "SPN" SG_ 2566820094 EngPeakTorque1 1248;
BA_ "SigType" SG_ 2566820094 EngPeakTorque1 1;
BA_ "SPN" SG_ 2566820094 EngPower 1247;
BA_ "SigType" SG_ 2566820094 EngPower 1;
BA_ "SPN" SG_ 2566820094 NumberOfEngTorqueHistoryRecords 1246;
BA_ "SigType" SG_ 2566820094 NumberOfEngTorqueHistoryRecords 1;
BA_ "SPN" SG_ 2364542206 TransClutch_ConverterInputSpeed 5052;
BA_ "SigType" SG_ 2364542206 TransClutch_ConverterInputSpeed 1;
BA_ "SPN" SG_ 2364542206 TransTorqueConverterRatio 3030;
BA_ "SigType" SG_ 2364542206 TransTorqueConverterRatio 1;
BA_ "SPN" SG_ 2566802174 ManualModeInd 8291;
BA_ "SigType" SG_ 2566802174 ManualModeInd 5;
BA_ "SPN" SG_ 2566802174 TransAutoNeutralSt 7696;
BA_ "SigType" SG_ 2566802174 TransAutoNeutralSt 5;
BA_ "SPN" SG_ 2566802174 TransWarningIndicator 5344;
BA_ "SigType" SG_ 2566802174 TransWarningIndicator 5;
BA_ "SPN" SG_ 2566802174 TrnsRverseGearShiftInhibitStatus 4261;
BA_ "SigType" SG_ 2566802174 TrnsRverseGearShiftInhibitStatus 4;
BA_ "SPN" SG_ 2566802174 TransMode8Indicator 4253;
BA_ "SigType" SG_ 2566802174 TransMode8Indicator 4;
BA_ "SPN" SG_ 2566802174 TransMode7Indicator 4252;
BA_ "SigType" SG_ 2566802174 TransMode7Indicator 4;
BA_ "SPN" SG_ 2566802174 TransMode6Indicator 4251;
BA_ "SigType" SG_ 2566802174 TransMode6Indicator 4;
BA_ "SPN" SG_ 2566802174 TransMode5Indicator 4250;
BA_ "SigType" SG_ 2566802174 TransMode5Indicator 4;
BA_ "SPN" SG_ 2566802174 TransRequestedGearFeedback 3289;
BA_ "SigType" SG_ 2566802174 TransRequestedGearFeedback 1;
BA_ "SPN" SG_ 2566802174 TransMode1Indicator 2536;
BA_ "SigType" SG_ 2566802174 TransMode1Indicator 4;
BA_ "SPN" SG_ 2566802174 TransMode2Indicator 2537;
BA_ "SigType" SG_ 2566802174 TransMode2Indicator 4;
BA_ "SPN" SG_ 2566802174 TransMode3Indicator 2538;
BA_ "SigType" SG_ 2566802174 TransMode3Indicator 4;
BA_ "SPN" SG_ 2566802174 TransMode4Indicator 2539;
BA_ "SigType" SG_ 2566802174 TransMode4Indicator 4;
BA_ "SPN" SG_ 2566802174 TransShiftInhibitIndicator 1851;
BA_ "SigType" SG_ 2566802174 TransShiftInhibitIndicator 5;
BA_ "SPN" SG_ 2566802174 TransEngCrankEnable 2900;
BA_ "SigType" SG_ 2566802174 TransEngCrankEnable 5;
BA_ "SPN" SG_ 2566802174 ActiveShiftConsoleIndicator 2945;
BA_ "SigType" SG_ 2566802174 ActiveShiftConsoleIndicator 5;
BA_ "SPN" SG_ 2566802174 TransReadyForBrakeRelease 3086;
BA_ "SigType" SG_ 2566802174 TransReadyForBrakeRelease 5;
BA_ "SPN" SG_ 2566802174 TrnsRqstedRangeDisplayFlashState 1849;
BA_ "SigType" SG_ 2566802174 TrnsRqstedRangeDisplayFlashState 5;
BA_ "SPN" SG_ 2566802174 TrnsRqstedRangeDisplayBlankState 1850;
BA_ "SigType" SG_ 2566802174 TrnsRqstedRangeDisplayBlankState 5;
BA_ "SPN" SG_ 2566802174 TransServiceIndicator 4178;
BA_ "SigType" SG_ 2566802174 TransServiceIndicator 5;
BA_ "SPN" SG_ 2566802174 TransAirSupplyPressIndicator 6566;
BA_ "SigType" SG_ 2566802174 TransAirSupplyPressIndicator 4;
BA_ "SPN" SG_ 2566802174 TransMode10Indicator 6568;
BA_ "SigType" SG_ 2566802174 TransMode10Indicator 4;
BA_ "SPN" SG_ 2566802174 TransMode9Indicator 6567;
BA_ "SigType" SG_ 2566802174 TransMode9Indicator 4;
BA_ "SPN" SG_ 2566802174 TrnsCrrentRangeDisplayBlankState 4176;
BA_ "SigType" SG_ 2566802174 TrnsCrrentRangeDisplayBlankState 5;
BA_ "SPN" SG_ 2633935870 ClutchLifeRemaining 2983;
BA_ "SigType" SG_ 2633935870 ClutchLifeRemaining 1;
BA_ "SPN" SG_ 2633935870 LowestPossibleGear 1114;
BA_ "SigType" SG_ 2633935870 LowestPossibleGear 1;
BA_ "SPN" SG_ 2633935870 HighestPossibleGear 1115;
BA_ "SigType" SG_ 2633935870 HighestPossibleGear 1;
BA_ "SPN" SG_ 2633935870 RecommendedGear 1113;
BA_ "SigType" SG_ 2633935870 RecommendedGear 1;
BA_ "SPN" SG_ 2633942014 TransForwardDirectionSwitch 903;
BA_ "SigType" SG_ 2633942014 TransForwardDirectionSwitch 5;
BA_ "SPN" SG_ 2633942014 TransNeutralSwitch 604;
BA_ "SigType" SG_ 2633942014 TransNeutralSwitch 5;
BA_ "SPN" SG_ 2633942014 TransReverseDirectionSwitch 767;
BA_ "SigType" SG_ 2633942014 TransReverseDirectionSwitch 5;
BA_ "SPN" SG_ 2633942014 TransLowRangeSenseSwitch 779;
BA_ "SigType" SG_ 2633942014 TransLowRangeSenseSwitch 5;
BA_ "SPN" SG_ 2633942014 TransHighRangeSenseSwitch 778;
BA_ "SigType" SG_ 2633942014 TransHighRangeSenseSwitch 5;
BA_ "SPN" SG_ 2633942526 TransSynchronizerBrakeValue 54;
BA_ "SigType" SG_ 2633942526 TransSynchronizerBrakeValue 1;
BA_ "SPN" SG_ 2633942526 TransSynchronizerClutchValue 53;
BA_ "SigType" SG_ 2633942526 TransSynchronizerClutchValue 1;
BA_ "SPN" SG_ 2633943038 TransInertiaBrakeActuator 787;
BA_ "SigType" SG_ 2633943038 TransInertiaBrakeActuator 5;
BA_ "SPN" SG_ 2633943038 TransDefuelActuator 786;
BA_ "SigType" SG_ 2633943038 TransDefuelActuator 5;
BA_ "SPN" SG_ 2633943038 TransLockupClutchActuator 740;
BA_ "SigType" SG_ 2633943038 TransLockupClutchActuator 5;
BA_ "SPN" SG_ 2633943038 TransClutchActuator 788;
BA_ "SigType" SG_ 2633943038 TransClutchActuator 5;
BA_ "SPN" SG_ 2633943038 TransSplitterIndirectActuator 771;
BA_ "SigType" SG_ 2633943038 TransSplitterIndirectActuator 5;
BA_ "SPN" SG_ 2633943038 TransSplitterDirectActuator 770;
BA_ "SigType" SG_ 2633943038 TransSplitterDirectActuator 5;
BA_ "SPN" SG_ 2633943038 TransRangeLowActuator 769;
BA_ "SigType" SG_ 2633943038 TransRangeLowActuator 5;
BA_ "SPN" SG_ 2633943038 TransRangeHighActuator 768;
BA_ "SigType" SG_ 2633943038 TransRangeHighActuator 5;
BA_ "SPN" SG_ 2633943038 TransShiftFingerGearActuator2 784;
BA_ "SigType" SG_ 2633943038 TransShiftFingerGearActuator2 5;
BA_ "SPN" SG_ 2633943038 TransShiftFingerRailActuator2 783;
BA_ "SigType" SG_ 2633943038 TransShiftFingerRailActuator2 5;
BA_ "SPN" SG_ 2633943038 TransShiftFingerGearActuator1 773;
BA_ "SigType" SG_ 2633943038 TransShiftFingerGearActuator1 5;
BA_ "SPN" SG_ 2633943038 TransShiftFingerRailActuator1 772;
BA_ "SigType" SG_ 2633943038 TransShiftFingerRailActuator1 5;
BA_ "SPN" SG_ 2633943038 TrnsShftFngerCenterRailIndicator 782;
BA_ "SigType" SG_ 2633943038 TrnsShftFngerCenterRailIndicator 5;
BA_ "SPN" SG_ 2633943038 TrnsShftFngerEngagementIndicator 781;
BA_ "SigType" SG_ 2633943038 TrnsShftFngerEngagementIndicator 5;
BA_ "SPN" SG_ 2633943038 TransShiftFingerNeutralIndicator 780;
BA_ "SigType" SG_ 2633943038 TransShiftFingerNeutralIndicator 5;
BA_ "SPN" SG_ 2633943038 TransShiftFingerRailPos 60;
BA_ "SigType" SG_ 2633943038 TransShiftFingerRailPos 1;
BA_ "SPN" SG_ 2633943038 TransShiftFingerGearPos 59;
BA_ "SigType" SG_ 2633943038 TransShiftFingerGearPos 1;
BA_ "SPN" SG_ 2565867006 TransCurrentRange 163;
BA_ "SigType" SG_ 2565867006 TransCurrentRange 1;
BA_ "SPN" SG_ 2565867006 TransRequestedRange 162;
BA_ "SigType" SG_ 2565867006 TransRequestedRange 1;
BA_ "SPN" SG_ 2565867006 TransCurrentGear 523;
BA_ "SigType" SG_ 2565867006 TransCurrentGear 1;
BA_ "SPN" SG_ 2565867006 TransActualGearRatio 526;
BA_ "SigType" SG_ 2565867006 TransActualGearRatio 1;
BA_ "SPN" SG_ 2565867006 TransSelectedGear 524;
BA_ "SigType" SG_ 2565867006 TransSelectedGear 1;
BA_ "SPN" SG_ 2364539646 SrcAddrssOfCntrllngDvcFrTrnsCtrl 1482;
BA_ "SPN" SG_ 2364539646 TransInputShaftSpeed 161;
BA_ "SigType" SG_ 2364539646 TransInputShaftSpeed 1;
BA_ "SPN" SG_ 2364539646 MomentaryEngMaxPowerEnable 5015;
BA_ "SigType" SG_ 2364539646 MomentaryEngMaxPowerEnable 5;
BA_ "SPN" SG_ 2364539646 ProgressiveShiftDisable 607;
BA_ "SigType" SG_ 2364539646 ProgressiveShiftDisable 5;
BA_ "SPN" SG_ 2364539646 EngMomentaryOverspeedEnable 606;
BA_ "SigType" SG_ 2364539646 EngMomentaryOverspeedEnable 5;
BA_ "SPN" SG_ 2364539646 PercentClutchSlip 522;
BA_ "SigType" SG_ 2364539646 PercentClutchSlip 1;
BA_ "SPN" SG_ 2364539646 TransOutputShaftSpeed 191;
BA_ "SigType" SG_ 2364539646 TransOutputShaftSpeed 1;
BA_ "SPN" SG_ 2364539646 TrnsTrqCnvrtrLckpTrnstnInProcess 4816;
BA_ "SigType" SG_ 2364539646 TrnsTrqCnvrtrLckpTrnstnInProcess 4;
BA_ "SPN" SG_ 2364539646 TransShiftInProcess 574;
BA_ "SigType" SG_ 2364539646 TransShiftInProcess 4;
BA_ "SPN" SG_ 2364539646 TrnsTorqueConverterLockupEngaged 573;
BA_ "SigType" SG_ 2364539646 TrnsTorqueConverterLockupEngaged 5;
BA_ "SPN" SG_ 2364539646 TransDrivelineEngaged 560;
BA_ "SigType" SG_ 2364539646 TransDrivelineEngaged 4;
BA_ "SPN" SG_ 2566810110 EngChargeAirCooler1OutletTemp 2630;
BA_ "SigType" SG_ 2566810110 EngChargeAirCooler1OutletTemp 1;
BA_ "SPN" SG_ 2566810110 EngIntkVlvActuationSystemOilTemp 2986;
BA_ "SigType" SG_ 2566810110 EngIntkVlvActuationSystemOilTemp 1;
BA_ "SPN" SG_ 2566810110 EngCoolantTemp 1637;
BA_ "SigType" SG_ 2566810110 EngCoolantTemp 1;
BA_ "SPN" SG_ 2566810110 EngIntakeManifold1AirTemp 1636;
BA_ "SigType" SG_ 2566810110 EngIntakeManifold1AirTemp 1;
BA_ "SPN" SG_ 2566825214 EngExhaustGasRecirculation1Temp 412;
BA_ "SigType" SG_ 2566825214 EngExhaustGasRecirculation1Temp 1;
BA_ "SPN" SG_ 2566825214 EngExhstGsRcirculation1DiffPress 411;
BA_ "SigType" SG_ 2566825214 EngExhstGsRcirculation1DiffPress 1;
BA_ "SPN" SG_ 2566825214 EngECUTemp 1136;
BA_ "SigType" SG_ 2566825214 EngECUTemp 1;
BA_ "SPN" SG_ 2566825214 EngOilTemp2 1135;
BA_ "SigType" SG_ 2566825214 EngOilTemp2 1;
BA_ "SPN" SG_ 2566844158 EngIntercoolerThermostatOpening 1134;
BA_ "SigType" SG_ 2566844158 EngIntercoolerThermostatOpening 1;
BA_ "SPN" SG_ 2566844158 EngIntercoolerTemp 52;
BA_ "SigType" SG_ 2566844158 EngIntercoolerTemp 1;
BA_ "SPN" SG_ 2566844158 EngTurboOilTemp 176;
BA_ "SigType" SG_ 2566844158 EngTurboOilTemp 1;
BA_ "SPN" SG_ 2566844158 EngOilTemp1 175;
BA_ "SigType" SG_ 2566844158 EngOilTemp1 1;
BA_ "SPN" SG_ 2566844158 EngFuelTemp1 174;
BA_ "SigType" SG_ 2566844158 EngFuelTemp1 1;
BA_ "SPN" SG_ 2566844158 EngCoolantTemp 110;
BA_ "SigType" SG_ 2566844158 EngCoolantTemp 1;
BA_ "SPN" SG_ 2566785022 EngExhaustManifoldBank1Temp2 5970;
BA_ "SigType" SG_ 2566785022 EngExhaustManifoldBank1Temp2 1;
BA_ "SPN" SG_ 2566785022 EngExhaustManifoldBank2Temp2 5969;
BA_ "SigType" SG_ 2566785022 EngExhaustManifoldBank2Temp2 1;
BA_ "SPN" SG_ 2566785022 EngExhaustGasTempLeftManifold 2434;
BA_ "SigType" SG_ 2566785022 EngExhaustGasTempLeftManifold 1;
BA_ "SPN" SG_ 2566785022 EngExhaustGasTempRightManifold 2433;
BA_ "SigType" SG_ 2566785022 EngExhaustGasTempRightManifold 1;
VAL_ 2566786302 VehicleSystem5 127 "Not Available" 0 "Ind. Process Control Stationary" ;
VAL_ 2566786302 VehicleSystem4 125 "Entertainment" 120 "Display" 85 "External Environment" 75 "Sensor Communication Interface" 35 "Electrical Generation" 100 "Deck, Cargo and Fishing Equipment" 90 "Internal Environment" 80 "Instrumentation/General Systems (deprecate)" 70 "Communications" 60 "Navigation" 50 "Propulsion" 40 "Steering and Control Surfaces" 30 "Electrical Distribution" 25 "Inter/Intranetwork Device" 20 "Safety Systems" 10 "System Tools" 127 "Not Available" 0 "Non-specific System" ;
VAL_ 2566786302 VehicleSystem3 8 "Grader" 7 "Four Wheel Drive Loader" 6 "Forklift" 5 "Excavator" 4 "Crawler" 3 "Backhoe" 2 "Articulated Dump Truck" 1 "Skid Steer Loader" 127 "Not Available" 0 "Non-specific System" ;
VAL_ 2566786302 VehicleSystem2 25 "Slurry Applicators" 24 "Utility Vehicles" 23 "Mulchers" 22 "Timber Processing Machines" 21 "Timber loaders" 20 "Forwarders" 19 "Timber Harvesters" 17 "Sensor Systems" 16 "Skidder" 15 "Earth Work" 14 "Special Crops" 13 "Powered Auxiliary Device" 12 "Farm Yard Operations" 11 "Transport/Trailer" 10 "Irrigation" 9 "Forage" 8 "Root Harvesters" 7 "Harvesters" 6 "Sprayers" 5 "Fertilizers" 4 "Planters/Seeders" 3 "Secondary Tillage" 2 "Tillage" 1 "Tractor" 127 "Not Available" 0 "Non-specific System" ;
VAL_ 2566786302 VehicleSystem1 2 "Trailer" 1 "Tractor" 127 "Not Available" 0 "Non-specific System" ;
VAL_ 2566786302 IndustryGroup 6 "Reserved for SAE" 7 "Reserved for SAE" 5 "IndustrialProcessCtrlStationary" 4 "Marine" 3 "Construction" 2 "Agricultural and Forestry" 1 "On-Highway" 0 "Global" ;
VAL_ 2566786302 VehicleSystem 0 "Non-specific System" 127 "Not Available" ;
VAL_ 2566786302 Function 127 "Reserved" 126 "Reserved" 125 "Reserved" 124 "Reserved" 123 "Reserved" 122 "Reserved" 121 "Reserved" 120 "Reserved" 119 "Reserved" 118 "Reserved" 117 "Reserved" 116 "Reserved" 115 "Reserved" 114 "Reserved" 113 "Reserved" 112 "Reserved" 111 "Reserved" 110 "Reserved" 109 "Reserved" 108 "Reserved" 107 "Reserved" 106 "Reserved" 105 "Reserved" 104 "Reserved" 103 "Reserved" 102 "Reserved" 101 "Reserved" 42 "Water Pump Control" 41 "Lighting - Operator Controls" 40 "Seat Control" 39 "Ignition Control Module" 38 "Tire Pressure Control" 37 "Cab Controller" 36 "Pneumatic - System Controller" 35 "Suspension - System Controller" 34 "Hydraulic Pump Controller" 33 "System Monitor" 32 "Headway Controller" 31 "Propulsion Battery Charger" 30 "Management Computer" 29 "Virtual Terminal (in cab)" 28 "Off Vehicle Gateway" 27 "Power TakeOff (Secondary or Front)" 26 "Body Controller" 25 "Network Interconnect ECU" 24 "Vehicle Security" 23 "Vehicle Navigation" 22 "Aerodynamic Control" 21 "Cab Climate Control" 20 "Trip Recorder" 19 "Instrument Cluster" 18 "Suspension - Drive Axle" 17 "Suspension - Steer Axle" 16 "Steering Controller" 15 "Fuel System" 14 "Cruise Control" 13 "Retarder - Driveline" 12 "Retarder - Engine" 11 "Brakes - Drive Axle" 10 "Brakes - Steer Axle" 9 "Brakes - System Controller" 8 "Axle - Drive" 7 "Axle - Steering" 6 "Power TakeOff - (Main or Rear)" 5 "Shift Control/Console" 4 "Battery Pack Monitor" 3 "Transmission" 2 "Electric Propulsion Control" 1 "Auxiliary Power Unit (APU)" 0 "Engine" 100 "Reserved" 99 "Reserved" 98 "Reserved" 97 "Reserved" 96 "Reserved" 95 "Reserved" 94 "Reserved" 93 "Reserved" 92 "Reserved" 91 "Reserved" 90 "Reserved" 89 "Reserved" 88 "Reserved" 87 "Reserved" 86 "Reserved" 85 "Reserved" 84 "Reserved" 83 "Reserved" 82 "Reserved" 81 "Reserved" 80 "Reserved" 79 "Reserved" 78 "Fire Suppression System" 77 "Fuel Properties Sensor" 76 "Temperature Sensor" 75 "Supplemental Fan" 74 "Lubrication System" 73 "Rollover Detection Control" 72 "Coolant Valve Controller" 71 "Transfer Case Control" 70 "Auxiliary Regeneration Device" 69 "Engine Emission Aftertreatement System" 68 "Aftertreatment system gas measurement" 67 "Electrical System Controller" 66 "I/O Controller" 65 "Gas Flow Measurement" 64 "Endurance Braking" 63 "Engine Valve Controller" 62 "On-Board Diagnostic Unit" 61 "File Server/Printer" 60 "Cab Display" 59 "Starter" 58 "Fan Drive Control" 57 "Steering Column Unit" 56 "Communications Unit, Radio" 55 "Communications Unit, Satellite" 54 "Communications Unit, Cellular" 53 "Alternator/Charging System" 52 "Chassis Controller" 51 "Forward-Looking Collision Warning System" 50 "Auxiliary Heater" 49 "Clutch/Converter Control" 48 "Ramp Control" 47 "Information System Controller" 46 "Oil Sensor Unit" 45 "Vehicle Dynamic Stability Control" 44 "Exhaust Emission Control" 43 "Transmission Display" ;
VAL_ 2566786302 ManufacturerCode 139 "Caterpillar Trimble Control Technologies (CTCT), LLC" 138 "Georg Fritzmeier GmbH & Co. KG" 137 "Maretron" 136 "Komatsu Ltd" 135 "Airmar Technology Corporation" 134 "Iris Technology Ltd" 133 "Bucher Schoerling GmbH" 132 "Mulag-Fahrzeugwerk" 131 "ITT Industries" 130 "Nido - Universal Machines B.V." 129 "OMNEX Control Systems Inc." 128 "Gerhard Duecker GmbH & Co. KG" 1863 "Thomas G. Faria Co." 1862 "Sanshin" 1861 "Vector North America (formerly Vector Cantech)" 1860 "MMP" 1859 "Kvasar AB" 1858 "Litton" 1857 "Simrad" 1856 "Trimble" 1855 "Furuno USA" 1854 "Northstar Technologies" 1853 "Japan Radio Co" 1852 "Navionics" 1851 "RayMarine" 1850 "Seastar Solutions (formerly Teleflex)" 896 "NextFour Solutions Ltd" 895 "Peloton Technology" 894 "Rhodan Marine Systems of Florida LLC" 893 "KlinkTechnics Ltd." 892 "Mectronx Corp" 891 "CarrierWeb" 890 "L3 Technologies, Inc." 889 "SANY America Inc" 888 "Carma Systems Inc" 887 "Hyperdrive Innovation Limited" 886 "Hitachi Zosen Corporation" 885 "SICK Stegmann GmbH" 884 "Sure Grip Controls Inc." 883 "Swift Navigation, Inc." 882 "BHTronik GmbH & Co. KG" 881 "Sovema" 880 "Revision Military" 879 "PG쟕rionic,쟅nc." 878 "FOTON" 877 "SICK ATech GmbH" 876 "SUCO Robert Scheuffele GmbH & Co. KG" 875 "Salvarani S.r.l." 874 "MTA S.p.A." 873 "Garnet Instruments Ltd." 872 "K�hlig Antriebstechnik GmbH" 871 "Superior Tech Inc" 870 "Textron Fleet Management" 869 "Intercomp" 868 "Data Panel Corp" 867 "Skeleton Technologies" 866 "Netradyne, Inc." 865 "MyEasyFarm" 864 "Streamline Transportation Technologies Inc." 863 "SMAG" 862 "Prospec Electronics" 861 "Adel System S.r.l." 860 "Michelin" 859 "Valor" 858 "Littelfuse" 857 "Zoomlion Heavy Industry NA, Inc" 856 "FarmFacts GmbH" 855 "Toshiba Infrastructure Systems & Solutions Corporation" 854 "GEMAC Chemnitz GmbH" 853 "Teledyne RESON BV" 852 "Velvac Inc" 851 "Novotechnik Messwertaufnehmer OHG" 850 "Geoprospectors GmbH" 849 "MTS Maschinentechnik Schrode AG" 848 "ningupex" 847 "Oceanvolt" 846 "L3 Magnet-Motor" 845 "GMB G�strower Maschinenbau GmbH" 844 "FELL AS" 843 "Hendrickson Truck Commercial Vehicle Systems" 842 "DigiDevice Srl" 841 "Agra-GPS" 840 "E.S.T.E. srl" 839 "Indexator Rotator Systems AB" 838 "Teamsurv Ltd" 837 "Famic Technologies Inc." 836 "Signature4" 835 "PetTrack Ltd." 834 "Pioneer Microsystems, Inc." 833 "Electrum Automation AB" 832 "Heizomat Ger�tebau-Energiesysteme GmbH" 831 "DOK-ING Ltd." 830 "Ultra Motion LLC" 829 "Drov Technologies, Inc." 828 "AgriBrink Inc." 827 "INmatix Technology Group Ltd" 826 "Lewmar Marine Inc" 825 "BPW Hung�ria" 824 "Undheim Systems AS" 823 "ACEINNA, Inc (formerly MEMSIC, Inc)" 822 "Bren-Tronics, Inc." 821 "Thorsen Teknik A/S" 820 "DIaLOGIKa Gesellschaft fuer angewandte Informatik mbH" 819 "Preco Electronics" 818 "HGNSS" 817 "TE Connectivity Sensor Solutions" 816 "UniStrong" 815 "FLIR Systems, Inc." 814 "Soltec Soluzioni Tecnologiche Srl" 813 "Thales Suisse SA" 812 "Torch Technologies" 811 "Blue Water Desalination" 810 "Dutch Power Company" 809 "HMS Industrial Networks AB" 808 "RIMEX Supply Ltd." 807 "Schneider-Electric" 806 "Charge Automotive Ltd" 805 "Gundersen & L�ken AS" 804 "ASA Electronics" 803 "Gill Sensors & Controls Limited" 802 "SPBI (Bj Technologie)" 801 "LOR Manufacturing Company Inc." 800 "Delta-Q Technologies" 799 "Stillwater Designs and Audio, Inc. - KICKER" 798 "Lumishore Ltd" 797 "Tides Marine" 796 "Canadian Automotive Industries Ltd" 795 "Broyda Enterprises Pty Ltd" 794 "Shihlin Electric & Engineering Corporation" 793 "James Fisher Prolec" 792 "Kostal Mexicana" 791 "AUTEC" 790 "VACALL" 789 "GRADALL" 788 "MoTeC Pty Ltd" 787 "Abertax Technologies Limited" 786 "Johnson Matthey Battery Systems" 785 "Fischer Panda GmbH" 784 "CM Automotive Systems, Inc." 783 "Loup Electronics Inc." 782 "AVR bvba" 781 "Poly-Planar LLC" 780 "AVID Technology Ltd" 779 "RLC Electronic Systems" 778 "Seakeeper Inc." 777 "Ocean Signal Ltd" 776 "HMI Systems LLC" 775 "ZIEHL-ABEGG Automotive GmbH" 774 "Taisho Corporation" 773 "Clarion Corporation of America" 772 "Blink Marine" 771 "Shaw Development, LLC" 770 "MONOSEM" 769 "Trombetta" 768 "Flores Automation, LLC" 767 "Alliance Wireless Technologies Inc." 766 "Epec Oy" 765 "GIGAVAC" 764 "Bednar FMT s.r.o." 763 "AT-Systems BVBA" 762 "ROJ s.r.l." 761 "MITA OLEODINAMICA S.p.A." 760 "Bernecker + Rainer Industrie Elektronik GmbH" 759 "Hydro-Gear" 758 "Banner Engineering Corp." 757 "IMPCO Technologies" 756 "Maschio Gaspardo S.P.A." 755 "Firefly Integrations" 754 "Parker Hannifin Corp., Automation Group" 753 "AIROD Technologies" 752 "Deep Sea Electronics Plc" 751 "Pacific Track" 750 "Joskin SA" 749 "Chart Inc." 748 "ISOTTA" 747 "Agratronix" 746 "SureFire Ag Systems, Inc." 745 "Cidra Corporate Services Inc." 744 "Woosung Engineering Co., Ltd." 743 "Daemyung Elevator Co., Ltd." 742 "EROAD" 741 "Carling Technologies" 740 "e-Traction" 739 "LXNAV d.o.o." 738 "Blue Ink Technologies" 737 "Balluff GmbH" 736 "Terex Aerial Work Platforms - Genie" 735 "AEM Performance Electronics" 734 "REAPsystems" 733 "Intendia S.L." 732 "Gefran S.p.A." 731 "Modine Manufacturing Company" 730 "BERTHOUD AGRICOLE" 729 "Liebherr" 728 "Streumaster / Panien" 727 "Dhoot Transmission Pvt Ltd." 726 "MIDORI PRECISIONS" 725 "Hitachi Construction Machinery Co., Ltd." 724 "Electronic Applications, Inc." 723 "Jabil Inc." 722 "Contelec AG" 721 "Hypro" 720 "WITZ Corporation" 719 "Cojali S. L." 718 "Micronet Inc" 717 "Yacht Devices Ltd" 716 "Eaton Control & Power Conversion Division (CPCD)" 715 "Autonnic Research Ltd" 714 "Kobashi Kogyo Co., Ltd." 713 "US Hybrid Corporation" 712 "LOR Manufacturing Company Inc." 711 "DAS Co., LTD" 710 "Greentronics Ltd." 709 "Marquardt GmbH" 708 "Lars Thrane A/S" 707 "Rochester Gauges Inc" 706 "Shanghai Diesel Engine Corporation Limited" 705 "SVAB Hydraulik AB" 704 "JL Audio, Inc." 703 "Hydro Tab Marine Engineering" 702 "Weichai Power Co., Ltd." 701 "BigRoad Inc." 700 "K-Tec Earthmovers Inc." 651 "Takakita Co, Ltd." 650 "Seiko Epson Corp." 649 "Control-Q BV" 648 "OJSC Ekran" 647 "Siloking" 646 "Veenhuis Machines BV" 645 "esd electronic system design gmbh" 644 "KUS USA" 643 "Bogballe A/S" 642 "Moog / Aspen Motion Technologies" 641 "Diverse Yacht Services" 640 "Power Solutions International" 639 "Startec s.r.l." 638 "KVH Industries, Inc." 637 "Bavaria Yachtbau GmbH" 636 "Divelbiss Corporation" 635 "Argo Tractors S.p.A." 634 "Rocky Research" 633 "TORC Robotics" 632 "Pepperl+Fuchs GmbH" 631 "Reltima" 630 "SmartDrive Systems Inc." 629 "Agri Info Design, Ltd." 628 "Falck Schmidt Defence Systems" 627 "Radio Ocean" 626 "AVL DiTEST GmbH" 625 "Global MRV Inc." 624 "Blackbox Machine Control Pty Ltd" 623 "Xirgo Technologies" 622 "Floyd Bell Inc" 621 "Hagie Manufacturing Company" 620 "Sevcon Ltd." 619 "Right Weigh Load Scales" 618 "Evrard SA" 617 "Zero Emission Vehicles" 616 "SMART-TEC s.r.o." 615 "Networkfleet, Verizon Telematics" 614 "ARLT Technologies GmbH" 613 "HKS Co., Ltd." 612 "Samwon IT" 611 "Esterline" 610 "Trail Tech" 609 "Walvoil S.p.A." 608 "Gale Banks Engineering" 607 "Knappco/Civacon" 606 "Intellian Technologies" 605 "Aventics GmbH" 604 "Indexator Rototilt Systems AB" 603 "Kereval" 602 "Nomad Digital Ltd." 601 "Navitas Systems" 600 "Aquatic AV" 599 "Spudnik Equipment Co, LLC" 598 "ABB Turbo Systems Ltd" 597 "Hydac Filter Systems GmbH" 699 "Harman International Industries" 698 "Scorpion Technologies Ltd." 697 "흈� AB" 696 "DRS Network & Imaging Systems, LLC (DRS Technologies)" 695 "Weldon Technologies" 694 "GasTOPS Ltd." 693 "Agility Fuel Solutions (formerly Agility Fuel Systems)" 692 "Tanhay Corporation" 691 "Digitroll Agricultural Electronics" 690 "LINAK A/S" 689 "Aarcomm Systems Inc" 688 "Rockford Corp" 687 "Flight Systems, Inc." 686 "Taigene Electric Machinery Corp." 685 "ANEDO Ltd." 684 "KEB" 683 "Fosen Elektro" 682 "Eckelmann AG" 681 "BEDIA Motorentechnik GmbH & Co. KG" 680 "AMVAC Chemical Corporation" 679 "Cimco Marine AB" 678 "KeepTruckin, Inc." 677 "DSA Daten- und Systemtechnik GmbH" 676 "Danfoss IXA A/S" 675 "Kawasaki Motors Corp., USA" 674 "Yara International ASA" 673 "Caruelle Nicolas" 672 "OPTIMA Concept" 671 "Innovative Controls Inc." 670 "STEMCO LP" 669 "Quantum Fuel Systems Technologies Worldwide, Inc" 668 "MacDon Industries Ltd." 667 "Bartec" 666 "Schaeffler Technologies AG & Co., KG" 665 "Gebr. Bode GmbH & Co. KG" 664 "Level Developments Ltd" 663 "Delta Systems, Inc" 662 "Kissling Elektrotechnik GmbH" 661 "SPAL Automotive S.r.l." 660 "Auto-Gaz Centrum" 659 "Data Panel Corp." 658 "Shenzhen Jiuzhou Himunication Technology Co., Ltd" 657 "Terzo Power Systems" 656 "PRO SOLUS do Brasil" 655 "Genge & Thoma AG" 654 "Kohler Power Systems, Detroit Engine Development Center (DEDC)" 653 "AEV, spol. s r. o." 652 "MicroControl GmbH & Co. KG" 596 "Brunelco Electronic Innovators B.V." 595 "CustomWare" 594 "Kongsberg Automotive" 593 "Sensata Technologies" 592 "tecsis GmbH" 591 "United States Coast Guard" 590 "ARGO-HYTOS GMBH" 589 "MICO, Inc." 588 "Vignal Systems" 587 "JCA Electronics" 586 "Suzuki Motor Corp" 585 "Industrial Electronic Controls" 584 "CarMedialab GmbH" 583 "Yachtcontrol" 582 "Innovative Software Engineering" 581 "V�derstad - Verken AB" 580 "San Jose Technology, Inc." 579 "KVH Industries, Inc." 578 "advanSea" 577 "Denchi Power Ltd  (formerly ABSL Power Solutions Limited)" 576 "Vectia" 575 "Lytx" 574 "Vishay Precision Group" 573 "Orolia Ltd" 572 "Fasse Valves" 571 "Marinecraft Co., Ltd." 570 "frenzel + berg electronic GmbH & Co. KG" 569 "LORD MicroStrain Sensing Systems" 568 "Makersan Ltd. Co." 567 "Lithiumstart LLC" 566 "Geode Technology, Inc." 565 "Micro-Trak Systems, Inc." 564 "Auto Power Electronic" 563 "LOHR Sistemas Eletronicos LTDA" 562 "Bombardier Transportation GmbH" 561 "b-plus GmbH" 560 "Iowa State University, Agricultural and Biosystems Engineering" 559 "Four Peaks Navigation" 558 "Davis Instruments Corp." 557 "Rockson Automation GmbH" 556 "Doosan Infracore Norway" 555 "Sasaki Corporation" 554 "iris-GmbH infrared & intelligent sensors" 553 "KIB Electronics" 552 "Matsuyama Plow Mfg Co, Ltd" 551 "Wexler CSD Ltd." 550 "SUN-A Corporation" 549 "ROAD Deutschland GmbH" 548 "TM4 Inc." 547 "Thomson Linear LLC" 546 "Maruyama Mfg Co, Inc." 545 "GS Hydraulics" 544 "Au Group Electronics" 543 "BAUER Maschinen GmbH" 542 "Dinamica Generale s.p.a." 541 "Total Fire Systems, Inc." 540 "Dinex A/S" 539 "Mobileview" 538 "Crop Ventures, Inc." 537 "Schrader Electronics Ltd." 536 "SSI Technologies" 535 "MOTORPAL, a.s." 534 "Webasto Thermo & Comfort SE" 533 "Doran Manufacturing, LLC" 532 "Onwa Marine Electronics Co Ltd." 531 "Genge & Thoma AG" 530 "NMEA" 529 "National Instruments Korea" 528 "Hoganas AB, Electric Drive Systems" 527 "GKN Walterscheid GmbH" 526 "LOFA Industries, Inc" 525 "Rust Sales INC" 524 "Vomax Instrumentation Pty. Ltd." 523 "Reggio Emilia Innovazione" 522 "Nebraska Tractor Test Laboratory" 521 "Clever Devices Ltd." 520 "Trapeze" 519 "Peeters Landbouwmachines b.v." 518 "Transas USA Inc." 517 "Noland Engineering" 516 "AVAT Automation GmbH" 515 "GINAF Trucks Nederland B.V." 514 "DISTek Integration, Inc." 513 "FarmscanAg" 512 "Inpower LLC" 511 "Sulky" 510 "Marinesoft Co. Ltd" 509 "MOTORTECH GmbH" 508 "Transtech Innovations" 507 "ISOBUS Test Center" 506 "IHI STAR Machinery Corporation" 505 "Yetter Farm Equipment" 504 "Vesper Marine" 503 "Naviop S.R.L." 502 "Attwood Corporation" 501 "Agrotronix S.A." 500 "Oxbo International Corporation" 499 "LCJ Capteurs" 498 "Innovative Design Solutions, Inc." 497 "SENTRON Sistemas Embarcados" 496 "W. Gessmann GmbH" 495 "HOLMER Maschinenbau GmbH" 388 "Innomatix, LLC" 387 "Orscheln Products, LLC" 386 "JLG Automation BVBA" 385 "Johnson Outdoor Marine Electronics" 384 "Camano Light" 383 "MCL Industries" 382 "National Agriculture and Food Research Organization" 381 "B & G" 380 "Suntech International Ltd." 379 "Yamabiko Corporation" 378 "Glendinning Marine Products" 377 "ifm electronic gmbh" 376 "Quake Global" 375 "Williams Controls Inc." 374 "Northern Lights, Inc." 373 "Electronic Design Inc." 372 "Delphi" 371 "Heinzmann GmbH & Co. KG" 370 "Rolls-Royce Marine AS" 369 "Power Torque Engineering Ltd" 368 "HANSENHOF_electronic" 367 "Fliegl Agrartechnik" 366 "Viewnyx Corp." 365 "Digi-Star, LLC" 364 "OEM Controls Inc." 363 "BEI Duncan" 362 "Poettinger Landtechnik GmbH (formerly Alois Poettinger Maschinenfabrik GmbH)" 361 "InMach" 360 "HJS Emission Technology GmbH & Co KG   (formerly HJS Fahrzeugtechnik GmbH & Co KG)" 359 "Ludwig Bergmann GmbH" 358 "Victron Energy BV" 357 "Hardi International A/S" 356 "Fischer Panda Generators, Inc" 355 "Mastervolt International B.V." 354 "Junkkari OY" 353 "Hegemon Electronics, Inc." 352 "SAME DEUTZ-FAHR GROUP S.p.A." 351 "Thrane & Thrane" 350 "Noris Marine Systems GmbH & Co KG" 349 "Suonentieto" 348 "Amazonen Werke H. Dreyer" 347 "Honeywell" 346 "Control Solutions" 345 "Korean Maritime University" 344 "Parvus Corporation" 343 "Baumer Group" 342 "THOMAS MAGNETE GmbH" 341 "Boning GmbH & Co" 340 "Continental AG" 234 "Mondial electronic GmbH" 233 "Yacht Monitoring Solutions Inc." 232 "TSD Integrated Controls" 231 "Topcon Positioning Systems, Inc." 230 "Saucon Technologies" 229 "Garmin International Inc." 228 "Unused (formerly ZF Marine Electronics)" 227 "Lykketronic A/S" 226 "Monaco Coach Corporation" 225 "SKF" 224 "EMMI Network, S.L." 223 "Vaueo Retarder Co., Ltd." 222 "Generac Power Systems, Inc." 221 "SiE" 220 "Beede Electrical Instrument Company, Inc" 219 "Cat OEM Solutions" 218 "Gits Manufacturing Company" 217 "RM Michaelides Software & Elektronik GmbH" 216 "Paneltronics Inc." 215 "Aetna Engineering/Fireboy-Xintex" 214 "MC elettronica Srl" 213 "CNH Belgium N.V." 212 "Sure Power Industries, Inc" 211 "DNA Group" 210 "Iteris, Inc." 209 "Bell Equip. Co. SA (PTY) LTD" 208 "Drew Technologies, Inc" 207 "Otto Engineering" 206 "port GmbH" 205 "SmarTire Systems Inc" 204 "The Morey Corporation" 203 "MILtronik GmbH" 202 "Curtis Instruments, Inc" 201 "Disenos y Tecnologia S.A." 200 "MGM Brakes" 199 "ACTIA Group (formerly Actia Corp)" 198 "Mystic Valley Communications" 197 "Mechron Power Systems" 196 "LEMKEN GmbH & Co KG" 195 "General Engine Products" 194 "TriMark Corporation" 193 "Jeppesen Marine" 192 "Floscan" 191 "XRS Corporation (formerly XATA Corporation)" 190 "Hella KGaA Hueck & Co" 189 "QUALCOMM" 188 "EMP Corp" 187 "Air-Weigh" 186 "Altronic, Inc" 185 "Beede Electrical Instrument Company" 494 "Synerject" 493 "Watcheye" 492 "Inergy Automotive Systems" 491 "Penny and Giles Ltd" 490 "QuikQ" 489 "Appareo Systems, LLC" 488 "The Charles Machine Works, Inc." 487 "DSE Test Solutions A/S" 486 "Westport Innovations Inc." 485 "MATT automotive" 484 "Headsight Inc." 483 "Valeo" 482 "Tricon Electronics" 481 "Chetco Digital Instruments" 480 "EnerDel, Inc." 479 "Vapor Bus International" 478 "OceanSat BV" 477 "OilQuick AB" 476 "Hummingbird Marine Electronics" 475 "GME" 474 "Persen Technologies Inc." 473 "Boss Industries, Inc." 472 "Tenneco Inc." 471 "Sea Cross Marine AB" 470 "SI-TEX Marine Electronics" 469 "RA Consulting GmbH" 468 "Tyco Fire Protection Products" 467 "Lely Industries N.V." 466 "Veethree Electronics and Marine LLC" 465 "Ashcroft Inc" 464 "Leach International Corporation" 463 "PROBOTIQ" 462 "IHI Shibaura Machinery Corporation" 461 "HAWE Hydraulik SE" 460 "San Giorgio S.E.I.N." 459 "Alltek Marine Electronics Corp" 458 "Control Solutions, Inc." 457 "RUSELPROM-ElectricDrive Ltd" 456 "General Kinetics" 455 "ADZ NAGANO GmbH" 454 "NGK Spark Plug Co. Ltd" 453 "Cooper Bussmann" 452 "WIKA Alexander Wiegand SE & Co. KG" 451 "Parker Hannifin Corp" 450 "Dycor Technologies Ltd." 449 "Polaris Industries Inc" 448 "Stanadyne Corporation, Electronics Systems" 447 "Great Plains Mfg." 446 "CertTech, L.L.C." 445 "KAT MECHATRONIC, Electronic Product Division" 444 "ITT Power Solutions" 443 "SignalQuest, Inc." 442 "Horsch Maschinen GmbH" 441 "PTG Reifendruckregelsysteme GmbH" 440 "Cummins Power Generation" 439 "Hyundai Heavy Industries" 438 "Comar Systems Ltd" 437 "Digital Yacht Limited" 436 "Kinze Manufacturing" 435 "Zunhammer GmbH" 434 "Stored Energy Systems" 433 "Rowe Electronics" 432 "S&A Systems, Inc." 431 "Tohatsu Corporation" 430 "Auteq Telematica S.A." 429 "Rota Engineering Ltd." 425 "Methode Electronics Inc, MDI" 424 "Odyne LLC" 423 "BSM Wireless, Inc." 422 "True Heading AB" 421 "Vertex Standard Co, Ltd" 420 "Vermeer Corporation, ACS Group" 419 "Fusion Electronics Ltd" 418 "Intellistick Inc" 417 "KZValve" 416 "Kubota Corporation" 415 "Valid Manufacturing Ltd." 414 "Cattron Group International" 413 "Datapross Nijbroek bv" 412 "WebTech Wireless Inc." 411 "Hy-Drive Technologies Ltd." 410 "COBO S.p.A. Divisione 3B6" 409 "Transfluid S.r.L." 408 "Corvus Energy Ltd." 407 "Comtech Mobile Datacom" 406 "Vecima Networks Inc." 405 "Wema System AS" 404 "Com Nav Marine Ltd" 403 "Trackwell ADS, Inc." 402 "Simma Software, Inc." 401 "Torqeedo GmbH" 400 "Livorsi Marine" 399 "ISEKI & Co., Ltd." 398 "Hilite International" 397 "Sanyo-kiki Co Ltd." 396 "Beyond Measure" 395 "GENTEC S.R.L." 394 "Capi 2 Nederland BV" 393 "Harvest Tec, Inc" 392 "Tianyuan Technology Co Ltd." 391 "Electronic Design for Industry, Inc" 390 "Partech Inc." 389 "Benchmark Electronics, Minnesota Division" 339 "Competence Center ISOBUS e.V." 338 "GRAF-SYTECO" 337 "Carraro S.p.A." 336 "APE s.r.o." 335 "Evo Electric Ltd" 334 "Takata-Petri AG" 333 "Hadley Products Corporation" 332 "HWH Corporation" 331 "Horton, Inc." 330 "Kidde Aerospace and Defense" 329 "Deif A/S" 328 "Qwerty Electronik AB" 327 "Sonceboz SA" 326 "Akron Brass Company" 325 "ASM Automation Sensorik Messtechnik GmbH" 324 "Snap-on Diagnostics" 323 "Mobileye Vision Technologies Ltd." 322 "MICHENKA s.r.o." 321 "Ultra Electronics, Electrics" 320 "Miedema Landbouwwerktuigenfabriek B.V." 319 "Cadec Global" 318 "SAT Plan" 317 "Navtronics Bvba" 316 "ITT Flow Control" 315 "Icom Incorporated" 314 "CSM GmbH" 313 "Ilmor Engineering, Inc." 312 "Lectronix, Inc." 311 "Patrick Power Products" 310 "TECNORD srl" 309 "Krauss-Maffei Wegmann GmbH & Co. KG" 308 "Cyntrx" 307 "MAS Technologies" 306 "Sleipner Motor AB" 305 "NovAtel Inc" 304 "EmpirBus AB" 303 "CTS Corporation" 302 "Nissin Kogyo Co., LTD" 301 "Parker Hannifin (UK) Ltd FDE group" 300 "Systron Donner Automotive" 299 "Rauch" 298 "Holley Performance" 297 "Zonar Systems Inc" 296 "micro dynamics GmbH" 295 "BEP Marine" 294 "Grayhill Inc." 293 "Spyder Controls Corp." 292 "IKUSI - Angel Iglesias S.A." 291 "Groeneveld Transport Efficiency BV" 290 "Kuebler GmbH" 289 "Watlow" 288 "Mitsubishi FUSO Truck & Bus Corp." 287 "NTech Industries, Inc" 286 "Coelmo srl" 285 "Sea Recovery Corp" 284 "Mobile Tech Chile" 283 "CWF Hamilton & Co Ltd" 282 "Medallion Instrumentation Systems" 281 "Precision Governors LLC" 280 "Leica Geosystems Pty Ltd" 279 "Geometris LP" 278 "Takata Electronics" 277 "LHP Telematics" 276 "Aqua-Hot Heating Systems" 275 "Navico Egersund AS" 274 "LTW Technology Co., LTD" 273 "Active Research Limited" 272 "Gross Mechanical Laboratories, Inc" 271 "Cole Hersee" 270 "Tennant" 269 "Saft America Inc.,  Space & Defense Division" 268 "Accurate Technologies" 267 "Red Lion Controls, Inc" 266 "International Thermal Research Ltd" 265 "MTS Sensor Technologie GmbH" 264 "Autolync" 263 "IMMI" 262 "HydraForce, Inc" 261 "Red Dot Corporation" 260 "Reichhardt GmbH Steuerungstechnik" 259 "Jetter AG" 258 "ARAG" 257 "Honda Motor Co., Ltd" 256 "Tyco Electronics AMP" 255 "MEAS France" 254 "GE Sensing" 253 "Mobile Control Systems" 252 "Sensor-Technik Wiedemann GmbH" 251 "German Agricultural Society, Test Center (DLG)" 250 "Kuhn Group" 249 "Schaltbau GmbH" 248 "Cooper Standard Automotive Active Systems Group" 247 "ePULSE" 246 "Class 1, Inc" 245 "Capstan Ag Systems, Inc." 244 "Techno-Matic" 243 "eRide, Inc." 242 "Kokusandenki Co. Ltd" 241 "Schneider Automation SAS" 240 "Vanair Mfg" 239 "May & Scofield Ltd" 238 "ZF Friedrichshafen AG" 237 "Agtron Enterprises Inc" 236 "NORAC Systems International Inc" 235 "SailorMade Marine Telemetry - Tetra Technology Ltd." 184 "EIA Electronics" 183 "KDS Controls, Inc" 182 "Vehicle Systems Engineering B.V." 181 "Coretronics, Inc." 180 "Smart Power Systems" 179 "TeeJet Technologies Springfield (formerly Midwest Technologies Illinois, LLC)" 178 "Continental Automotive GmbH (formerly Siemens VDO Automotive AG)" 177 "Diagnostic Systems Associates" 176 "Moritz Aerospace" 175 "Veris Technologies, Inc." 174 "AB Volvo Penta" 173 "Ryeso, Inc." 172 "Yanmar Co., Ltd. (formerly Yanmar Marine USA)" 171 "Wachendorff Elektronik GmbH & Co. KG" 170 "Computronics Corporation Ltd." 169 "Marlin Technologies Inc." 168 "Xantrex" 167 "JLG Industries Inc" 166 "John Deere Electronic Solutions (formerly Phoenix International)" 165 "CPAC Systems AB" 164 "MTU Friedrichshafen GmbH (formerly DaimlerChrysler Off-Highway)" 163 "BRP Inc." 162 "Axiomatic Technologies" 161 "Offshore Systems (UK) Ltd" 160 "Nido" 159 "NTech Industries Inc" 158 "Firestone Industrial Products Company" 157 "ISSPRO Inc." 156 "ITT Industries - Cannon" 155 "Vetronix Corporation" 154 "Westerbeke Corporation" 153 "Woodward, Industrial Controls Division" 152 "elobau GmbH & Co. KG" 151 "Raven Industries, Inc." 150 "Fleetguard" 149 "Holset" 148 "Blue Water Data, Inc." 147 "Nautibus electronic GmbH" 146 "Maxima Technologies" 145 "MurCal Controls" 144 "Mercury Marine" 143 "W. Gmeiner GmbH & Co." 142 "TRW Automotive (Commercial Steering Systems)" 141 "Thales Navigation Ltd." 140 "Lowrance Electronics, Inc." 127 "Holland USA" 126 "Driver Tech" 125 "Nevada Automotive Test Center" 124 "Hydac Electronic" 123 "Basler Electric" 122 "FG Wilson (Engineering) Limited" 121 "HED (Hydro Electronic Devices, Inc.)" 120 "RDS Technology Ltd" 119 "IntegriNautics젨" 118 "Intron GmbH" 117 "HUSCO International" 116 "BEELINE Technologies" 115 "NACCO Materials Handling Group, Inc." 114 "EControls, Inc." 113 "Stress-Tek, Inc." 112 "MECALAC" 111 "Maschinenfabrik Bernard Krone GmbH" 110 "EPIQ Sensor-Nite" 109 "TeeJet Technologies Denmark (formerly LH Technologies ApS)" 108 "WTK-Elecktronik GmbH" 107 "Grimme Landmaschinen GmbH & Co. KG" 106 "BAE Systems Controls, Inc." 105 "Kiepe Elektrik GmbH & Co. KG" 104 "CLAAS KGaA mbH (formerly CLAAS Selbstfahrende Erntemaschinen GmbH)" 103 "CLAAS E-Systems KGaA mbH & Co. KG (formerly CLAAS Agrosystems GmbH & Co. KG)" 102 "AGCO (formerly AGCO GmbH & Co.)" 101 "Sensoria" 100 "VDO Technik AG" 99 "International Transmissions Ltd (ITL)" 98 "Mueller-Elektronik GmbH & Co" 97 "Ag Leader Technology, Inc." 96 "Mech@tronic IT GmbH" 95 "Pacific Insight Electronics Corp." 94 "CNH Industrial N.V. (formerly CNH Global N.V.)" 93 "Perkins Engines Company Ltd." 92 "Ag-Chem Equipment Co., Inc." 91 "BSG Bodensee Steuergeraete GmbH" 90 "Knorr-Bremse SfN GmbH" 89 "Kverneland Group, Electronics Division" 88 "Hemisphere GPS Inc (formerly Satloc Precision GPS)" 87 "J.C. Bamford Excavators Ltd (JCB)" 86 "C. E. Niehoff & Company" 85 "Kohler Co" 84 "New Holland UK Limited" 83 "Bendix VORAD Technologies (formerly Eaton VORAD Technologies)" 82 "Bobcat/Ingersoll-Rand (formerly Melroe/Ingersoll-Rand)" 81 "Fire Research Corp." 80 "Twin Disc, Inc." 79 "Daimler Benz AG - Engine Division (PBM)" 78 "Frank W. Murphy Manufacturing, Inc" 77 "Deere Power Systems Group" 76 "unused (formerly Deere & Co, Construction Division)" 75 "Deere & Co, Agricultural Division" 74 "Eaton Axle-Brake Division" 73 "LeTourneau, Inc." 72 "Sisu Corporation" 71 "Vansco Electronics Ltd." 70 "Flex-coil Limited" 69 "Trimble Navigation" 68 "Scania" 67 "John Deere Coffeyville Works (formerly Funk Manufacturing Company)" 66 "John Deere Construction Equipment Division" 65 "MAN Nutzfahrzeuge AG" 64 "Unused (formerly SpectraPrecision Laserplane, then SpectraPhysics)" 63 "ZF Industries Inc." 62 "Wabco" 61 "Volvo Truck Corp." 60 "Volvo Trucks North America Inc." 59 "VES Inc." 58 "SPX Corporation, OTC Div" 57 "Danfoss  (formerly Sauer Sundstrand Co, then Sauer-Danfoss Co)" 56 "SAIC" 55 "Ryder System Inc." 54 "Meritor Wabco" 53 "Continental Automotive Systems US, Inc. (formerly Rockwell Land Transportation)" 52 "Meritor Automotive, Inc. (formerly Rockwell Automotive)" 51 "Robert Bosch GmbH" 50 "Robert Bosch Corp" 49 "RE America Inc." 48 "Pollak Alphabet" 47 "Phillips Semiconductor" 46 "Noregon Systems, Inc  (formerly Parasoft Computing Solutions)" 45 "PACCAR" 44 "Nippondenso Co. Ltd." 43 "International Truck and Engine Corporation - Vehicle Electronics (formerly Navistar Intl Trans Corp.)" 42 "International Truck and Engine Corporation - Engine Electronics  (formerly Navistar Intl Trans Co., Engine Electronics)" 41 "Motorola Inc." 40 "Motorola AIEG Inc." 39 "Microfirm Inc." 38 "Micro Processor Systems Inc." 37 "Mack Trucks Inc." 36 "Lucas Ind." 35 "Kenworth Truck Co." 34 "Kelsey Hayes Co." 33 "John Deere" 32 "Jacobs Vehicle Systems" 31 "J Pollak Corp" 30 "Isuzu Motors Ltd" 29 "Hino Motors Ltd." 28 "Grote Ind. Inc." 27 "GMC" 26 "General Motors Corp, Service Technology Grp" 25 "Daimler Trucks North America LLC (formerly Freightliner LLC)" 24 "Ford Motor Co., Vehicle Controls" 23 "Ford Motor Co., Heavy Truck" 22 "Ford Motor Co., Electronic Concepts & Systems" 21 "Echlin Inc., Midland Brake Inc." 20 "Eaton Ltd" 19 "Eaton Corp. Trucking Info Services" 18 "Eaton Corp, Transmission Div." 17 "Eaton Corp, Corp Res & Dev" 16 "Eaton Corp" 15 "DICKEY-john Corporation" 14 "Detroit Diesel Corporation" 13 "Delco Electronics" 12 "Deere & Company, Precision Farming" 11 "Dearborn Group Inc." 10 "Cummins Inc (formerly Cummins Engine Co)" 9 "Chrysler Corp." 8 "Caterpillar Inc." 7 "Case Corp." 6 "Berifors Electronics AB" 5 "AMP Inc." 4 "Ametek-Dixson" 3 "Ametek, US Gauge Division" 2 "Allison Transmission, Inc." 1 "Bendix Commercial Vehicle Systems LLC (formerly Allied Signal Inc.)" 0 "Reserved" ;
VAL_ 2566847486 DrvlineRetarderOverheatIndicator 3 "Not available" 2 "Driveline Retarder Overheat Indicator is flashing" 1 "Driveline Retarder Overheat Indicator is on continuously" 0 "Driveline Retarder Overheat Indicator is off" ;
VAL_ 2631859966 SteerStraightAheadPosReset 3 "Not applicable" 2 "Reserved" 1 "Reset" 0 "Take no action" ;
VAL_ 2631859966 EngBuildHoursReset 3 "Take no action" 2 "Reserved" 1 "Reset" 0 "Do not reset" ;
VAL_ 2631859966 EngIgntCtrlMaintenanceHoursReset 3 "Take no action" 2 "Reserved" 1 "Reset" 0 "Do not reset" ;
VAL_ 2631859966 EngSprkPlgScndVltgeTrackingReset 3 "Take no action" 2 "Reserved" 1 "Reset" 0 "Do not reset" ;
VAL_ 2631859966 TripGroup2Proprietary 3 "Not applicable" 2 "Reserved" 1 "Reset" 0 "Take no action" ;
VAL_ 2631859966 TireSensorInformation 3 "Not applicable" 2 "Reserved" 1 "Reset" 0 "Take no action" ;
VAL_ 2631859966 TireConfigInformation 3 "Not Applicable" 2 "Reserved" 1 "Reset" 0 "Take No Action" ;
VAL_ 2631859966 BinLiftCountReset 3 "Take no action" 2 "Reserved" 1 "Reset" 0 "Do not reset" ;
VAL_ 2631859966 TripGroup1 3 "Not applicable" 2 "Reserved" 1 "Reset" 0 "Take no action" ;
VAL_ 2566840830 RetarderLocation 15 "Not available" 14 "Other" 5 "Trailer" 4 "(Secondary)    Driveline" 3 "(Secondary)    Transmission Output" 2 "(Primary)         Transmission Input" 1 "(Primary)         Engine Exhaust Brake" 0 "(Primary)        Engine Compression Release Brake or Engine Compression Release Brake Combined with Engine Exhaust Brake" ;
VAL_ 2566840830 RetarderType 15 "Not available" 14 "Other" 4 "Exhaust" 3 "Compression Release" 2 "Cooled Friction" 1 "Hydraulic" 0 "Electric/Magnetic" ;
VAL_ 2566844670 EngPTOGovDisSw 3 "Not Available" 2 "Error" 1 "On" 0 "Off" ;
VAL_ 2566844670 OprtrEngPTOGvrnrMmrySelectSwitch 3 "not available" 2 "error" 1 "PTO set speed memory 2 selected" 0 "PTO set speed memory 1 selected" ;
VAL_ 2566844670 EngRmtPTOGvrnrVrblSpedCtrlSwitch 3 "Not available" 2 "Error" 1 "On" 0 "Off" ;
VAL_ 2566844670 EngRmtPTOGvrnrPrprgrmmdSpdCtrlSw 3 "Not available" 2 "Error" 1 "On" 0 "Off" ;
VAL_ 2566844670 EngPTOGvrnrCast_DecelerateSwitch 3 "Not available" 2 "Error" 1 "On" 0 "Off" ;
VAL_ 2566844670 EngPTOGovernorSetSwitch 3 "Not available" 2 "Error" 1 "On" 0 "Off" ;
VAL_ 2566844670 EngPTOGovernorResumeSwitch 3 "Not available" 2 "Error" 1 "On" 0 "Off" ;
VAL_ 2566844670 EngPTOGovernorEnableSwitch 3 "Not available" 2 "Error" 1 "On" 0 "Off" ;
VAL_ 2566844670 EngPTOGovernorAccelerateSwitch 3 "Not available" 2 "Error" 1 "On" 0 "Off" ;
VAL_ 2566844670 RmtPTOGvrnrPrprgrmmdSpdCtrlSwtch 3 "Not Available" 2 "Error" 1 "On" 0 "Off" ;
VAL_ 2566844670 AuxInputIgnoreSwitch 3 "Not Available" 2 "Error" 1 "On" 0 "Off" ;
VAL_ 2566770174 RearWasherFunction 7 "Not available" 3 "High" 2 "Medium" 1 "Low" 0 "Off" ;
VAL_ 2566770174 FrontOperatorWasherSwitch 7 "Not available" 3 "High" 2 "Medium" 1 "Low" 0 "Off" ;
VAL_ 2566770174 FrontNonoperatorWasherSwitch 7 "Not available" 3 "High" 2 "Medium" 1 "Low" 0 "Off" ;
VAL_ 2566770174 RearWiperSwitch 15 "Not available" 6 "Mist" 5 "Delayed 2" 4 "Delayed 1" 3 "High" 2 "Medium" 1 "Low" 0 "Off" ;
VAL_ 2566770174 FrontOperatorWiperSwitch 15 "Not available" 6 "Mist" 5 "Delayed 2" 4 "Delayed 1" 3 "High" 2 "Medium" 1 "Low" 0 "Off" ;
VAL_ 2566770174 FrontNonoperatorWiperSwitch 15 "Not available" 6 "Mist" 5 "Delayed 2" 4 "Delayed 1" 3 "High" 2 "Medium" 1 "Low" 0 "Off" ;
VAL_ 2566769662 OperatingModeCmd 0 "Not presently requesting a specific Engine Operating Mode be used" 15 "Not available / Take no action" 14 "SAE Reserved" 13 "Engine Operating Mode 13 is requested" 12 "Engine Operating Mode 12 is requested" 11 "Engine Operating Mode 11 is requested" 10 "Engine Operating Mode 10 is requested" 9 "Engine Operating Mode 9 is requested" 8 "Engine Operating Mode 8 is requested" 7 "Engine Operating Mode 7 is requested" 6 "Engine Operating Mode 6 is requested" 5 "Engine Operating Mode 5 is requested" 4 "Engine Operating Mode 4 is requested" 3 "Engine Operating Mode 3 is requested" 2 "Engine Operating Mode 2 is requested" 1 "Engine Operating Mode 1 is requested" ;
VAL_ 2566769662 EngTorqueCurveSelectionCmd 15 "Not supported" 14 "SAE reserved" 2 "Indicates that Torque Curve 2 is selected" 1 "Indicates that Torque Curve 1 is selected" 0 "Indicates that this parameter is not presently requesting a different torque curve be used" ;
VAL_ 2566769662 EngAltDroopAuxInputSelect 15 "Not available" 14 "Error condition" 1 "thru 1101" 0 "Normal Droop Setting is selected" ;
VAL_ 2566769662 EngAltDroopRemoteAccelSelect 15 "Not available" 14 "Error condition" 1 "thru 1101" 0 "Normal Droop Setting is selected" ;
VAL_ 2566769662 EngAltDroopAccel2Select 15 "Not available" 14 "Error condition" 1 "thru 1101" 0 "Normal Droop Setting is selected" ;
VAL_ 2566769662 EngAltDroopAccel1Select 15 "Not available" 14 "Error condition" 1 "thru 1101" 0 "Normal Droop Setting is selected" ;
VAL_ 2566769662 EngAltRatingSelect 255 "Not available" 254 "Error condition." 3 "indicates that the Alternate Power Fueling 3 is selected" 2 "indicates that the Alternate Power Fueling 2 is selected" 1 "indicates that the Alternate Power Fueling 1 is selected" 0 "indicates that Maximum Power Fueling is selected" ;
VAL_ 2566769662 EngAltLowIdleSwitch 3 "Not available or Unused" 2 "Error" 1 "Alternate low idle point is selected" 0 "Default low idle point is selected" ;
VAL_ 2566769662 EngSynchronizationSwitch 3 "Not available or Unused" 2 "Error" 1 "Functionality is enabled" 0 "Functionality is disabled" ;
VAL_ 2566769662 EngAuxGovernorSwitch 3 "Not available" 2 "Error condition" 1 "Auxiliary Governor is enabled" 0 "Auxiliary Governor is disabled" ;
VAL_ 2566768638 OperatingModeSelection 15 "Not available" 14 "Error" 13 "Engine Operating Mode 13 is selected" 12 "Engine Operating Mode 12 is selected" 11 "Engine Operating Mode 11 is selected" 10 "Engine Operating Mode 10 is selected" 9 "Engine Operating Mode 9 is selected" 8 "Engine Operating Mode 8 is selected" 7 "Engine Operating Mode 7 is selected" 6 "Engine Operating Mode 6 is selected" 5 "Engine Operating Mode 5 is selected" 4 "Engine Operating Mode 4 is selected" 3 "Engine Operating Mode 3 is selected" 2 "Engine Operating Mode 2 is selected" 1 "Engine Operating Mode 1 is selected" 0 "Engine not operating in a specific Engine Operating Mode" ;
VAL_ 2566768638 EngTorqueCurveSelection 0 "Indicates that the engine is using a torque that is not presently selected by SPN 6796" 15 "Not supported" 14 "Error" 2 "Indicates that Torque Curve 2 is selected" 1 "Indicates that Torque Curve 1 is selected" ;
VAL_ 2566768638 EngAltDroopAuxInputSelectState 15 "Not available" 14 "SAE reserved" 1 "thru 1101" 0 "Control state is Normal Droop Setting" ;
VAL_ 2566768638 EngAltDropRemoteAccelSelectState 15 "Not available" 14 "SAE reserved" 1 "thru 1101" 0 "Control state is Normal Droop Setting" ;
VAL_ 2566768638 EngAltDroopAccel2SelectState 15 "Not available" 14 "SAE reserved" 1 "thru 1101" 0 "Control's state is Normal Droop Setting" ;
VAL_ 2566768638 EngAltDroopAccel1SelectState 15 "Not available" 14 "SAE reserved" 1 "thru 1101" 0 "Control state is Normal Droop Setting" ;
VAL_ 2566768638 EngAltRatingSelectState 255 "Not available" 254 "SAE reserved" 3 "Control state is Alternate Power Fueling 3" 2 "Control state is Alternate Power Fueling 2" 1 "Control state is Alternate Power Fueling 1" 0 "Control state is Maximum Power Fueling" ;
VAL_ 2566768638 EngAltLowIdleSelectState 3 "not available" 2 "SAE reserved" 1 "Alternate idle state" 0 "Normal idle state" ;
VAL_ 2566768638 EngMultiUnitSyncState 3 "Not available" 2 "SAE reserved" 1 "Control State is Functionality enabled" 0 "Control State is Functionality disabled" ;
VAL_ 2566768638 EngAuxGovernorState 3 "Not available" 2 "SAE reserved" 1 "Control State is Auxiliary Governor enabled" 0 "Control State is Auxiliary Governor disabled" ;
VAL_ 2365443326 HighLowBeamSwitch 3 "Not available" 2 "Error" 1 "High Beam Selected" 0 "Low Beam Selected" ;
VAL_ 2365443326 HazardLightSwitch 3 "Not available" 2 "Error" 1 "Hazard Lamps to be Flashing" 0 "Hazard Lamps to be Off" ;
VAL_ 2365443326 TurnSignalSwitch 15 "Not available" 14 "Error" 2 "Right turn to be Flashing" 1 "Left Turn to be Flashing" 0 "No Turn being signaled" ;
VAL_ 2365443326 MainLightSwitch 15 "Not available" 14 "Error" 13 "Reserved" 12 "Reserved" 11 "Reserved" 10 "Reserved" 9 "Reserved" 8 "Delayed Off" 7 "Reserved" 6 "Reserved" 5 "Reserved" 4 "Automatic Lights" 3 "Headlight and Park On" 2 "Headlight On" 1 "Park On" 0 "Off" ;
VAL_ 2365443326 WorkLightSwitch 15 "Not available" 14 "Error" 4 "Work Light Combination #4 On" 3 "Work Light Combination #3 On" 2 "Work Light Combination #2 On" 1 "Work Light Combination #1 On" 0 "Off" ;
VAL_ 2566802686 BlackOutWorkLampSelect 3 "Not Supported" 2 "Reserved" 1 "On" 0 "Off" ;
VAL_ 2566802686 NightVisionIlluminatorSelect 3 "Not Supported" 2 "Reserved" 1 "On" 0 "Off" ;
VAL_ 2566802686 BlackOutBrake_StopLampSelect 3 "Not Supported" 2 "Reserved" 1 "On" 0 "Off" ;
VAL_ 2566802686 ConvoyDrivingLampSelect 3 "Not Supported" 2 "Reserved" 1 "On" 0 "Off" ;
VAL_ 2566802686 ConvoyLampSelect 3 "Not Supported" 2 "Reserved" 1 "On" 0 "Off" ;
VAL_ 2566802686 FrontBlackOutMarkerLampSelect 3 "Not Supported" 2 "Reserved" 1 "On" 0 "Off" ;
VAL_ 2566802686 RearBlackOutMarkerSelect 3 "Not Supported" 2 "Reserved" 1 "On" 0 "Off" ;
VAL_ 2566774014 EngMarineOperatingModeStatus 7 "Not available" 6 "Error" 3 "Propulsion Variable Speed Mode" 2 "Propulsion Constant Speed Mode" 1 "Electrical Power Generation" 0 "Maintenance Mode" ;
VAL_ 2566774014 SlowVesselModeStatus 3 "Take no action" 2 "Reserved" 1 "Slow vessel mode is ACTIVE." 0 "Slow vessel mode is OFF." ;
VAL_ 2566774014 TrollingModeStatus 3 "Take no action" 2 "Reserved" 1 "Trolling mode is active" 0 "Trolling mode is off" ;
VAL_ 2566774014 EngThrttlSynchrnzationModeStatus 15 "Take no action" 4 "Synchronized Master" 3 "Synchronized Starboard" 2 "Synchronized Port" 1 "Synchronized Center" 0 "Not Synchronized" ;
VAL_ 2432595710 DisplayDeadbands 15 "Not Available" 2 "Wide = +/- 24mm" 1 "Standard = +/- 12mm" 0 "Narrow = +/- 4.5mm" ;
VAL_ 2432595710 LEDPatternCtrl 15 "Not Available" 2 "7 Channel" 1 "Offset" 0 "5 Channel" ;
VAL_ 2432595710 LEDDisplayDeadbandCtrl 15 "Not Available or Not applicable" 4 "+/- 1 mm    " 3 "+/- 5  mm   " 2 "+/- 24 mm  " 1 "+/- 12 mm  " 0 "+/- 4.5 mm " ;
VAL_ 2432595710 LEDDisplayModeCtrl 15 "Not Available or Not Applicable" 2 "Center On-Grade Display Mode 2" 1 "Offset On-Grade Display Mode" 0 "Center On-Grade Display Mode 1" ;
VAL_ 2432595710 LEDDisplayData1 255 "Not Available" 254 "Error" 159 "No data" 149 "High Coarse" 148 "High Medium/Coarse" 147 "High Medium" 146 "High Medium/Fine" 145 "High Fine" 144 "On Grade" 132 "Low Fine" 131 "Low Medium/Fine" 130 "Low Medium" 129 "Low Medium/Coarse" 128 "Low Coarse" 32 "Low Coarse LED on" 16 "Low Fine LED on" 8 "On-grade LED on" 4 "High Fine LED on" 2 "High Coarse LED on" ;
VAL_ 2365486590 LaserReceiverType 4 "2.5 Meter Survey Receiver" 3 "2 Meter Survey Receiver" 2 "1 Meter Survey Receiver" 1 "Linear Laser Receiver" 0 "Reserved" ;
VAL_ 2365485566 LaserTracerInformation 32 "Curb" 16 "Stringline" 8 "Previous pass" 4 "Valid target" 2 "Laser is ready" 1 "Laser power is on" ;
VAL_ 2365485566 LEDDisplayData2 255 "Not Available" 254 "Error" 159 "No data" 149 "High Coarse" 148 "High Medium/Coarse" 147 "High Medium" 146 "High Medium/Fine" 145 "High Fine" 144 "On Grade" 132 "Low Fine" 131 "Low Medium/Fine" 130 "Low Medium" 129 "Low Medium/Coarse" 128 "Low Coarse" 64 "Right LED on" 32 "Left LED on" 16 "Down LED on" 8 "Up LED on" 4 "On-grade 밅� LED on" 2 "On-grade 밄� LED on" 1 "On-grade 밃� LED on" ;
VAL_ 2364542462 StElvtnSensor2ReferenceElevation 3 "Don't Care / Take No Action" 2 "Reserved" 1 "Set Reference Elevation" 0 "Do not Set Reference Elevation" ;
VAL_ 2364542462 StElvtnSensor1ReferenceElevation 3 "Don't Care / Take No Action" 2 "Reserved" 1 "Set Reference Elevation" 0 "Do not Set Reference Elevation" ;
VAL_ 2364542462 SdshftDsrdBldeOffsetOperatorCtrl 15 "Not Installed" 14 "Error Indicator" 3 "Automatic Operator Control Request" 2 "Manual Operator Control Request" 1 "Momentary Operator Control Request" 0 "No Operator Control Request" ;
VAL_ 2364542462 SdshiftBladeCtrlModeOperatorCtrl 15 "Not installed" 14 "Error Indicator" 2 "Decrement Operator Control Request" 1 "Increment Operator Control Request" 0 "No Operator Control Request" ;
VAL_ 2364542462 RghtDsredBladeOffsetOperatorCtrl 15 "Not installed" 14 "Error Indicator" 2 "Decrement Operator Control Request" 1 "Increment Operator Control Request" 0 "No Operator Control Request" ;
VAL_ 2364542462 LftDsiredBladeOffsetOperatorCtrl 15 "Not installed" 14 "Error Indicator" 2 "Decrement Operator Control Request" 1 "Increment Operator Control Request" 0 "No Operator Control Request" ;
VAL_ 2364542462 RightBladeCtrlModeOperatorCtrl 15 "Not Installed" 14 "Error Indicator" 3 "Automatic Operator Control Request" 2 "Manual Operator Control Request" 1 "Momentary Operator Control Request" 0 "No Change" ;
VAL_ 2364542462 LeftBladeCtrlModeOperatorCtrl 15 "Not Installed" 14 "Error Indicator" 3 "Automatic Operator Control Request" 2 "Manual Operator Control Request" 1 "Momentary Operator Control Request" 0 "No Change" ;
VAL_ 2364542462 BladeAutoModeCmd 15 "Not Supported" 14 "Error Indicator" 4 "Auto Not Allowed" 3 "Service Mode" 2 "Suspend Auto" 1 "Activity Allows Auto" 0 "Auto Allowed" ;
VAL_ 2364542462 DesiredGradeOffsetSwitch 15 "Not installed" 14 "Error Indicator" 2 "Decrement button pressed" 1 "Increment button pressed" 0 "No button pressed" ;
VAL_ 2364542462 BladeCtrlModeSwitch 15 "Not Installed" 14 "Error Indicator" 3 "Automatic button pressed" 2 "Manual button pressed" 1 "Mode button pressed" 0 "No button pressed" ;
VAL_ 2633883646 FrontWheelDriveActuatorStatus 3 "Not Available" 2 "Error" 1 "Front Wheel Drive Actuator engaged" 0 "Front Wheel Drive Actuator not engaged" ;
VAL_ 2633880062 FMSstandardRequestsSupported 3 "Don't care" 2 "Reserved" 1 "On request mode is supported" 0 "On request mode is not supported" ;
VAL_ 2633880062 FMSstandardDiagnosticsSupported 1 "Diagnostics Is Supported" 0 "Diagnostics Is Not Supported" 3 "Don't care" 2 "Reserved" ;
VAL_ 2566806526 ImagerStatus 15 "Not Available" 14 "Error" 13 "Reserved" 12 "Reserved" 11 "Reserved" 10 "Reserved" 9 "Reserved" 8 "Reserved" 7 "Reserved" 6 "Reserved" 5 "Imager view degraded but functional" 4 "Imager misaligned" 3 "Imager fully blocked / fully blind" 2 "Imager partially blocked / partially blind" 1 "Imager warming up / initializing" 0 "Imager fully operational" ;
VAL_ 2566806526 DepWarnSysSt 15 "Not available" 14 "Error" 5 "System is warning lane departure" 4 "Active warning suppressed by operator behavior" 3 "System is ready" 2 "System is deactivated by driver" 1 "System is temporarily not available" 0 "System is not ready" ;
VAL_ 2566806526 RightWheelLaneDepDist 255 "not available or not installed" 254 "error" 253 "reserved / not used" 252 "not reliable" 251 "not in range" ;
VAL_ 2566806526 DrverAlertnessWarningSystemState 7 "Not Available / Not Installed" 4 "System monitoring driver behavior" 3 "System available" 2 "System temporarily not available" 1 "Initializing" 0 "System installed but disabled" ;
VAL_ 2566806526 LnDpartureIndicationEnableStatus 1 "Lane Departure Indication enabled" 0 "Lane Departure indication disabled" 3 "Not Used" 2 "Reserved" ;
VAL_ 2566806526 LaneTrackingStatusLeftSide 3 "Don't care/Take no action" 2 "Reserved" 1 "Tracking Left side" 0 "Not Tracking Left side" ;
VAL_ 2566806526 LaneTrackingStatusRightSide 3 "Don't Care/take no action" 2 "Reserved" 1 "Tracking Right side" 0 "Not Tracking Right side" ;
VAL_ 2431649790 LeftSideLaneDepHapticWarnCmd 3 "Not available" 2 "Reserved" 1 "Active haptic warning on the left side" 0 "No haptic warning on the left side" ;
VAL_ 2431649790 RightSideLaneDepHapticWarnCmd 3 "Not available" 2 "Reserved" 1 "Active haptic warning on the right side" 0 "No haptic warning on the right side" ;
VAL_ 2431649790 LeftSideLaneDepAcstWarnCmd 3 "Not available" 2 "Reserved" 1 "Active acoustical warning on the left side" 0 "No acoustical warning on the left side" ;
VAL_ 2431649790 RightSideLaneDepAcstWarnCmd 3 "Not available" 2 "Reserved" 1 "Active acoustical warning on the right side" 0 "No acoustical warning on the right side" ;
VAL_ 2431649790 LeftSideLaneDepOpticalWarnCmd 3 "Not available" 2 "Reserved" 1 "Active optical warning on the left side" 0 "No optical warning on the left side" ;
VAL_ 2431649790 RightSideLaneDepOpticalWarnCmd 3 "Not available" 2 "Reserved" 1 "Active optical warning on the right side" 0 "No optical warning on the right side" ;
VAL_ 2431649790 LaneDepartureImminentLeftSide 3 "Not used" 2 "Reserved" 1 "Imminent" 0 "Not imminent" ;
VAL_ 2431649790 LaneDepartureImminentRightSide 3 "Not Used" 2 "Reserved" 1 "Imminent" 0 "Not imminent" ;
VAL_ 2431649790 LaneDepartureRight 3 "Take no action" 2 "Reserved" 1 "Middle of the vehicle departs the lane to the right side" 0 "Middle of the vehicle does not depart the lane to the right side" ;
VAL_ 2431649790 LaneDepartureLeft 3 "Take no action" 2 "Reserved" 1 "Middle of the vehicle departs the lane to the left side" 0 "Middle of the vehicle does not depart the lane to the left side" ;
VAL_ 2431649790 DriverAlertnessWarning 7 "Not Available" 3 "Level 3" 2 "Level 2" 1 "Level 1" 0 "No distracted driving condition detected" ;
VAL_ 2633929214 EngFuelLeakage2 3 "Not available" 2 "Error" 1 "leakage detected" 0 "no leakage detected" ;
VAL_ 2633929214 EngFuelLeakage1 3 "Not available" 2 "Error" 1 "leakage detected" 0 "no leakage detected" ;
VAL_ 2566831614 FanDriveState 15 "Not available" 14 "Other" 13 "Engine brake" 12 "Timer" 11 "A/C system" 10 "Transmission retarder" 9 "Manual control" 8 "Reverse Operation" 7 "Default Operation" 6 "Excessive hydraulic oil temperature" 5 "Excessive transmission oil temperature" 4 "Excessive engine coolant temperature" 3 "Excessive engine oil temperature" 2 "Excessive engine air temperature" 1 "Engine system-General" 0 "Fan off" ;
VAL_ 2566820094 EngTorqueLimitFeature 7 "Not available" 4 "Current torque rating" 3 "Previous torque rating" 2 "First torque rating" 1 "Highest torque rating" 0 "Reserved" ;
VAL_ 2566820094 TorqueLimitingFeatureStatus 3 "Not available" 2 "Error" 1 "Enabled" 0 "Disabled" ;
VAL_ 2566802174 ManualModeInd 3 "Not Available" 2 "Reserved" 1 "Transmission is in a Manual Mode" 0 "Transmission is not in a Manual Mode" ;
VAL_ 2566802174 TransAutoNeutralSt 5 "Reserved" 4 "Auto-Neutral request received,  shift to Auto-Neutral state is inhibited." 3 "Auto-Neutral request received,  shift to Auto-Neutral state has been achieved." 2 "Auto-Neutral request received,  shift to Auto-Neutral state is pending." 7 "Not Available" 6 "Error" 1 "No request received,  conditions are such that an Auto-Neutral request would NOT be honored." 0 "No request received,  conditions are such that an Auto-Neutral request would be honored." ;
VAL_ 2566802174 TransWarningIndicator 3 "Not available" 2 "Transmission Warning Indicator is flashing" 1 "Transmission Warning Indicator is on continuously" 0 "Transmission Warning Indicator is off" ;
VAL_ 2566802174 TrnsRverseGearShiftInhibitStatus 3 "Not Available" 2 "Error" 1 "Reverse gear shifts are currently inhibited" 0 "Reverse gear shifts are currently allowed" ;
VAL_ 2566802174 TransMode8Indicator 3 "Not available" 2 "Error" 1 "Transmission Mode 8 active" 0 "Transmission Mode 8 not active" ;
VAL_ 2566802174 TransMode7Indicator 3 "Not available" 2 "Error" 1 "Transmission Mode 7 active" 0 "Transmission Mode 7 not active" ;
VAL_ 2566802174 TransMode6Indicator 3 "Not available" 2 "Error" 1 "Transmission Mode 6 active" 0 "Transmission Mode 6 not active" ;
VAL_ 2566802174 TransMode5Indicator 3 "Not available" 2 "Error" 1 "Transmission Mode 5 active" 0 "Transmission Mode 5 not active" ;
VAL_ 2566802174 TransMode1Indicator 3 "Not available" 2 "Error" 1 "Transmission Mode 1 Active" 0 "Transmission Mode 1 not active" ;
VAL_ 2566802174 TransMode2Indicator 3 "Not available" 2 "Error" 1 "Transmission Mode 2 Active" 0 "Transmission Mode 2 not active" ;
VAL_ 2566802174 TransMode3Indicator 3 "Not available" 2 "Error" 1 "Transmission Mode 3 Active" 0 "Transmission Mode 3 not active" ;
VAL_ 2566802174 TransMode4Indicator 3 "Not available" 2 "Error" 1 "Transmission Mode 4 Active" 0 "Transmission Mode 4 not active" ;
VAL_ 2566802174 TransShiftInhibitIndicator 3 "Take no action" 2 "Active, flashing)" 1 "Active, on continuously)" 0 "Inactive" ;
VAL_ 2566802174 TransEngCrankEnable 3 "Not available" 2 "Error" 1 "Cranking enabled" 0 "Cranking disabled" ;
VAL_ 2566802174 ActiveShiftConsoleIndicator 3 "Not available" 2 "Reserved" 1 "Secondary shift console is active" 0 "Primary shift console is active" ;
VAL_ 2566802174 TransReadyForBrakeRelease 3 "Not available" 2 "Error" 1 "Transmission Ready for Brake Release" 0 "Transmission Not Ready for Brake Release" ;
VAL_ 2566802174 TrnsRqstedRangeDisplayFlashState 3 "Take no action" 2 "Reserved" 1 "Active" 0 "Inactive" ;
VAL_ 2566802174 TrnsRqstedRangeDisplayBlankState 3 "Take no action" 2 "Reserved" 1 "Active" 0 "Inactive" ;
VAL_ 2566802174 TransServiceIndicator 3 "Not available" 2 "Transmission Service Indicator is flashing" 1 "Transmission Service Indicator is on continuously" 0 "Transmission Service Indicator is off" ;
VAL_ 2566802174 TransAirSupplyPressIndicator 7 "Not available" 6 "Error indicator" 5 "Not defined" 4 "Over pressure" 3 "No pressure" 2 "Very low pressure" 1 "Low pressure" 0 "Normal Pressure Range" ;
VAL_ 2566802174 TransMode10Indicator 3 "Not available" 2 "Error indicator" 1 "Transmission Mode 10 active" 0 "Transmission Mode 10 not active" ;
VAL_ 2566802174 TransMode9Indicator 3 "Not available" 2 "Error indicator" 1 "Transmission Mode 9 active" 0 "Transmission Mode 9 not active" ;
VAL_ 2633942014 TransForwardDirectionSwitch 3 "Not available" 2 "Error" 1 "On" 0 "Off" ;
VAL_ 2633942014 TransNeutralSwitch 3 "Not available" 2 "Error" 1 "On" 0 "Off" ;
VAL_ 2633942014 TransReverseDirectionSwitch 3 "Not available" 2 "Error" 1 "On" 0 "Off" ;
VAL_ 2633942014 TransLowRangeSenseSwitch 3 "Not available" 2 "Error" 1 "On" 0 "Off" ;
VAL_ 2633942014 TransHighRangeSenseSwitch 3 "Not available" 2 "Error" 1 "On" 0 "Off" ;
VAL_ 2633943038 TransInertiaBrakeActuator 3 "Not available" 2 "Error" 1 "On" 0 "Off" ;
VAL_ 2633943038 TransDefuelActuator 3 "Not available" 2 "Error" 1 "On" 0 "Off" ;
VAL_ 2633943038 TransLockupClutchActuator 3 "Not available" 2 "Error" 1 "On" 0 "Off" ;
VAL_ 2633943038 TransClutchActuator 3 "Not available" 2 "Error" 1 "On" 0 "Off" ;
VAL_ 2633943038 TransSplitterIndirectActuator 3 "Not available" 2 "Error" 1 "On" 0 "Off" ;
VAL_ 2633943038 TransSplitterDirectActuator 3 "Not available" 2 "Error" 1 "On" 0 "Off" ;
VAL_ 2633943038 TransRangeLowActuator 3 "Not available" 2 "Error" 1 "On" 0 "Off" ;
VAL_ 2633943038 TransRangeHighActuator 3 "Not available" 2 "Error" 1 "On" 0 "Off" ;
VAL_ 2633943038 TransShiftFingerGearActuator2 3 "Not available" 2 "Error" 1 "On" 0 "Off" ;
VAL_ 2633943038 TransShiftFingerRailActuator2 3 "Not available" 2 "Error" 1 "On" 0 "Off" ;
VAL_ 2633943038 TransShiftFingerGearActuator1 3 "Not available" 2 "Error" 1 "On" 0 "Off" ;
VAL_ 2633943038 TransShiftFingerRailActuator1 3 "Not available" 2 "Error" 1 "On" 0 "Off" ;
VAL_ 2633943038 TrnsShftFngerCenterRailIndicator 3 "Not available" 2 "Error" 1 "On" 0 "Off" ;
VAL_ 2633943038 TrnsShftFngerEngagementIndicator 3 "Not available" 2 "Error" 1 "On" 0 "Off" ;
VAL_ 2633943038 TransShiftFingerNeutralIndicator 3 "Not available" 2 "Error" 1 "On" 0 "Off" ;
VAL_ 2364539646 MomentaryEngMaxPowerEnable 3 "not available" 2 "fault" 1 "momentarily requesting maximum power available" 0 "not requesting maximum power available" ;
VAL_ 2364539646 ProgressiveShiftDisable 3 "Take no action" 2 "Reserved" 1 "Progressive shift is disabled" 0 "Progressive shift is not disabled" ;
VAL_ 2364539646 EngMomentaryOverspeedEnable 3 "Take no action" 2 "Reserved" 1 "Momentary engine overspeed is enabled" 0 "Momentary engine overspeed is disabled" ;
VAL_ 2364539646 TrnsTrqCnvrtrLckpTrnstnInProcess 3 "Not available" 2 "Error" 1 "Transition is in process" 0 "Transition is not in process" ;
VAL_ 2364539646 TransShiftInProcess 3 "Not available" 2 "Error" 1 "Shift in process" 0 "Shift is not in process" ;
VAL_ 2364539646 TrnsTorqueConverterLockupEngaged 3 "Not available" 2 "Error" 1 "Torque converter lockup engaged" 0 "Torque converter lockup disengaged" ;
VAL_ 2364539646 TransDrivelineEngaged 3 "Not available" 2 "Error" 1 "Driveline engaged" 0 "Driveline disengaged" ;
